VERSION ""

NS_ :

BS_:

BU_: MRRFR External_Tool CADM MRRFL

BO_ 456 MRR_FR_Header_SensorCoverage: 12 MRRFR
 SG_ MRR_FR_Radar_Spec_Status_MC : 75|4@0+ (1,0) [0|15] ""  External_Tool,CADM
 SG_ MRR_FR_Radar_Spec_Status_CRC : 87|16@0+ (1,0) [0|65535] ""  External_Tool,CADM
 SG_ MRR_CAN_RadarWaveform_FR : 79|3@0+ (1,0) [0|7] ""  CADM,External_Tool
 SG_ MRR_FR_CAN_RANGE_COVERAGE : 7|14@0+ (0.015625,0) [0|255.984375] "m"  External_Tool,CADM
 SG_ MRR_FR_CAN_DOPPLER_COVERAGE : 23|14@0+ (0.015625,0) [0|255.984375] "m/s"  External_Tool,CADM
 SG_ MRR_FR_CAN_FOV_HOR : 39|8@0+ (1,0) [0|255] "deg"  External_Tool,CADM
 SG_ MRR_FR_CAN_FOV_VER : 47|8@0+ (1,0) [0|255] "deg"  External_Tool,CADM

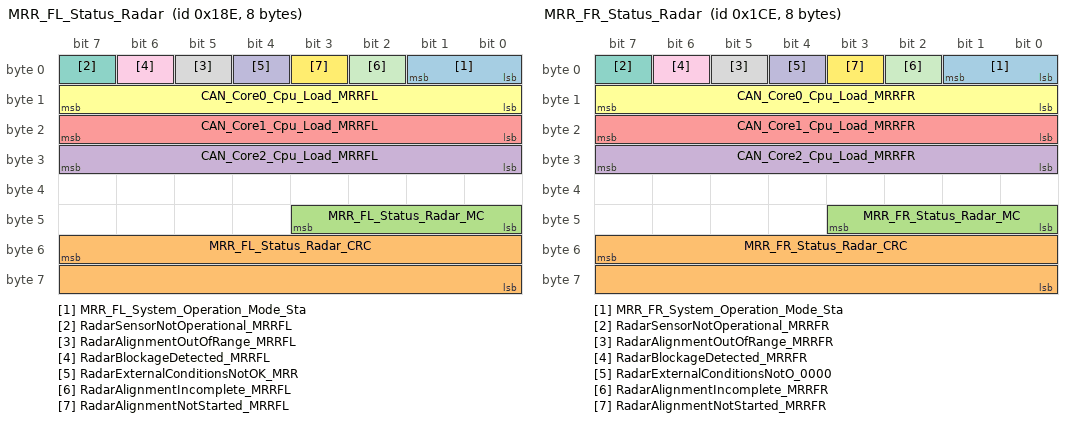
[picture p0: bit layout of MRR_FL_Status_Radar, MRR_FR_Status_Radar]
BO_ 398 MRR_FL_Status_Radar: 8 MRRFL
 SG_ MRR_FL_System_Operation_Mode_Sta : 1|2@0+ (1,0) [0|3] ""  CADM
 SG_ MRR_FL_Status_Radar_CRC : 55|16@0+ (1,0) [0|65535] ""  CADM
 SG_ MRR_FL_Status_Radar_MC : 43|4@0+ (1,0) [0|15] ""  CADM
 SG_ CAN_Core2_Cpu_Load_MRRFL : 31|8@0+ (0.5,0) [0|100] "%"  CADM
 SG_ CAN_Core1_Cpu_Load_MRRFL : 23|8@0+ (0.5,0) [0|100] "%"  CADM
 SG_ CAN_Core0_Cpu_Load_MRRFL : 15|8@0+ (0.5,0) [0|100] "%"  CADM
 SG_ RadarSensorNotOperational_MRRFL : 7|1@0+ (1,0) [0|1] ""  CADM
 SG_ RadarAlignmentOutOfRange_MRRFL : 5|1@0+ (1,0) [0|1] ""  CADM
 SG_ RadarBlockageDetected_MRRFL : 6|1@0+ (1,0) [0|1] ""  CADM
 SG_ RadarExternalConditionsNotOK_MRR : 4|1@0+ (1,0) [0|1] ""  CADM
 SG_ RadarAlignmentIncomplete_MRRFL : 2|1@0+ (1,0) [0|1] ""  CADM
 SG_ RadarAlignmentNotStarted_MRRFL : 3|1@0+ (1,0) [0|1] ""  CADM

BO_ 462 MRR_FR_Status_Radar: 8 MRRFR
 SG_ MRR_FR_System_Operation_Mode_Sta : 1|2@0+ (1,0) [0|3] ""  CADM
 SG_ MRR_FR_Status_Radar_CRC : 55|16@0+ (1,0) [0|65535] ""  CADM
 SG_ MRR_FR_Status_Radar_MC : 43|4@0+ (1,0) [0|15] ""  CADM
 SG_ CAN_Core2_Cpu_Load_MRRFR : 31|8@0+ (0.5,0) [0|100] "%"  CADM
 SG_ CAN_Core1_Cpu_Load_MRRFR : 23|8@0+ (0.5,0) [0|100] "%"  CADM
 SG_ CAN_Core0_Cpu_Load_MRRFR : 15|8@0+ (0.5,0) [0|100] "%"  CADM
 SG_ RadarSensorNotOperational_MRRFR : 7|1@0+ (1,0) [0|1] ""  CADM
 SG_ RadarAlignmentOutOfRange_MRRFR : 5|1@0+ (1,0) [0|1] ""  CADM
 SG_ RadarBlockageDetected_MRRFR : 6|1@0+ (1,0) [0|1] ""  CADM
 SG_ RadarExternalConditionsNotO_0000 : 4|1@0+ (1,0) [0|1] ""  CADM
 SG_ RadarAlignmentIncomplete_MRRFR : 2|1@0+ (1,0) [0|1] ""  CADM
 SG_ RadarAlignmentNotStarted_MRRFR : 3|1@0+ (1,0) [0|1] ""  CADM

BO_ 461 MRR_FR_Status_Temp_Volt: 12 MRRFR
 SG_ MRR_FR_CAN_Dolphin_AFC : 95|8@0+ (1,-50) [-50|205] "C"  CADM,External_Tool
 SG_ MRR_FR_CAN_Dolphin_Tx3 : 87|8@0+ (1,-50) [-50|205] "C"  CADM,External_Tool
 SG_ MRR_FR_CAN_Dolphin_Tx2 : 79|8@0+ (1,-50) [-50|205] "C"  CADM,External_Tool
 SG_ MRR_FR_CAN_1_8_V : 71|8@0+ (0.08,0) [0|20.4] "V"  External_Tool
 SG_ MRR_FR_CAN_BATT_VOLTS : 63|8@0+ (0.08,0) [0|20.4] "V"  External_Tool
 SG_ MRR_FR_CAN_1_25_V : 55|8@0+ (0.08,0) [0|20.4] "V"  External_Tool
 SG_ MRR_FR_CAN_5_V : 47|8@0+ (0.08,0) [0|20.4] "V"  External_Tool
 SG_ MRR_FR_CAN_1_1_V : 31|8@0+ (0.08,0) [0|20.4] "V"  External_Tool
 SG_ MRR_FR_CAN_2_3_V : 15|8@0+ (0.08,0) [0|20.4] "V"  External_Tool
 SG_ MRR_FR_CAN_Dolphin_Tx1 : 39|8@0+ (1,-50) [-50|205] "C"  CADM,External_Tool
 SG_ MRR_FR_CAN_RRU_Temp1 : 7|8@0+ (1,-50) [-50|205] "C"  CADM,External_Tool

BO_ 769 MRR_FL_Detection_008_014: 64 MRRFL
 SG_ MRR_FL_CAN_DET_MID_TARGET_014 : 462|1@0+ (1,0) [0|1] ""  CADM
 SG_ MRR_FL_CAN_DET_MID_TARGET_013 : 461|1@0+ (1,0) [0|1] ""  CADM
 SG_ MRR_FL_CAN_DET_MID_TARGET_012 : 460|1@0+ (1,0) [0|1] ""  CADM
 SG_ MRR_FL_CAN_DET_MID_TARGET_011 : 459|1@0+ (1,0) [0|1] ""  CADM
 SG_ MRR_FL_CAN_DET_MID_TARGET_010 : 458|1@0+ (1,0) [0|1] ""  CADM
 SG_ MRR_FL_CAN_DET_MID_TARGET_009 : 457|1@0+ (1,0) [0|1] ""  CADM
 SG_ MRR_FL_CAN_DET_MID_TARGET_008 : 456|1@0+ (1,0) [0|1] ""  CADM
 SG_ MRR_FL_CAN_DET_Near_TARGET_008 : 448|1@0+ (1,0) [0|1] ""  CADM
 SG_ MRR_FL_CAN_DET_Near_TARGET_009 : 449|1@0+ (1,0) [0|1] ""  CADM
 SG_ MRR_FL_CAN_DET_Near_TARGET_010 : 450|1@0+ (1,0) [0|1] ""  CADM
 SG_ MRR_FL_CAN_DET_Near_TARGET_011 : 451|1@0+ (1,0) [0|1] ""  CADM
 SG_ MRR_FL_CAN_DET_Near_TARGET_012 : 452|1@0+ (1,0) [0|1] ""  CADM
 SG_ MRR_FL_CAN_DET_Near_TARGET_013 : 453|1@0+ (1,0) [0|1] ""  CADM
 SG_ MRR_FL_CAN_DET_Near_TARGET_014 : 454|1@0+ (1,0) [0|1] ""  CADM
 SG_ MRR_FL_CAN_DET_ELEVATION_008 : 63|7@0+ (0.002748,-0.1745) [-0.1745|0.174496] "rad"  CADM
 SG_ MRR_FL_CAN_DET_CONFID_AZIMU_0006 : 33|2@0+ (1,0) [0|3] ""  CADM
 SG_ MRR_FL_CAN_DET_SUPER_RES_TA_0006 : 56|1@0+ (1,0) [0|1] ""  CADM
 SG_ MRR_FL_CAN_DET_CONFID_ELEVA_0006 : 49|1@0+ (1,0) [0|1] ""  CADM
 SG_ MRR_FL_CAN_DET_HOST_VEH_CLU_0006 : 48|1@0+ (1,0) [0|1] ""  CADM
 SG_ MRR_FL_CAN_DET_VALID_LEVEL_008 : 0|1@0+ (1,0) [0|1] ""  CADM
 SG_ MRR_FL_CAN_DET_AZIMUTH_008 : 47|14@0+ (0.0003834,-3.1416) [-3.1416|3.1396422] "rad"  CADM
 SG_ MRR_FL_CAN_DET_RANGE_008 : 31|14@0+ (0.015625,0) [0|255.984375] "m"  CADM
 SG_ MRR_FL_CAN_DET_RANGE_RATE_008 : 15|14@0+ (0.015625,-128) [-128|127.984375] "m/s"  CADM
 SG_ MRR_FL_CAN_DET_AMPLITUDE_008 : 7|7@0+ (1,-64) [-64|63] "dBsm"  CADM
 SG_ MRR_FL_CAN_SCAN_INDEX_2LSB_008 : 17|2@0+ (1,0) [0|3] ""  CADM
 SG_ MRR_FL_DET_MC_002 : 491|4@0+ (1,0) [0|15] ""  CADM
 SG_ MRR_FL_DET_CRC_002 : 503|16@0+ (1,0) [0|65535] ""  CADM
 SG_ MRR_FL_CAN_DET_ELEVATION_014 : 447|7@0+ (0.002748,-0.1745) [-0.1745|0.174496] "rad"  CADM
 SG_ MRR_FL_CAN_DET_SUPER_RES_TA_0007 : 440|1@0+ (1,0) [0|1] ""  CADM
 SG_ MRR_FL_CAN_DET_AZIMUTH_014 : 431|14@0+ (0.0003834,-3.1416) [-3.1416|3.1396422] "rad"  CADM
 SG_ MRR_FL_CAN_DET_CONFID_ELEVA_0007 : 433|1@0+ (1,0) [0|1] ""  CADM
 SG_ MRR_FL_CAN_DET_HOST_VEH_CLU_0007 : 432|1@0+ (1,0) [0|1] ""  CADM
 SG_ MRR_FL_CAN_DET_RANGE_014 : 415|14@0+ (0.015625,0) [0|255.984375] "m"  CADM
 SG_ MRR_FL_CAN_DET_CONFID_AZIMUTH_01 : 417|2@0+ (1,0) [0|3] ""  CADM
 SG_ MRR_FL_CAN_DET_RANGE_RATE_014 : 399|14@0+ (0.015625,-128) [-128|127.984375] "m/s"  CADM
 SG_ MRR_FL_CAN_SCAN_INDEX_2LSB_014 : 401|2@0+ (1,0) [0|3] ""  CADM
 SG_ MRR_FL_CAN_DET_AMPLITUDE_014 : 391|7@0+ (1,-64) [-64|63] "dBsm"  CADM
 SG_ MRR_FL_CAN_DET_VALID_LEVEL_014 : 384|1@0+ (1,0) [0|1] ""  CADM
 SG_ MRR_FL_CAN_DET_ELEVATION_013 : 383|7@0+ (0.002748,-0.1745) [-0.1745|0.174496] "rad"  CADM
 SG_ MRR_FL_CAN_DET_SUPER_RES_TA_0008 : 376|1@0+ (1,0) [0|1] ""  CADM
 SG_ MRR_FL_CAN_DET_AZIMUTH_013 : 367|14@0+ (0.0003834,-3.1416) [-3.1416|3.1396422] "rad"  CADM
 SG_ MRR_FL_CAN_DET_CONFID_ELEVA_0008 : 369|1@0+ (1,0) [0|1] ""  CADM
 SG_ MRR_FL_CAN_DET_HOST_VEH_CLU_0008 : 368|1@0+ (1,0) [0|1] ""  CADM
 SG_ MRR_FL_CAN_DET_RANGE_013 : 351|14@0+ (0.015625,0) [0|255.984375] "m"  CADM
 SG_ MRR_FL_CAN_DET_CONFID_AZIMU_0007 : 353|2@0+ (1,0) [0|3] ""  CADM
 SG_ MRR_FL_CAN_DET_RANGE_RATE_013 : 335|14@0+ (0.015625,-128) [-128|127.984375] "m/s"  CADM
 SG_ MRR_FL_CAN_SCAN_INDEX_2LSB_013 : 337|2@0+ (1,0) [0|3] ""  CADM
 SG_ MRR_FL_CAN_DET_AMPLITUDE_013 : 327|7@0+ (1,-64) [-64|63] "dBsm"  CADM
 SG_ MRR_FL_CAN_DET_VALID_LEVEL_013 : 320|1@0+ (1,0) [0|1] ""  CADM
 SG_ MRR_FL_CAN_DET_ELEVATION_012 : 319|7@0+ (0.002748,-0.1745) [-0.1745|0.174496] "rad"  CADM
 SG_ MRR_FL_CAN_DET_SUPER_RES_TA_0009 : 312|1@0+ (1,0) [0|1] ""  CADM
 SG_ MRR_FL_CAN_DET_AZIMUTH_012 : 303|14@0+ (0.0003834,-3.1416) [-3.1416|3.1396422] "rad"  CADM
 SG_ MRR_FL_CAN_DET_CONFID_ELEVA_0009 : 305|1@0+ (1,0) [0|1] ""  CADM
 SG_ MRR_FL_CAN_DET_HOST_VEH_CLU_0009 : 304|1@0+ (1,0) [0|1] ""  CADM
 SG_ MRR_FL_CAN_DET_RANGE_012 : 287|14@0+ (0.015625,0) [0|255.984375] "m"  CADM
 SG_ MRR_FL_CAN_DET_CONFID_AZIMU_0008 : 289|2@0+ (1,0) [0|3] ""  CADM
 SG_ MRR_FL_CAN_DET_RANGE_RATE_012 : 271|14@0+ (0.015625,-128) [-128|127.984375] "m/s"  CADM
 SG_ MRR_FL_CAN_SCAN_INDEX_2LSB_012 : 273|2@0+ (1,0) [0|3] ""  CADM
 SG_ MRR_FL_CAN_DET_AMPLITUDE_012 : 263|7@0+ (1,-64) [-64|63] "dBsm"  CADM
 SG_ MRR_FL_CAN_DET_VALID_LEVEL_012 : 256|1@0+ (1,0) [0|1] ""  CADM
 SG_ MRR_FL_CAN_DET_ELEVATION_011 : 255|7@0+ (0.002748,-0.1745) [-0.1745|0.174496] "rad"  CADM
 SG_ MRR_FL_CAN_DET_SUPER_RES_TA_0010 : 248|1@0+ (1,0) [0|1] ""  CADM
 SG_ MRR_FL_CAN_DET_AZIMUTH_011 : 239|14@0+ (0.0003834,-3.1416) [-3.1416|3.1396422] "rad"  CADM
 SG_ MRR_FL_CAN_DET_CONFID_ELEVA_0010 : 241|1@0+ (1,0) [0|1] ""  CADM
 SG_ MRR_FL_CAN_DET_HOST_VEH_CLU_0010 : 240|1@0+ (1,0) [0|1] ""  CADM
 SG_ MRR_FL_CAN_DET_RANGE_011 : 223|14@0+ (0.015625,0) [0|255.984375] "m"  CADM
 SG_ MRR_FL_CAN_DET_CONFID_AZIMU_0009 : 225|2@0+ (1,0) [0|3] ""  CADM
 SG_ MRR_FL_CAN_DET_RANGE_RATE_011 : 207|14@0+ (0.015625,-128) [-128|127.984375] "m/s"  CADM
 SG_ MRR_FL_CAN_SCAN_INDEX_2LSB_011 : 209|2@0+ (1,0) [0|3] ""  CADM
 SG_ MRR_FL_CAN_DET_AMPLITUDE_011 : 199|7@0+ (1,-64) [-64|63] "dBsm"  CADM
 SG_ MRR_FL_CAN_DET_VALID_LEVEL_011 : 192|1@0+ (1,0) [0|1] ""  CADM
 SG_ MRR_FL_CAN_DET_ELEVATION_010 : 191|7@0+ (0.002748,-0.1745) [-0.1745|0.174496] "rad"  CADM
 SG_ MRR_FL_CAN_DET_SUPER_RES_TA_0011 : 184|1@0+ (1,0) [0|1] ""  CADM
 SG_ MRR_FL_CAN_DET_AZIMUTH_010 : 175|14@0+ (0.0003834,-3.1416) [-3.1416|3.1396422] "rad"  CADM
 SG_ MRR_FL_CAN_DET_CONFID_ELEVA_0011 : 177|1@0+ (1,0) [0|1] ""  CADM
 SG_ MRR_FL_CAN_DET_HOST_VEH_CLU_0011 : 176|1@0+ (1,0) [0|1] ""  CADM
 SG_ MRR_FL_CAN_DET_RANGE_010 : 159|14@0+ (0.015625,0) [0|255.984375] "m"  CADM
 SG_ MRR_FL_CAN_DET_CONFID_AZIMU_0010 : 161|2@0+ (1,0) [0|3] ""  CADM
 SG_ MRR_FL_CAN_DET_RANGE_RATE_010 : 143|14@0+ (0.015625,-128) [-128|127.984375] "m/s"  CADM
 SG_ MRR_FL_CAN_SCAN_INDEX_2LSB_010 : 145|2@0+ (1,0) [0|3] ""  CADM
 SG_ MRR_FL_CAN_DET_AMPLITUDE_010 : 135|7@0+ (1,-64) [-64|63] "dBsm"  CADM
 SG_ MRR_FL_CAN_DET_VALID_LEVEL_010 : 128|1@0+ (1,0) [0|1] ""  CADM
 SG_ MRR_FL_CAN_DET_ELEVATION_009 : 127|7@0+ (0.002748,-0.1745) [-0.1745|0.174496] "rad"  CADM
 SG_ MRR_FL_CAN_DET_SUPER_RES_TA_0012 : 120|1@0+ (1,0) [0|1] ""  CADM
 SG_ MRR_FL_CAN_DET_AZIMUTH_009 : 111|14@0+ (0.0003834,-3.1416) [-3.1416|3.1396422] "rad"  CADM
 SG_ MRR_FL_CAN_DET_CONFID_ELEVA_0012 : 113|1@0+ (1,0) [0|1] ""  CADM
 SG_ MRR_FL_CAN_DET_HOST_VEH_CLU_0012 : 112|1@0+ (1,0) [0|1] ""  CADM
 SG_ MRR_FL_CAN_DET_RANGE_009 : 95|14@0+ (0.015625,0) [0|255.984375] "m"  CADM
 SG_ MRR_FL_CAN_DET_CONFID_AZIMU_0011 : 97|2@0+ (1,0) [0|3] ""  CADM
 SG_ MRR_FL_CAN_DET_RANGE_RATE_009 : 79|14@0+ (0.015625,-128) [-128|127.984375] "m/s"  CADM
 SG_ MRR_FL_CAN_SCAN_INDEX_2LSB_009 : 81|2@0+ (1,0) [0|3] ""  CADM
 SG_ MRR_FL_CAN_DET_AMPLITUDE_009 : 71|7@0+ (1,-64) [-64|63] "dBsm"  CADM
 SG_ MRR_FL_CAN_DET_VALID_LEVEL_009 : 64|1@0+ (1,0) [0|1] ""  CADM

BO_ 770 MRR_FL_Detection_015_021: 64 MRRFL
 SG_ MRR_FL_CAN_DET_MID_TARGET_021 : 462|1@0+ (1,0) [0|1] ""  CADM
 SG_ MRR_FL_CAN_DET_MID_TARGET_020 : 461|1@0+ (1,0) [0|1] ""  CADM
 SG_ MRR_FL_CAN_DET_MID_TARGET_019 : 460|1@0+ (1,0) [0|1] ""  CADM
 SG_ MRR_FL_CAN_DET_MID_TARGET_018 : 459|1@0+ (1,0) [0|1] ""  CADM
 SG_ MRR_FL_CAN_DET_MID_TARGET_017 : 458|1@0+ (1,0) [0|1] ""  CADM
 SG_ MRR_FL_CAN_DET_MID_TARGET_016 : 457|1@0+ (1,0) [0|1] ""  CADM
 SG_ MRR_FL_CAN_DET_MID_TARGET_015 : 456|1@0+ (1,0) [0|1] ""  CADM
 SG_ MRR_FL_CAN_DET_Near_TARGET_015 : 448|1@0+ (1,0) [0|1] ""  CADM
 SG_ MRR_FL_CAN_DET_Near_TARGET_016 : 449|1@0+ (1,0) [0|1] ""  CADM
 SG_ MRR_FL_CAN_DET_Near_TARGET_017 : 450|1@0+ (1,0) [0|1] ""  CADM
 SG_ MRR_FL_CAN_DET_Near_TARGET_018 : 451|1@0+ (1,0) [0|1] ""  CADM
 SG_ MRR_FL_CAN_DET_Near_TARGET_019 : 452|1@0+ (1,0) [0|1] ""  CADM
 SG_ MRR_FL_CAN_DET_Near_TARGET_020 : 453|1@0+ (1,0) [0|1] ""  CADM
 SG_ MRR_FL_CAN_DET_Near_TARGET_021 : 454|1@0+ (1,0) [0|1] ""  CADM
 SG_ MRR_FL_CAN_DET_ELEVATION_015 : 63|7@0+ (0.002748,-0.1745) [-0.1745|0.174496] "rad"  CADM
 SG_ MRR_FL_CAN_DET_CONFID_AZIMU_0012 : 33|2@0+ (1,0) [0|3] ""  CADM
 SG_ MRR_FL_CAN_DET_SUPER_RES_TA_0013 : 56|1@0+ (1,0) [0|1] ""  CADM
 SG_ MRR_FL_CAN_DET_CONFID_ELEVA_0013 : 49|1@0+ (1,0) [0|1] ""  CADM
 SG_ MRR_FL_CAN_DET_HOST_VEH_CLU_0013 : 48|1@0+ (1,0) [0|1] ""  CADM
 SG_ MRR_FL_CAN_DET_VALID_LEVEL_015 : 0|1@0+ (1,0) [0|1] ""  CADM
 SG_ MRR_FL_CAN_DET_AZIMUTH_015 : 47|14@0+ (0.0003834,-3.1416) [-3.1416|3.1396422] "rad"  CADM
 SG_ MRR_FL_CAN_DET_RANGE_015 : 31|14@0+ (0.015625,0) [0|255.984375] "m"  CADM
 SG_ MRR_FL_CAN_DET_RANGE_RATE_015 : 15|14@0+ (0.015625,-128) [-128|127.984375] "m/s"  CADM
 SG_ MRR_FL_CAN_DET_AMPLITUDE_015 : 7|7@0+ (1,-64) [-64|63] "dBsm"  CADM
 SG_ MRR_FL_CAN_SCAN_INDEX_2LSB_015 : 17|2@0+ (1,0) [0|3] ""  CADM
 SG_ MRR_FL_DET_MC_003 : 491|4@0+ (1,0) [0|15] ""  CADM
 SG_ MRR_FL_DET_CRC_003 : 503|16@0+ (1,0) [0|65535] ""  CADM
 SG_ MRR_FL_CAN_DET_ELEVATION_021 : 447|7@0+ (0.002748,-0.1745) [-0.1745|0.174496] "rad"  CADM
 SG_ MRR_FL_CAN_DET_SUPER_RES_TA_0014 : 440|1@0+ (1,0) [0|1] ""  CADM
 SG_ MRR_FL_CAN_DET_AZIMUTH_021 : 431|14@0+ (0.0003834,-3.1416) [-3.1416|3.1396422] "rad"  CADM
 SG_ MRR_FL_CAN_DET_CONFID_ELEVA_0014 : 433|1@0+ (1,0) [0|1] ""  CADM
 SG_ MRR_FL_CAN_DET_HOST_VEH_CLU_0014 : 432|1@0+ (1,0) [0|1] ""  CADM
 SG_ MRR_FL_CAN_DET_RANGE_021 : 415|14@0+ (0.015625,0) [0|255.984375] "m"  CADM
 SG_ MRR_FL_CAN_DET_CONFID_AZIMUTH_02 : 417|2@0+ (1,0) [0|3] ""  CADM
 SG_ MRR_FL_CAN_DET_RANGE_RATE_021 : 399|14@0+ (0.015625,-128) [-128|127.984375] "m/s"  CADM
 SG_ MRR_FL_CAN_SCAN_INDEX_2LSB_021 : 401|2@0+ (1,0) [0|3] ""  CADM
 SG_ MRR_FL_CAN_DET_AMPLITUDE_021 : 391|7@0+ (1,-64) [-64|63] "dBsm"  CADM
 SG_ MRR_FL_CAN_DET_VALID_LEVEL_021 : 384|1@0+ (1,0) [0|1] ""  CADM
 SG_ MRR_FL_CAN_DET_ELEVATION_020 : 383|7@0+ (0.002748,-0.1745) [-0.1745|0.174496] "rad"  CADM
 SG_ MRR_FL_CAN_DET_SUPER_RES_TA_0015 : 376|1@0+ (1,0) [0|1] ""  CADM
 SG_ MRR_FL_CAN_DET_AZIMUTH_020 : 367|14@0+ (0.0003834,-3.1416) [-3.1416|3.1396422] "rad"  CADM
 SG_ MRR_FL_CAN_DET_CONFID_ELEVA_0015 : 369|1@0+ (1,0) [0|1] ""  CADM
 SG_ MRR_FL_CAN_DET_HOST_VEH_CLU_0015 : 368|1@0+ (1,0) [0|1] ""  CADM
 SG_ MRR_FL_CAN_DET_RANGE_020 : 351|14@0+ (0.015625,0) [0|255.984375] "m"  CADM
 SG_ MRR_FL_CAN_DET_CONFID_AZIMU_0013 : 353|2@0+ (1,0) [0|3] ""  CADM
 SG_ MRR_FL_CAN_DET_RANGE_RATE_020 : 335|14@0+ (0.015625,-128) [-128|127.984375] "m/s"  CADM
 SG_ MRR_FL_CAN_SCAN_INDEX_2LSB_020 : 337|2@0+ (1,0) [0|3] ""  CADM
 SG_ MRR_FL_CAN_DET_AMPLITUDE_020 : 327|7@0+ (1,-64) [-64|63] "dBsm"  CADM
 SG_ MRR_FL_CAN_DET_VALID_LEVEL_020 : 320|1@0+ (1,0) [0|1] ""  CADM
 SG_ MRR_FL_CAN_DET_ELEVATION_019 : 319|7@0+ (0.002748,-0.1745) [-0.1745|0.174496] "rad"  CADM
 SG_ MRR_FL_CAN_DET_SUPER_RES_TA_0016 : 312|1@0+ (1,0) [0|1] ""  CADM
 SG_ MRR_FL_CAN_DET_AZIMUTH_019 : 303|14@0+ (0.0003834,-3.1416) [-3.1416|3.1396422] "rad"  CADM
 SG_ MRR_FL_CAN_DET_CONFID_ELEVA_0016 : 305|1@0+ (1,0) [0|1] ""  CADM
 SG_ MRR_FL_CAN_DET_HOST_VEH_CLU_0016 : 304|1@0+ (1,0) [0|1] ""  CADM
 SG_ MRR_FL_CAN_DET_RANGE_019 : 287|14@0+ (0.015625,0) [0|255.984375] "m"  CADM
 SG_ MRR_FL_CAN_DET_CONFID_AZIMU_0014 : 289|2@0+ (1,0) [0|3] ""  CADM
 SG_ MRR_FL_CAN_DET_RANGE_RATE_019 : 271|14@0+ (0.015625,-128) [-128|127.984375] "m/s"  CADM
 SG_ MRR_FL_CAN_SCAN_INDEX_2LSB_019 : 273|2@0+ (1,0) [0|3] ""  CADM
 SG_ MRR_FL_CAN_DET_AMPLITUDE_019 : 263|7@0+ (1,-64) [-64|63] "dBsm"  CADM
 SG_ MRR_FL_CAN_DET_VALID_LEVEL_019 : 256|1@0+ (1,0) [0|1] ""  CADM
 SG_ MRR_FL_CAN_DET_ELEVATION_018 : 255|7@0+ (0.002748,-0.1745) [-0.1745|0.174496] "rad"  CADM
 SG_ MRR_FL_CAN_DET_SUPER_RES_TA_0017 : 248|1@0+ (1,0) [0|1] ""  CADM
 SG_ MRR_FL_CAN_DET_AZIMUTH_018 : 239|14@0+ (0.0003834,-3.1416) [-3.1416|3.1396422] "rad"  CADM
 SG_ MRR_FL_CAN_DET_CONFID_ELEVA_0017 : 241|1@0+ (1,0) [0|1] ""  CADM
 SG_ MRR_FL_CAN_DET_HOST_VEH_CLU_0017 : 240|1@0+ (1,0) [0|1] ""  CADM
 SG_ MRR_FL_CAN_DET_RANGE_018 : 223|14@0+ (0.015625,0) [0|255.984375] "m"  CADM
 SG_ MRR_FL_CAN_DET_CONFID_AZIMU_0015 : 225|2@0+ (1,0) [0|3] ""  CADM
 SG_ MRR_FL_CAN_DET_RANGE_RATE_018 : 207|14@0+ (0.015625,-128) [-128|127.984375] "m/s"  CADM
 SG_ MRR_FL_CAN_SCAN_INDEX_2LSB_018 : 209|2@0+ (1,0) [0|3] ""  CADM
 SG_ MRR_FL_CAN_DET_AMPLITUDE_018 : 199|7@0+ (1,-64) [-64|63] "dBsm"  CADM
 SG_ MRR_FL_CAN_DET_VALID_LEVEL_018 : 192|1@0+ (1,0) [0|1] ""  CADM
 SG_ MRR_FL_CAN_DET_ELEVATION_017 : 191|7@0+ (0.002748,-0.1745) [-0.1745|0.174496] "rad"  CADM
 SG_ MRR_FL_CAN_DET_SUPER_RES_TA_0018 : 184|1@0+ (1,0) [0|1] ""  CADM
 SG_ MRR_FL_CAN_DET_AZIMUTH_017 : 175|14@0+ (0.0003834,-3.1416) [-3.1416|3.1396422] "rad"  CADM
 SG_ MRR_FL_CAN_DET_CONFID_ELEVA_0018 : 177|1@0+ (1,0) [0|1] ""  CADM
 SG_ MRR_FL_CAN_DET_HOST_VEH_CLU_0018 : 176|1@0+ (1,0) [0|1] ""  CADM
 SG_ MRR_FL_CAN_DET_RANGE_017 : 159|14@0+ (0.015625,0) [0|255.984375] "m"  CADM
 SG_ MRR_FL_CAN_DET_CONFID_AZIMU_0016 : 161|2@0+ (1,0) [0|3] ""  CADM
 SG_ MRR_FL_CAN_DET_RANGE_RATE_017 : 143|14@0+ (0.015625,-128) [-128|127.984375] "m/s"  CADM
 SG_ MRR_FL_CAN_SCAN_INDEX_2LSB_017 : 145|2@0+ (1,0) [0|3] ""  CADM
 SG_ MRR_FL_CAN_DET_AMPLITUDE_017 : 135|7@0+ (1,-64) [-64|63] "dBsm"  CADM
 SG_ MRR_FL_CAN_DET_VALID_LEVEL_017 : 128|1@0+ (1,0) [0|1] ""  CADM
 SG_ MRR_FL_CAN_DET_ELEVATION_016 : 127|7@0+ (0.002748,-0.1745) [-0.1745|0.174496] "rad"  CADM
 SG_ MRR_FL_CAN_DET_SUPER_RES_TA_0019 : 120|1@0+ (1,0) [0|1] ""  CADM
 SG_ MRR_FL_CAN_DET_AZIMUTH_016 : 111|14@0+ (0.0003834,-3.1416) [-3.1416|3.1396422] "rad"  CADM
 SG_ MRR_FL_CAN_DET_CONFID_ELEVA_0019 : 113|1@0+ (1,0) [0|1] ""  CADM
 SG_ MRR_FL_CAN_DET_HOST_VEH_CLU_0019 : 112|1@0+ (1,0) [0|1] ""  CADM
 SG_ MRR_FL_CAN_DET_RANGE_016 : 95|14@0+ (0.015625,0) [0|255.984375] "m"  CADM
 SG_ MRR_FL_CAN_DET_CONFID_AZIMU_0017 : 97|2@0+ (1,0) [0|3] ""  CADM
 SG_ MRR_FL_CAN_DET_RANGE_RATE_016 : 79|14@0+ (0.015625,-128) [-128|127.984375] "m/s"  CADM
 SG_ MRR_FL_CAN_SCAN_INDEX_2LSB_016 : 81|2@0+ (1,0) [0|3] ""  CADM
 SG_ MRR_FL_CAN_DET_AMPLITUDE_016 : 71|7@0+ (1,-64) [-64|63] "dBsm"  CADM
 SG_ MRR_FL_CAN_DET_VALID_LEVEL_016 : 64|1@0+ (1,0) [0|1] ""  CADM

BO_ 771 MRR_FL_Detection_022_028: 64 MRRFL
 SG_ MRR_FL_CAN_DET_MID_TARGET_028 : 462|1@0+ (1,0) [0|1] ""  CADM
 SG_ MRR_FL_CAN_DET_MID_TARGET_027 : 461|1@0+ (1,0) [0|1] ""  CADM
 SG_ MRR_FL_CAN_DET_MID_TARGET_026 : 460|1@0+ (1,0) [0|1] ""  CADM
 SG_ MRR_FL_CAN_DET_MID_TARGET_025 : 459|1@0+ (1,0) [0|1] ""  CADM
 SG_ MRR_FL_CAN_DET_MID_TARGET_024 : 458|1@0+ (1,0) [0|1] ""  CADM
 SG_ MRR_FL_CAN_DET_MID_TARGET_023 : 457|1@0+ (1,0) [0|1] ""  CADM
 SG_ MRR_FL_CAN_DET_MID_TARGET_022 : 456|1@0+ (1,0) [0|1] ""  CADM
 SG_ MRR_FL_CAN_DET_Near_TARGET_022 : 448|1@0+ (1,0) [0|1] ""  CADM
 SG_ MRR_FL_CAN_DET_Near_TARGET_023 : 449|1@0+ (1,0) [0|1] ""  CADM
 SG_ MRR_FL_CAN_DET_Near_TARGET_024 : 450|1@0+ (1,0) [0|1] ""  CADM
 SG_ MRR_FL_CAN_DET_Near_TARGET_025 : 451|1@0+ (1,0) [0|1] ""  CADM
 SG_ MRR_FL_CAN_DET_Near_TARGET_026 : 452|1@0+ (1,0) [0|1] ""  CADM
 SG_ MRR_FL_CAN_DET_Near_TARGET_027 : 453|1@0+ (1,0) [0|1] ""  CADM
 SG_ MRR_FL_CAN_DET_Near_TARGET_028 : 454|1@0+ (1,0) [0|1] ""  CADM
 SG_ MRR_FL_CAN_DET_ELEVATION_022 : 63|7@0+ (0.002748,-0.1745) [-0.1745|0.174496] "rad"  CADM
 SG_ MRR_FL_CAN_DET_CONFID_AZIMU_0018 : 33|2@0+ (1,0) [0|3] ""  CADM
 SG_ MRR_FL_CAN_DET_SUPER_RES_TA_0020 : 56|1@0+ (1,0) [0|1] ""  CADM
 SG_ MRR_FL_CAN_DET_CONFID_ELEVA_0020 : 49|1@0+ (1,0) [0|1] ""  CADM
 SG_ MRR_FL_CAN_DET_HOST_VEH_CLU_0020 : 48|1@0+ (1,0) [0|1] ""  CADM
 SG_ MRR_FL_CAN_DET_VALID_LEVEL_022 : 0|1@0+ (1,0) [0|1] ""  CADM
 SG_ MRR_FL_CAN_DET_AZIMUTH_022 : 47|14@0+ (0.0003834,-3.1416) [-3.1416|3.1396422] "rad"  CADM
 SG_ MRR_FL_CAN_DET_RANGE_022 : 31|14@0+ (0.015625,0) [0|255.984375] "m"  CADM
 SG_ MRR_FL_CAN_DET_RANGE_RATE_022 : 15|14@0+ (0.015625,-128) [-128|127.984375] "m/s"  CADM
 SG_ MRR_FL_CAN_DET_AMPLITUDE_022 : 7|7@0+ (1,-64) [-64|63] "dBsm"  CADM
 SG_ MRR_FL_CAN_SCAN_INDEX_2LSB_022 : 17|2@0+ (1,0) [0|3] ""  CADM
 SG_ MRR_FL_DET_MC_004 : 491|4@0+ (1,0) [0|15] ""  CADM
 SG_ MRR_FL_DET_CRC_004 : 503|16@0+ (1,0) [0|65535] ""  CADM
 SG_ MRR_FL_CAN_DET_ELEVATION_028 : 447|7@0+ (0.002748,-0.1745) [-0.1745|0.174496] "rad"  CADM
 SG_ MRR_FL_CAN_DET_SUPER_RES_TA_0021 : 440|1@0+ (1,0) [0|1] ""  CADM
 SG_ MRR_FL_CAN_DET_AZIMUTH_028 : 431|14@0+ (0.0003834,-3.1416) [-3.1416|3.1396422] "rad"  CADM
 SG_ MRR_FL_CAN_DET_CONFID_ELEVA_0021 : 433|1@0+ (1,0) [0|1] ""  CADM
 SG_ MRR_FL_CAN_DET_HOST_VEH_CLU_0021 : 432|1@0+ (1,0) [0|1] ""  CADM
 SG_ MRR_FL_CAN_DET_RANGE_028 : 415|14@0+ (0.015625,0) [0|255.984375] "m"  CADM
 SG_ MRR_FL_CAN_DET_CONFID_AZIMU_0019 : 417|2@0+ (1,0) [0|3] ""  CADM
 SG_ MRR_FL_CAN_DET_RANGE_RATE_028 : 399|14@0+ (0.015625,-128) [-128|127.984375] "m/s"  CADM
 SG_ MRR_FL_CAN_SCAN_INDEX_2LSB_028 : 401|2@0+ (1,0) [0|3] ""  CADM
 SG_ MRR_FL_CAN_DET_AMPLITUDE_028 : 391|7@0+ (1,-64) [-64|63] "dBsm"  CADM
 SG_ MRR_FL_CAN_DET_VALID_LEVEL_028 : 384|1@0+ (1,0) [0|1] ""  CADM
 SG_ MRR_FL_CAN_DET_ELEVATION_027 : 383|7@0+ (0.002748,-0.1745) [-0.1745|0.174496] "rad"  CADM
 SG_ MRR_FL_CAN_DET_SUPER_RES_TA_0022 : 376|1@0+ (1,0) [0|1] ""  CADM
 SG_ MRR_FL_CAN_DET_AZIMUTH_027 : 367|14@0+ (0.0003834,-3.1416) [-3.1416|3.1396422] "rad"  CADM
 SG_ MRR_FL_CAN_DET_CONFID_ELEVA_0022 : 369|1@0+ (1,0) [0|1] ""  CADM
 SG_ MRR_FL_CAN_DET_HOST_VEH_CLU_0022 : 368|1@0+ (1,0) [0|1] ""  CADM
 SG_ MRR_FL_CAN_DET_RANGE_027 : 351|14@0+ (0.015625,0) [0|255.984375] "m"  CADM
 SG_ MRR_FL_CAN_DET_CONFID_AZIMU_0020 : 353|2@0+ (1,0) [0|3] ""  CADM
 SG_ MRR_FL_CAN_DET_RANGE_RATE_027 : 335|14@0+ (0.015625,-128) [-128|127.984375] "m/s"  CADM
 SG_ MRR_FL_CAN_SCAN_INDEX_2LSB_027 : 337|2@0+ (1,0) [0|3] ""  CADM
 SG_ MRR_FL_CAN_DET_AMPLITUDE_027 : 327|7@0+ (1,-64) [-64|63] "dBsm"  CADM
 SG_ MRR_FL_CAN_DET_VALID_LEVEL_027 : 320|1@0+ (1,0) [0|1] ""  CADM
 SG_ MRR_FL_CAN_DET_ELEVATION_026 : 319|7@0+ (0.002748,-0.1745) [-0.1745|0.174496] "rad"  CADM
 SG_ MRR_FL_CAN_DET_SUPER_RES_TA_0023 : 312|1@0+ (1,0) [0|1] ""  CADM
 SG_ MRR_FL_CAN_DET_AZIMUTH_026 : 303|14@0+ (0.0003834,-3.1416) [-3.1416|3.1396422] "rad"  CADM
 SG_ MRR_FL_CAN_DET_CONFID_ELEVA_0023 : 305|1@0+ (1,0) [0|1] ""  CADM
 SG_ MRR_FL_CAN_DET_HOST_VEH_CLU_0023 : 304|1@0+ (1,0) [0|1] ""  CADM
 SG_ MRR_FL_CAN_DET_RANGE_026 : 287|14@0+ (0.015625,0) [0|255.984375] "m"  CADM
 SG_ MRR_FL_CAN_DET_CONFID_AZIMU_0021 : 289|2@0+ (1,0) [0|3] ""  CADM
 SG_ MRR_FL_CAN_DET_RANGE_RATE_026 : 271|14@0+ (0.015625,-128) [-128|127.984375] "m/s"  CADM
 SG_ MRR_FL_CAN_SCAN_INDEX_2LSB_026 : 273|2@0+ (1,0) [0|3] ""  CADM
 SG_ MRR_FL_CAN_DET_AMPLITUDE_026 : 263|7@0+ (1,-64) [-64|63] "dBsm"  CADM
 SG_ MRR_FL_CAN_DET_VALID_LEVEL_026 : 256|1@0+ (1,0) [0|1] ""  CADM
 SG_ MRR_FL_CAN_DET_ELEVATION_025 : 255|7@0+ (0.002748,-0.1745) [-0.1745|0.174496] "rad"  CADM
 SG_ MRR_FL_CAN_DET_SUPER_RES_TA_0024 : 248|1@0+ (1,0) [0|1] ""  CADM
 SG_ MRR_FL_CAN_DET_AZIMUTH_025 : 239|14@0+ (0.0003834,-3.1416) [-3.1416|3.1396422] "rad"  CADM
 SG_ MRR_FL_CAN_DET_CONFID_ELEVA_0024 : 241|1@0+ (1,0) [0|1] ""  CADM
 SG_ MRR_FL_CAN_DET_HOST_VEH_CLU_0024 : 240|1@0+ (1,0) [0|1] ""  CADM
 SG_ MRR_FL_CAN_DET_RANGE_025 : 223|14@0+ (0.015625,0) [0|255.984375] "m"  CADM
 SG_ MRR_FL_CAN_DET_CONFID_AZIMU_0022 : 225|2@0+ (1,0) [0|3] ""  CADM
 SG_ MRR_FL_CAN_DET_RANGE_RATE_025 : 207|14@0+ (0.015625,-128) [-128|127.984375] "m/s"  CADM
 SG_ MRR_FL_CAN_SCAN_INDEX_2LSB_025 : 209|2@0+ (1,0) [0|3] ""  CADM
 SG_ MRR_FL_CAN_DET_AMPLITUDE_025 : 199|7@0+ (1,-64) [-64|63] "dBsm"  CADM
 SG_ MRR_FL_CAN_DET_VALID_LEVEL_025 : 192|1@0+ (1,0) [0|1] ""  CADM
 SG_ MRR_FL_CAN_DET_ELEVATION_024 : 191|7@0+ (0.002748,-0.1745) [-0.1745|0.174496] "rad"  CADM
 SG_ MRR_FL_CAN_DET_SUPER_RES_TA_0025 : 184|1@0+ (1,0) [0|1] ""  CADM
 SG_ MRR_FL_CAN_DET_AZIMUTH_024 : 175|14@0+ (0.0003834,-3.1416) [-3.1416|3.1396422] "rad"  CADM
 SG_ MRR_FL_CAN_DET_CONFID_ELEVA_0025 : 177|1@0+ (1,0) [0|1] ""  CADM
 SG_ MRR_FL_CAN_DET_HOST_VEH_CLU_0025 : 176|1@0+ (1,0) [0|1] ""  CADM
 SG_ MRR_FL_CAN_DET_RANGE_024 : 159|14@0+ (0.015625,0) [0|255.984375] "m"  CADM
 SG_ MRR_FL_CAN_DET_CONFID_AZIMU_0023 : 161|2@0+ (1,0) [0|3] ""  CADM
 SG_ MRR_FL_CAN_DET_RANGE_RATE_024 : 143|14@0+ (0.015625,-128) [-128|127.984375] "m/s"  CADM
 SG_ MRR_FL_CAN_SCAN_INDEX_2LSB_024 : 145|2@0+ (1,0) [0|3] ""  CADM
 SG_ MRR_FL_CAN_DET_AMPLITUDE_024 : 135|7@0+ (1,-64) [-64|63] "dBsm"  CADM
 SG_ MRR_FL_CAN_DET_VALID_LEVEL_024 : 128|1@0+ (1,0) [0|1] ""  CADM
 SG_ MRR_FL_CAN_DET_ELEVATION_023 : 127|7@0+ (0.002748,-0.1745) [-0.1745|0.174496] "rad"  CADM
 SG_ MRR_FL_CAN_DET_SUPER_RES_TA_0026 : 120|1@0+ (1,0) [0|1] ""  CADM
 SG_ MRR_FL_CAN_DET_AZIMUTH_023 : 111|14@0+ (0.0003834,-3.1416) [-3.1416|3.1396422] "rad"  CADM
 SG_ MRR_FL_CAN_DET_CONFID_ELEVA_0026 : 113|1@0+ (1,0) [0|1] ""  CADM
 SG_ MRR_FL_CAN_DET_HOST_VEH_CLU_0026 : 112|1@0+ (1,0) [0|1] ""  CADM
 SG_ MRR_FL_CAN_DET_RANGE_023 : 95|14@0+ (0.015625,0) [0|255.984375] "m"  CADM
 SG_ MRR_FL_CAN_DET_CONFID_AZIMU_0024 : 97|2@0+ (1,0) [0|3] ""  CADM
 SG_ MRR_FL_CAN_DET_RANGE_RATE_023 : 79|14@0+ (0.015625,-128) [-128|127.984375] "m/s"  CADM
 SG_ MRR_FL_CAN_SCAN_INDEX_2LSB_023 : 81|2@0+ (1,0) [0|3] ""  CADM
 SG_ MRR_FL_CAN_DET_AMPLITUDE_023 : 71|7@0+ (1,-64) [-64|63] "dBsm"  CADM
 SG_ MRR_FL_CAN_DET_VALID_LEVEL_023 : 64|1@0+ (1,0) [0|1] ""  CADM

BO_ 772 MRR_FL_Detection_029_035: 64 MRRFL
 SG_ MRR_FL_CAN_DET_MID_TARGET_035 : 462|1@0+ (1,0) [0|1] ""  CADM
 SG_ MRR_FL_CAN_DET_MID_TARGET_034 : 461|1@0+ (1,0) [0|1] ""  CADM
 SG_ MRR_FL_CAN_DET_MID_TARGET_033 : 460|1@0+ (1,0) [0|1] ""  CADM
 SG_ MRR_FL_CAN_DET_MID_TARGET_032 : 459|1@0+ (1,0) [0|1] ""  CADM
 SG_ MRR_FL_CAN_DET_MID_TARGET_031 : 458|1@0+ (1,0) [0|1] ""  CADM
 SG_ MRR_FL_CAN_DET_MID_TARGET_030 : 457|1@0+ (1,0) [0|1] ""  CADM
 SG_ MRR_FL_CAN_DET_MID_TARGET_029 : 456|1@0+ (1,0) [0|1] ""  CADM
 SG_ MRR_FL_CAN_DET_Near_TARGET_029 : 448|1@0+ (1,0) [0|1] ""  CADM
 SG_ MRR_FL_CAN_DET_Near_TARGET_030 : 449|1@0+ (1,0) [0|1] ""  CADM
 SG_ MRR_FL_CAN_DET_Near_TARGET_031 : 450|1@0+ (1,0) [0|1] ""  CADM
 SG_ MRR_FL_CAN_DET_Near_TARGET_032 : 451|1@0+ (1,0) [0|1] ""  CADM
 SG_ MRR_FL_CAN_DET_Near_TARGET_033 : 452|1@0+ (1,0) [0|1] ""  CADM
 SG_ MRR_FL_CAN_DET_Near_TARGET_034 : 453|1@0+ (1,0) [0|1] ""  CADM
 SG_ MRR_FL_CAN_DET_Near_TARGET_035 : 454|1@0+ (1,0) [0|1] ""  CADM
 SG_ MRR_FL_CAN_DET_ELEVATION_029 : 63|7@0+ (0.002748,-0.1745) [-0.1745|0.174496] "rad"  CADM
 SG_ MRR_FL_CAN_DET_CONFID_AZIMU_0025 : 33|2@0+ (1,0) [0|3] ""  CADM
 SG_ MRR_FL_CAN_DET_SUPER_RES_TA_0027 : 56|1@0+ (1,0) [0|1] ""  CADM
 SG_ MRR_FL_CAN_DET_CONFID_ELEVA_0027 : 49|1@0+ (1,0) [0|1] ""  CADM
 SG_ MRR_FL_CAN_DET_HOST_VEH_CLU_0027 : 48|1@0+ (1,0) [0|1] ""  CADM
 SG_ MRR_FL_CAN_DET_VALID_LEVEL_029 : 0|1@0+ (1,0) [0|1] ""  CADM
 SG_ MRR_FL_CAN_DET_AZIMUTH_029 : 47|14@0+ (0.0003834,-3.1416) [-3.1416|3.1396422] "rad"  CADM
 SG_ MRR_FL_CAN_DET_RANGE_029 : 31|14@0+ (0.015625,0) [0|255.984375] "m"  CADM
 SG_ MRR_FL_CAN_DET_RANGE_RATE_029 : 15|14@0+ (0.015625,-128) [-128|127.984375] "m/s"  CADM
 SG_ MRR_FL_CAN_DET_AMPLITUDE_029 : 7|7@0+ (1,-64) [-64|63] "dBsm"  CADM
 SG_ MRR_FL_CAN_SCAN_INDEX_2LSB_029 : 17|2@0+ (1,0) [0|3] ""  CADM
 SG_ MRR_FL_DET_MC_005 : 491|4@0+ (1,0) [0|15] ""  CADM
 SG_ MRR_FL_DET_CRC_005 : 503|16@0+ (1,0) [0|65535] ""  CADM
 SG_ MRR_FL_CAN_DET_ELEVATION_035 : 447|7@0+ (0.002748,-0.1745) [-0.1745|0.174496] "rad"  CADM
 SG_ MRR_FL_CAN_DET_SUPER_RES_TA_0028 : 440|1@0+ (1,0) [0|1] ""  CADM
 SG_ MRR_FL_CAN_DET_AZIMUTH_035 : 431|14@0+ (0.0003834,-3.1416) [-3.1416|3.1396422] "rad"  CADM
 SG_ MRR_FL_CAN_DET_CONFID_ELEVA_0028 : 433|1@0+ (1,0) [0|1] ""  CADM
 SG_ MRR_FL_CAN_DET_HOST_VEH_CLU_0028 : 432|1@0+ (1,0) [0|1] ""  CADM
 SG_ MRR_FL_CAN_DET_RANGE_035 : 415|14@0+ (0.015625,0) [0|255.984375] "m"  CADM
 SG_ MRR_FL_CAN_DET_CONFID_AZIMUTH_03 : 417|2@0+ (1,0) [0|3] ""  CADM
 SG_ MRR_FL_CAN_DET_RANGE_RATE_035 : 399|14@0+ (0.015625,-128) [-128|127.984375] "m/s"  CADM
 SG_ MRR_FL_CAN_SCAN_INDEX_2LSB_035 : 401|2@0+ (1,0) [0|3] ""  CADM
 SG_ MRR_FL_CAN_DET_AMPLITUDE_035 : 391|7@0+ (1,-64) [-64|63] "dBsm"  CADM
 SG_ MRR_FL_CAN_DET_VALID_LEVEL_035 : 384|1@0+ (1,0) [0|1] ""  CADM
 SG_ MRR_FL_CAN_DET_ELEVATION_034 : 383|7@0+ (0.002748,-0.1745) [-0.1745|0.174496] "rad"  CADM
 SG_ MRR_FL_CAN_DET_SUPER_RES_TA_0029 : 376|1@0+ (1,0) [0|1] ""  CADM
 SG_ MRR_FL_CAN_DET_AZIMUTH_034 : 367|14@0+ (0.0003834,-3.1416) [-3.1416|3.1396422] "rad"  CADM
 SG_ MRR_FL_CAN_DET_CONFID_ELEVA_0029 : 369|1@0+ (1,0) [0|1] ""  CADM
 SG_ MRR_FL_CAN_DET_HOST_VEH_CLU_0029 : 368|1@0+ (1,0) [0|1] ""  CADM
 SG_ MRR_FL_CAN_DET_RANGE_034 : 351|14@0+ (0.015625,0) [0|255.984375] "m"  CADM
 SG_ MRR_FL_CAN_DET_CONFID_AZIMU_0026 : 353|2@0+ (1,0) [0|3] ""  CADM
 SG_ MRR_FL_CAN_DET_RANGE_RATE_034 : 335|14@0+ (0.015625,-128) [-128|127.984375] "m/s"  CADM
 SG_ MRR_FL_CAN_SCAN_INDEX_2LSB_034 : 337|2@0+ (1,0) [0|3] ""  CADM
 SG_ MRR_FL_CAN_DET_AMPLITUDE_034 : 327|7@0+ (1,-64) [-64|63] "dBsm"  CADM
 SG_ MRR_FL_CAN_DET_VALID_LEVEL_034 : 320|1@0+ (1,0) [0|1] ""  CADM
 SG_ MRR_FL_CAN_DET_ELEVATION_033 : 319|7@0+ (0.002748,-0.1745) [-0.1745|0.174496] "rad"  CADM
 SG_ MRR_FL_CAN_DET_SUPER_RES_TA_0030 : 312|1@0+ (1,0) [0|1] ""  CADM
 SG_ MRR_FL_CAN_DET_AZIMUTH_033 : 303|14@0+ (0.0003834,-3.1416) [-3.1416|3.1396422] "rad"  CADM
 SG_ MRR_FL_CAN_DET_CONFID_ELEVA_0030 : 305|1@0+ (1,0) [0|1] ""  CADM
 SG_ MRR_FL_CAN_DET_HOST_VEH_CLU_0030 : 304|1@0+ (1,0) [0|1] ""  CADM
 SG_ MRR_FL_CAN_DET_RANGE_033 : 287|14@0+ (0.015625,0) [0|255.984375] "m"  CADM
 SG_ MRR_FL_CAN_DET_CONFID_AZIMU_0027 : 289|2@0+ (1,0) [0|3] ""  CADM
 SG_ MRR_FL_CAN_DET_RANGE_RATE_033 : 271|14@0+ (0.015625,-128) [-128|127.984375] "m/s"  CADM
 SG_ MRR_FL_CAN_SCAN_INDEX_2LSB_033 : 273|2@0+ (1,0) [0|3] ""  CADM
 SG_ MRR_FL_CAN_DET_AMPLITUDE_033 : 263|7@0+ (1,-64) [-64|63] "dBsm"  CADM
 SG_ MRR_FL_CAN_DET_VALID_LEVEL_033 : 256|1@0+ (1,0) [0|1] ""  CADM
 SG_ MRR_FL_CAN_DET_ELEVATION_032 : 255|7@0+ (0.002748,-0.1745) [-0.1745|0.174496] "rad"  CADM
 SG_ MRR_FL_CAN_DET_SUPER_RES_TA_0031 : 248|1@0+ (1,0) [0|1] ""  CADM
 SG_ MRR_FL_CAN_DET_AZIMUTH_032 : 239|14@0+ (0.0003834,-3.1416) [-3.1416|3.1396422] "rad"  CADM
 SG_ MRR_FL_CAN_DET_CONFID_ELEVA_0031 : 241|1@0+ (1,0) [0|1] ""  CADM
 SG_ MRR_FL_CAN_DET_HOST_VEH_CLU_0031 : 240|1@0+ (1,0) [0|1] ""  CADM
 SG_ MRR_FL_CAN_DET_RANGE_032 : 223|14@0+ (0.015625,0) [0|255.984375] "m"  CADM
 SG_ MRR_FL_CAN_DET_CONFID_AZIMU_0028 : 225|2@0+ (1,0) [0|3] ""  CADM
 SG_ MRR_FL_CAN_DET_RANGE_RATE_032 : 207|14@0+ (0.015625,-128) [-128|127.984375] "m/s"  CADM
 SG_ MRR_FL_CAN_SCAN_INDEX_2LSB_032 : 209|2@0+ (1,0) [0|3] ""  CADM
 SG_ MRR_FL_CAN_DET_AMPLITUDE_032 : 199|7@0+ (1,-64) [-64|63] "dBsm"  CADM
 SG_ MRR_FL_CAN_DET_VALID_LEVEL_032 : 192|1@0+ (1,0) [0|1] ""  CADM
 SG_ MRR_FL_CAN_DET_ELEVATION_031 : 191|7@0+ (0.002748,-0.1745) [-0.1745|0.174496] "rad"  CADM
 SG_ MRR_FL_CAN_DET_SUPER_RES_TA_0032 : 184|1@0+ (1,0) [0|1] ""  CADM
 SG_ MRR_FL_CAN_DET_AZIMUTH_031 : 175|14@0+ (0.0003834,-3.1416) [-3.1416|3.1396422] "rad"  CADM
 SG_ MRR_FL_CAN_DET_CONFID_ELEVA_0032 : 177|1@0+ (1,0) [0|1] ""  CADM
 SG_ MRR_FL_CAN_DET_HOST_VEH_CLU_0032 : 176|1@0+ (1,0) [0|1] ""  CADM
 SG_ MRR_FL_CAN_DET_RANGE_031 : 159|14@0+ (0.015625,0) [0|255.984375] "m"  CADM
 SG_ MRR_FL_CAN_DET_CONFID_AZIMU_0029 : 161|2@0+ (1,0) [0|3] ""  CADM
 SG_ MRR_FL_CAN_DET_RANGE_RATE_031 : 143|14@0+ (0.015625,-128) [-128|127.984375] "m/s"  CADM
 SG_ MRR_FL_CAN_SCAN_INDEX_2LSB_031 : 145|2@0+ (1,0) [0|3] ""  CADM
 SG_ MRR_FL_CAN_DET_AMPLITUDE_031 : 135|7@0+ (1,-64) [-64|63] "dBsm"  CADM
 SG_ MRR_FL_CAN_DET_VALID_LEVEL_031 : 128|1@0+ (1,0) [0|1] ""  CADM
 SG_ MRR_FL_CAN_DET_ELEVATION_030 : 127|7@0+ (0.002748,-0.1745) [-0.1745|0.174496] "rad"  CADM
 SG_ MRR_FL_CAN_DET_SUPER_RES_TA_0033 : 120|1@0+ (1,0) [0|1] ""  CADM
 SG_ MRR_FL_CAN_DET_AZIMUTH_030 : 111|14@0+ (0.0003834,-3.1416) [-3.1416|3.1396422] "rad"  CADM
 SG_ MRR_FL_CAN_DET_CONFID_ELEVA_0033 : 113|1@0+ (1,0) [0|1] ""  CADM
 SG_ MRR_FL_CAN_DET_HOST_VEH_CLU_0033 : 112|1@0+ (1,0) [0|1] ""  CADM
 SG_ MRR_FL_CAN_DET_RANGE_030 : 95|14@0+ (0.015625,0) [0|255.984375] "m"  CADM
 SG_ MRR_FL_CAN_DET_CONFID_AZIMU_0030 : 97|2@0+ (1,0) [0|3] ""  CADM
 SG_ MRR_FL_CAN_DET_RANGE_RATE_030 : 79|14@0+ (0.015625,-128) [-128|127.984375] "m/s"  CADM
 SG_ MRR_FL_CAN_SCAN_INDEX_2LSB_030 : 81|2@0+ (1,0) [0|3] ""  CADM
 SG_ MRR_FL_CAN_DET_AMPLITUDE_030 : 71|7@0+ (1,-64) [-64|63] "dBsm"  CADM
 SG_ MRR_FL_CAN_DET_VALID_LEVEL_030 : 64|1@0+ (1,0) [0|1] ""  CADM

BO_ 773 MRR_FL_Detection_036_042: 64 MRRFL
 SG_ MRR_FL_CAN_DET_MID_TARGET_042 : 462|1@0+ (1,0) [0|1] ""  CADM
 SG_ MRR_FL_CAN_DET_MID_TARGET_041 : 461|1@0+ (1,0) [0|1] ""  CADM
 SG_ MRR_FL_CAN_DET_MID_TARGET_040 : 460|1@0+ (1,0) [0|1] ""  CADM
 SG_ MRR_FL_CAN_DET_MID_TARGET_039 : 459|1@0+ (1,0) [0|1] ""  CADM
 SG_ MRR_FL_CAN_DET_MID_TARGET_038 : 458|1@0+ (1,0) [0|1] ""  CADM
 SG_ MRR_FL_CAN_DET_MID_TARGET_037 : 457|1@0+ (1,0) [0|1] ""  CADM
 SG_ MRR_FL_CAN_DET_MID_TARGET_036 : 456|1@0+ (1,0) [0|1] ""  CADM
 SG_ MRR_FL_CAN_DET_Near_TARGET_036 : 448|1@0+ (1,0) [0|1] ""  CADM
 SG_ MRR_FL_CAN_DET_Near_TARGET_037 : 449|1@0+ (1,0) [0|1] ""  CADM
 SG_ MRR_FL_CAN_DET_Near_TARGET_038 : 450|1@0+ (1,0) [0|1] ""  CADM
 SG_ MRR_FL_CAN_DET_Near_TARGET_039 : 451|1@0+ (1,0) [0|1] ""  CADM
 SG_ MRR_FL_CAN_DET_Near_TARGET_040 : 452|1@0+ (1,0) [0|1] ""  CADM
 SG_ MRR_FL_CAN_DET_Near_TARGET_041 : 453|1@0+ (1,0) [0|1] ""  CADM
 SG_ MRR_FL_CAN_DET_Near_TARGET_042 : 454|1@0+ (1,0) [0|1] ""  CADM
 SG_ MRR_FL_CAN_DET_ELEVATION_036 : 63|7@0+ (0.002748,-0.1745) [-0.1745|0.174496] "rad"  CADM
 SG_ MRR_FL_CAN_DET_CONFID_AZIMU_0031 : 33|2@0+ (1,0) [0|3] ""  CADM
 SG_ MRR_FL_CAN_DET_SUPER_RES_TA_0034 : 56|1@0+ (1,0) [0|1] ""  CADM
 SG_ MRR_FL_CAN_DET_CONFID_ELEVA_0034 : 49|1@0+ (1,0) [0|1] ""  CADM
 SG_ MRR_FL_CAN_DET_HOST_VEH_CLU_0034 : 48|1@0+ (1,0) [0|1] ""  CADM
 SG_ MRR_FL_CAN_DET_VALID_LEVEL_036 : 0|1@0+ (1,0) [0|1] ""  CADM
 SG_ MRR_FL_CAN_DET_AZIMUTH_036 : 47|14@0+ (0.0003834,-3.1416) [-3.1416|3.1396422] "rad"  CADM
 SG_ MRR_FL_CAN_DET_RANGE_036 : 31|14@0+ (0.015625,0) [0|255.984375] "m"  CADM
 SG_ MRR_FL_CAN_DET_RANGE_RATE_036 : 15|14@0+ (0.015625,-128) [-128|127.984375] "m/s"  CADM
 SG_ MRR_FL_CAN_DET_AMPLITUDE_036 : 7|7@0+ (1,-64) [-64|63] "dBsm"  CADM
 SG_ MRR_FL_CAN_SCAN_INDEX_2LSB_036 : 17|2@0+ (1,0) [0|3] ""  CADM
 SG_ MRR_FL_DET_MC_006 : 491|4@0+ (1,0) [0|15] ""  CADM
 SG_ MRR_FL_DET_CRC_006 : 503|16@0+ (1,0) [0|65535] ""  CADM
 SG_ MRR_FL_CAN_DET_ELEVATION_042 : 447|7@0+ (0.002748,-0.1745) [-0.1745|0.174496] "rad"  CADM
 SG_ MRR_FL_CAN_DET_SUPER_RES_TA_0035 : 440|1@0+ (1,0) [0|1] ""  CADM
 SG_ MRR_FL_CAN_DET_AZIMUTH_042 : 431|14@0+ (0.0003834,-3.1416) [-3.1416|3.1396422] "rad"  CADM
 SG_ MRR_FL_CAN_DET_CONFID_ELEVA_0035 : 433|1@0+ (1,0) [0|1] ""  CADM
 SG_ MRR_FL_CAN_DET_HOST_VEH_CLU_0035 : 432|1@0+ (1,0) [0|1] ""  CADM
 SG_ MRR_FL_CAN_DET_RANGE_042 : 415|14@0+ (0.015625,0) [0|255.984375] "m"  CADM
 SG_ MRR_FL_CAN_DET_CONFID_AZIMUTH_04 : 417|2@0+ (1,0) [0|3] ""  CADM
 SG_ MRR_FL_CAN_DET_RANGE_RATE_042 : 399|14@0+ (0.015625,-128) [-128|127.984375] "m/s"  CADM
 SG_ MRR_FL_CAN_SCAN_INDEX_2LSB_042 : 401|2@0+ (1,0) [0|3] ""  CADM
 SG_ MRR_FL_CAN_DET_AMPLITUDE_042 : 391|7@0+ (1,-64) [-64|63] "dBsm"  CADM
 SG_ MRR_FL_CAN_DET_VALID_LEVEL_042 : 384|1@0+ (1,0) [0|1] ""  CADM
 SG_ MRR_FL_CAN_DET_ELEVATION_041 : 383|7@0+ (0.002748,-0.1745) [-0.1745|0.174496] "rad"  CADM
 SG_ MRR_FL_CAN_DET_SUPER_RES_TA_0036 : 376|1@0+ (1,0) [0|1] ""  CADM
 SG_ MRR_FL_CAN_DET_AZIMUTH_041 : 367|14@0+ (0.0003834,-3.1416) [-3.1416|3.1396422] "rad"  CADM
 SG_ MRR_FL_CAN_DET_CONFID_ELEVA_0036 : 369|1@0+ (1,0) [0|1] ""  CADM
 SG_ MRR_FL_CAN_DET_HOST_VEH_CLU_0036 : 368|1@0+ (1,0) [0|1] ""  CADM
 SG_ MRR_FL_CAN_DET_RANGE_041 : 351|14@0+ (0.015625,0) [0|255.984375] "m"  CADM
 SG_ MRR_FL_CAN_DET_CONFID_AZIMU_0032 : 353|2@0+ (1,0) [0|3] ""  CADM
 SG_ MRR_FL_CAN_DET_RANGE_RATE_041 : 335|14@0+ (0.015625,-128) [-128|127.984375] "m/s"  CADM
 SG_ MRR_FL_CAN_SCAN_INDEX_2LSB_041 : 337|2@0+ (1,0) [0|3] ""  CADM
 SG_ MRR_FL_CAN_DET_AMPLITUDE_041 : 327|7@0+ (1,-64) [-64|63] "dBsm"  CADM
 SG_ MRR_FL_CAN_DET_VALID_LEVEL_041 : 320|1@0+ (1,0) [0|1] ""  CADM
 SG_ MRR_FL_CAN_DET_ELEVATION_040 : 319|7@0+ (0.002748,-0.1745) [-0.1745|0.174496] "rad"  CADM
 SG_ MRR_FL_CAN_DET_SUPER_RES_TA_0037 : 312|1@0+ (1,0) [0|1] ""  CADM
 SG_ MRR_FL_CAN_DET_AZIMUTH_040 : 303|14@0+ (0.0003834,-3.1416) [-3.1416|3.1396422] "rad"  CADM
 SG_ MRR_FL_CAN_DET_CONFID_ELEVA_0037 : 305|1@0+ (1,0) [0|1] ""  CADM
 SG_ MRR_FL_CAN_DET_HOST_VEH_CLU_0037 : 304|1@0+ (1,0) [0|1] ""  CADM
 SG_ MRR_FL_CAN_DET_RANGE_040 : 287|14@0+ (0.015625,0) [0|255.984375] "m"  CADM
 SG_ MRR_FL_CAN_DET_CONFID_AZIMU_0033 : 289|2@0+ (1,0) [0|3] ""  CADM
 SG_ MRR_FL_CAN_DET_RANGE_RATE_040 : 271|14@0+ (0.015625,-128) [-128|127.984375] "m/s"  CADM
 SG_ MRR_FL_CAN_SCAN_INDEX_2LSB_040 : 273|2@0+ (1,0) [0|3] ""  CADM
 SG_ MRR_FL_CAN_DET_AMPLITUDE_040 : 263|7@0+ (1,-64) [-64|63] "dBsm"  CADM
 SG_ MRR_FL_CAN_DET_VALID_LEVEL_040 : 256|1@0+ (1,0) [0|1] ""  CADM
 SG_ MRR_FL_CAN_DET_ELEVATION_039 : 255|7@0+ (0.002748,-0.1745) [-0.1745|0.174496] "rad"  CADM
 SG_ MRR_FL_CAN_DET_SUPER_RES_TA_0038 : 248|1@0+ (1,0) [0|1] ""  CADM
 SG_ MRR_FL_CAN_DET_AZIMUTH_039 : 239|14@0+ (0.0003834,-3.1416) [-3.1416|3.1396422] "rad"  CADM
 SG_ MRR_FL_CAN_DET_CONFID_ELEVA_0038 : 241|1@0+ (1,0) [0|1] ""  CADM
 SG_ MRR_FL_CAN_DET_HOST_VEH_CLU_0038 : 240|1@0+ (1,0) [0|1] ""  CADM
 SG_ MRR_FL_CAN_DET_RANGE_039 : 223|14@0+ (0.015625,0) [0|255.984375] "m"  CADM
 SG_ MRR_FL_CAN_DET_CONFID_AZIMU_0034 : 225|2@0+ (1,0) [0|3] ""  CADM
 SG_ MRR_FL_CAN_DET_RANGE_RATE_039 : 207|14@0+ (0.015625,-128) [-128|127.984375] "m/s"  CADM
 SG_ MRR_FL_CAN_SCAN_INDEX_2LSB_039 : 209|2@0+ (1,0) [0|3] ""  CADM
 SG_ MRR_FL_CAN_DET_AMPLITUDE_039 : 199|7@0+ (1,-64) [-64|63] "dBsm"  CADM
 SG_ MRR_FL_CAN_DET_VALID_LEVEL_039 : 192|1@0+ (1,0) [0|1] ""  CADM
 SG_ MRR_FL_CAN_DET_ELEVATION_038 : 191|7@0+ (0.002748,-0.1745) [-0.1745|0.174496] "rad"  CADM
 SG_ MRR_FL_CAN_DET_SUPER_RES_TA_0039 : 184|1@0+ (1,0) [0|1] ""  CADM
 SG_ MRR_FL_CAN_DET_AZIMUTH_038 : 175|14@0+ (0.0003834,-3.1416) [-3.1416|3.1396422] "rad"  CADM
 SG_ MRR_FL_CAN_DET_CONFID_ELEVA_0039 : 177|1@0+ (1,0) [0|1] ""  CADM
 SG_ MRR_FL_CAN_DET_HOST_VEH_CLU_0039 : 176|1@0+ (1,0) [0|1] ""  CADM
 SG_ MRR_FL_CAN_DET_RANGE_038 : 159|14@0+ (0.015625,0) [0|255.984375] "m"  CADM
 SG_ MRR_FL_CAN_DET_CONFID_AZIMU_0035 : 161|2@0+ (1,0) [0|3] ""  CADM
 SG_ MRR_FL_CAN_DET_RANGE_RATE_038 : 143|14@0+ (0.015625,-128) [-128|127.984375] "m/s"  CADM
 SG_ MRR_FL_CAN_SCAN_INDEX_2LSB_038 : 145|2@0+ (1,0) [0|3] ""  CADM
 SG_ MRR_FL_CAN_DET_AMPLITUDE_038 : 135|7@0+ (1,-64) [-64|63] "dBsm"  CADM
 SG_ MRR_FL_CAN_DET_VALID_LEVEL_038 : 128|1@0+ (1,0) [0|1] ""  CADM
 SG_ MRR_FL_CAN_DET_ELEVATION_037 : 127|7@0+ (0.002748,-0.1745) [-0.1745|0.174496] "rad"  CADM
 SG_ MRR_FL_CAN_DET_SUPER_RES_TA_0040 : 120|1@0+ (1,0) [0|1] ""  CADM
 SG_ MRR_FL_CAN_DET_AZIMUTH_037 : 111|14@0+ (0.0003834,-3.1416) [-3.1416|3.1396422] "rad"  CADM
 SG_ MRR_FL_CAN_DET_CONFID_ELEVA_0040 : 113|1@0+ (1,0) [0|1] ""  CADM
 SG_ MRR_FL_CAN_DET_HOST_VEH_CLU_0040 : 112|1@0+ (1,0) [0|1] ""  CADM
 SG_ MRR_FL_CAN_DET_RANGE_037 : 95|14@0+ (0.015625,0) [0|255.984375] "m"  CADM
 SG_ MRR_FL_CAN_DET_CONFID_AZIMU_0036 : 97|2@0+ (1,0) [0|3] ""  CADM
 SG_ MRR_FL_CAN_DET_RANGE_RATE_037 : 79|14@0+ (0.015625,-128) [-128|127.984375] "m/s"  CADM
 SG_ MRR_FL_CAN_SCAN_INDEX_2LSB_037 : 81|2@0+ (1,0) [0|3] ""  CADM
 SG_ MRR_FL_CAN_DET_AMPLITUDE_037 : 71|7@0+ (1,-64) [-64|63] "dBsm"  CADM
 SG_ MRR_FL_CAN_DET_VALID_LEVEL_037 : 64|1@0+ (1,0) [0|1] ""  CADM

BO_ 774 MRR_FL_Detection_043_049: 64 MRRFL
 SG_ MRR_FL_CAN_DET_MID_TARGET_049 : 462|1@0+ (1,0) [0|1] ""  CADM
 SG_ MRR_FL_CAN_DET_MID_TARGET_048 : 461|1@0+ (1,0) [0|1] ""  CADM
 SG_ MRR_FL_CAN_DET_MID_TARGET_047 : 460|1@0+ (1,0) [0|1] ""  CADM
 SG_ MRR_FL_CAN_DET_MID_TARGET_046 : 459|1@0+ (1,0) [0|1] ""  CADM
 SG_ MRR_FL_CAN_DET_MID_TARGET_045 : 458|1@0+ (1,0) [0|1] ""  CADM
 SG_ MRR_FL_CAN_DET_MID_TARGET_044 : 457|1@0+ (1,0) [0|1] ""  CADM
 SG_ MRR_FL_CAN_DET_MID_TARGET_043 : 456|1@0+ (1,0) [0|1] ""  CADM
 SG_ MRR_FL_CAN_DET_Near_TARGET_043 : 448|1@0+ (1,0) [0|1] ""  CADM
 SG_ MRR_FL_CAN_DET_Near_TARGET_044 : 449|1@0+ (1,0) [0|1] ""  CADM
 SG_ MRR_FL_CAN_DET_Near_TARGET_045 : 450|1@0+ (1,0) [0|1] ""  CADM
 SG_ MRR_FL_CAN_DET_Near_TARGET_046 : 451|1@0+ (1,0) [0|1] ""  CADM
 SG_ MRR_FL_CAN_DET_Near_TARGET_047 : 452|1@0+ (1,0) [0|1] ""  CADM
 SG_ MRR_FL_CAN_DET_Near_TARGET_048 : 453|1@0+ (1,0) [0|1] ""  CADM
 SG_ MRR_FL_CAN_DET_Near_TARGET_049 : 454|1@0+ (1,0) [0|1] ""  CADM
 SG_ MRR_FL_CAN_DET_ELEVATION_043 : 63|7@0+ (0.002748,-0.1745) [-0.1745|0.174496] "rad"  CADM
 SG_ MRR_FL_CAN_DET_CONFID_AZIMU_0037 : 33|2@0+ (1,0) [0|3] ""  CADM
 SG_ MRR_FL_CAN_DET_SUPER_RES_TA_0041 : 56|1@0+ (1,0) [0|1] ""  CADM
 SG_ MRR_FL_CAN_DET_CONFID_ELEVA_0041 : 49|1@0+ (1,0) [0|1] ""  CADM
 SG_ MRR_FL_CAN_DET_HOST_VEH_CLU_0041 : 48|1@0+ (1,0) [0|1] ""  CADM
 SG_ MRR_FL_CAN_DET_VALID_LEVEL_043 : 0|1@0+ (1,0) [0|1] ""  CADM
 SG_ MRR_FL_CAN_DET_AZIMUTH_043 : 47|14@0+ (0.0003834,-3.1416) [-3.1416|3.1396422] "rad"  CADM
 SG_ MRR_FL_CAN_DET_RANGE_043 : 31|14@0+ (0.015625,0) [0|255.984375] "m"  CADM
 SG_ MRR_FL_CAN_DET_RANGE_RATE_043 : 15|14@0+ (0.015625,-128) [-128|127.984375] "m/s"  CADM
 SG_ MRR_FL_CAN_DET_AMPLITUDE_043 : 7|7@0+ (1,-64) [-64|63] "dBsm"  CADM
 SG_ MRR_FL_CAN_SCAN_INDEX_2LSB_043 : 17|2@0+ (1,0) [0|3] ""  CADM
 SG_ MRR_FL_DET_MC_007 : 491|4@0+ (1,0) [0|15] ""  CADM
 SG_ MRR_FL_DET_CRC_007 : 503|16@0+ (1,0) [0|65535] ""  CADM
 SG_ MRR_FL_CAN_DET_ELEVATION_049 : 447|7@0+ (0.002748,-0.1745) [-0.1745|0.174496] "rad"  CADM
 SG_ MRR_FL_CAN_DET_SUPER_RES_TA_0042 : 440|1@0+ (1,0) [0|1] ""  CADM
 SG_ MRR_FL_CAN_DET_AZIMUTH_049 : 431|14@0+ (0.0003834,-3.1416) [-3.1416|3.1396422] "rad"  CADM
 SG_ MRR_FL_CAN_DET_CONFID_ELEVA_0042 : 433|1@0+ (1,0) [0|1] ""  CADM
 SG_ MRR_FL_CAN_DET_HOST_VEH_CLU_0042 : 432|1@0+ (1,0) [0|1] ""  CADM
 SG_ MRR_FL_CAN_DET_RANGE_049 : 415|14@0+ (0.015625,0) [0|255.984375] "m"  CADM
 SG_ MRR_FL_CAN_DET_CONFID_AZIMU_0038 : 417|2@0+ (1,0) [0|3] ""  CADM
 SG_ MRR_FL_CAN_DET_RANGE_RATE_049 : 399|14@0+ (0.015625,-128) [-128|127.984375] "m/s"  CADM
 SG_ MRR_FL_CAN_SCAN_INDEX_2LSB_049 : 401|2@0+ (1,0) [0|3] ""  CADM
 SG_ MRR_FL_CAN_DET_AMPLITUDE_049 : 391|7@0+ (1,-64) [-64|63] "dBsm"  CADM
 SG_ MRR_FL_CAN_DET_VALID_LEVEL_049 : 384|1@0+ (1,0) [0|1] ""  CADM
 SG_ MRR_FL_CAN_DET_ELEVATION_048 : 383|7@0+ (0.002748,-0.1745) [-0.1745|0.174496] "rad"  CADM
 SG_ MRR_FL_CAN_DET_SUPER_RES_TA_0043 : 376|1@0+ (1,0) [0|1] ""  CADM
 SG_ MRR_FL_CAN_DET_AZIMUTH_048 : 367|14@0+ (0.0003834,-3.1416) [-3.1416|3.1396422] "rad"  CADM
 SG_ MRR_FL_CAN_DET_CONFID_ELEVA_0043 : 369|1@0+ (1,0) [0|1] ""  CADM
 SG_ MRR_FL_CAN_DET_HOST_VEH_CLU_0043 : 368|1@0+ (1,0) [0|1] ""  CADM
 SG_ MRR_FL_CAN_DET_RANGE_048 : 351|14@0+ (0.015625,0) [0|255.984375] "m"  CADM
 SG_ MRR_FL_CAN_DET_CONFID_AZIMU_0039 : 353|2@0+ (1,0) [0|3] ""  CADM
 SG_ MRR_FL_CAN_DET_RANGE_RATE_048 : 335|14@0+ (0.015625,-128) [-128|127.984375] "m/s"  CADM
 SG_ MRR_FL_CAN_SCAN_INDEX_2LSB_048 : 337|2@0+ (1,0) [0|3] ""  CADM
 SG_ MRR_FL_CAN_DET_AMPLITUDE_048 : 327|7@0+ (1,-64) [-64|63] "dBsm"  CADM
 SG_ MRR_FL_CAN_DET_VALID_LEVEL_048 : 320|1@0+ (1,0) [0|1] ""  CADM
 SG_ MRR_FL_CAN_DET_ELEVATION_047 : 319|7@0+ (0.002748,-0.1745) [-0.1745|0.174496] "rad"  CADM
 SG_ MRR_FL_CAN_DET_SUPER_RES_TA_0044 : 312|1@0+ (1,0) [0|1] ""  CADM
 SG_ MRR_FL_CAN_DET_AZIMUTH_047 : 303|14@0+ (0.0003834,-3.1416) [-3.1416|3.1396422] "rad"  CADM
 SG_ MRR_FL_CAN_DET_CONFID_ELEVA_0044 : 305|1@0+ (1,0) [0|1] ""  CADM
 SG_ MRR_FL_CAN_DET_HOST_VEH_CLU_0044 : 304|1@0+ (1,0) [0|1] ""  CADM
 SG_ MRR_FL_CAN_DET_RANGE_047 : 287|14@0+ (0.015625,0) [0|255.984375] "m"  CADM
 SG_ MRR_FL_CAN_DET_CONFID_AZIMU_0040 : 289|2@0+ (1,0) [0|3] ""  CADM
 SG_ MRR_FL_CAN_DET_RANGE_RATE_047 : 271|14@0+ (0.015625,-128) [-128|127.984375] "m/s"  CADM
 SG_ MRR_FL_CAN_SCAN_INDEX_2LSB_047 : 273|2@0+ (1,0) [0|3] ""  CADM
 SG_ MRR_FL_CAN_DET_AMPLITUDE_047 : 263|7@0+ (1,-64) [-64|63] "dBsm"  CADM
 SG_ MRR_FL_CAN_DET_VALID_LEVEL_047 : 256|1@0+ (1,0) [0|1] ""  CADM
 SG_ MRR_FL_CAN_DET_ELEVATION_046 : 255|7@0+ (0.002748,-0.1745) [-0.1745|0.174496] "rad"  CADM
 SG_ MRR_FL_CAN_DET_SUPER_RES_TA_0045 : 248|1@0+ (1,0) [0|1] ""  CADM
 SG_ MRR_FL_CAN_DET_AZIMUTH_046 : 239|14@0+ (0.0003834,-3.1416) [-3.1416|3.1396422] "rad"  CADM
 SG_ MRR_FL_CAN_DET_CONFID_ELEVA_0045 : 241|1@0+ (1,0) [0|1] ""  CADM
 SG_ MRR_FL_CAN_DET_HOST_VEH_CLU_0045 : 240|1@0+ (1,0) [0|1] ""  CADM
 SG_ MRR_FL_CAN_DET_RANGE_046 : 223|14@0+ (0.015625,0) [0|255.984375] "m"  CADM
 SG_ MRR_FL_CAN_DET_CONFID_AZIMU_0041 : 225|2@0+ (1,0) [0|3] ""  CADM
 SG_ MRR_FL_CAN_DET_RANGE_RATE_046 : 207|14@0+ (0.015625,-128) [-128|127.984375] "m/s"  CADM
 SG_ MRR_FL_CAN_SCAN_INDEX_2LSB_046 : 209|2@0+ (1,0) [0|3] ""  CADM
 SG_ MRR_FL_CAN_DET_AMPLITUDE_046 : 199|7@0+ (1,-64) [-64|63] "dBsm"  CADM
 SG_ MRR_FL_CAN_DET_VALID_LEVEL_046 : 192|1@0+ (1,0) [0|1] ""  CADM
 SG_ MRR_FL_CAN_DET_ELEVATION_045 : 191|7@0+ (0.002748,-0.1745) [-0.1745|0.174496] "rad"  CADM
 SG_ MRR_FL_CAN_DET_SUPER_RES_TA_0046 : 184|1@0+ (1,0) [0|1] ""  CADM
 SG_ MRR_FL_CAN_DET_AZIMUTH_045 : 175|14@0+ (0.0003834,-3.1416) [-3.1416|3.1396422] "rad"  CADM
 SG_ MRR_FL_CAN_DET_CONFID_ELEVA_0046 : 177|1@0+ (1,0) [0|1] ""  CADM
 SG_ MRR_FL_CAN_DET_HOST_VEH_CLU_0046 : 176|1@0+ (1,0) [0|1] ""  CADM
 SG_ MRR_FL_CAN_DET_RANGE_045 : 159|14@0+ (0.015625,0) [0|255.984375] "m"  CADM
 SG_ MRR_FL_CAN_DET_CONFID_AZIMU_0042 : 161|2@0+ (1,0) [0|3] ""  CADM
 SG_ MRR_FL_CAN_DET_RANGE_RATE_045 : 143|14@0+ (0.015625,-128) [-128|127.984375] "m/s"  CADM
 SG_ MRR_FL_CAN_SCAN_INDEX_2LSB_045 : 145|2@0+ (1,0) [0|3] ""  CADM
 SG_ MRR_FL_CAN_DET_AMPLITUDE_045 : 135|7@0+ (1,-64) [-64|63] "dBsm"  CADM
 SG_ MRR_FL_CAN_DET_VALID_LEVEL_045 : 128|1@0+ (1,0) [0|1] ""  CADM
 SG_ MRR_FL_CAN_DET_ELEVATION_044 : 127|7@0+ (0.002748,-0.1745) [-0.1745|0.174496] "rad"  CADM
 SG_ MRR_FL_CAN_DET_SUPER_RES_TA_0047 : 120|1@0+ (1,0) [0|1] ""  CADM
 SG_ MRR_FL_CAN_DET_AZIMUTH_044 : 111|14@0+ (0.0003834,-3.1416) [-3.1416|3.1396422] "rad"  CADM
 SG_ MRR_FL_CAN_DET_CONFID_ELEVA_0047 : 113|1@0+ (1,0) [0|1] ""  CADM
 SG_ MRR_FL_CAN_DET_HOST_VEH_CLU_0047 : 112|1@0+ (1,0) [0|1] ""  CADM
 SG_ MRR_FL_CAN_DET_RANGE_044 : 95|14@0+ (0.015625,0) [0|255.984375] "m"  CADM
 SG_ MRR_FL_CAN_DET_CONFID_AZIMU_0043 : 97|2@0+ (1,0) [0|3] ""  CADM
 SG_ MRR_FL_CAN_DET_RANGE_RATE_044 : 79|14@0+ (0.015625,-128) [-128|127.984375] "m/s"  CADM
 SG_ MRR_FL_CAN_SCAN_INDEX_2LSB_044 : 81|2@0+ (1,0) [0|3] ""  CADM
 SG_ MRR_FL_CAN_DET_AMPLITUDE_044 : 71|7@0+ (1,-64) [-64|63] "dBsm"  CADM
 SG_ MRR_FL_CAN_DET_VALID_LEVEL_044 : 64|1@0+ (1,0) [0|1] ""  CADM

BA_DEF_ SG_  "NWM_WakeupAllowed" ENUM  "0 No","1 Yes";
BA_DEF_ BO_  "GenMsgTimeoutTime" INT 0 2500;
BA_DEF_ BO_  "WakeupMessage" ENUM  "0 No","1 Yes";
BA_DEF_ SG_  "SignalDescription" STRING ;
BA_DEF_ SG_  "GenSigTimeoutTime_ABS_ESC" INT 0 100000;
BA_DEF_ SG_  "UsedOnPgmDBC" ENUM  "No","Yes";
BA_DEF_ BO_  "VFrameFormat" ENUM  "StandardCAN","ExtendedCAN","reserved","reserved","reserved","reserved","reserved","reserved","reserved","reserved","reserved","reserved","reserved","reserved","StandardCAN_FD","ExtendedCAN_FD";
BA_DEF_ BO_  "DiagConnection" INT 0 65535;
BA_DEF_ BO_  "CanTpBs" INT 0 255;
BA_DEF_ BO_  "EventRateOfChange" INT 10 10000;
BA_DEF_ BO_  "DiagState" ENUM  "No","Yes";
BA_DEF_ BO_  "DiagRequest" ENUM  "No","Yes";
BA_DEF_ BO_  "DiagResponse" ENUM  "No","Yes";
BA_DEF_ SG_  "GenSigCycleTime" INT 0 0;
BA_DEF_ SG_  "GenSigVtName" STRING ;
BA_DEF_ SG_  "GenSigVtEn" STRING ;
BA_DEF_ SG_  "GenSigCmt" STRING ;
BA_DEF_ SG_  "GenSigSendType" ENUM  "Cyclic","OnWrite","vector_leerstring","OnChange","vector_leerstring","IfActive","vector_leerstring","NoSigSendType";
BA_DEF_ SG_  "GenSigInactiveValue" INT 0 100000;
BA_DEF_ SG_  "GenSigMissingSourceValue" INT 0 1000000000;
BA_DEF_ SG_  "GenSigStartValue" INT 0 1000000000;
BA_DEF_ BO_  "GenMsgILSupport" ENUM  "No","Yes";
BA_DEF_ BO_  "GenMsgSendType" ENUM  "FixedPeriodic","Event","EnabledPeriodic","NotUsed","NotUsed","EventPeriodic","NotUsed","NotUsed","NoMsgSendType";
BA_DEF_ BO_  "GenMsgCycleTime" INT 0 100000;
BA_DEF_ BO_  "GenMsgNrOfRepetition" INT 0 100;
BA_DEF_ SG_  "SystemSignalLongSymbol" STRING ;
BA_DEF_DEF_  "NWM_WakeupAllowed" "0 No";
BA_DEF_DEF_  "GenMsgTimeoutTime" 2500;
BA_DEF_DEF_  "WakeupMessage" "0 No";
BA_DEF_DEF_  "SignalDescription" "";
BA_DEF_DEF_  "GenSigTimeoutTime_ABS_ESC" 0;
BA_DEF_DEF_  "UsedOnPgmDBC" "Yes";
BA_DEF_DEF_  "VFrameFormat" "StandardCAN_FD";
BA_DEF_DEF_  "DiagConnection" 0;
BA_DEF_DEF_  "CanTpBs" 255;
BA_DEF_DEF_  "EventRateOfChange" 10000;
BA_DEF_DEF_  "DiagState" "No";
BA_DEF_DEF_  "DiagRequest" "No";
BA_DEF_DEF_  "DiagResponse" "No";
BA_DEF_DEF_  "GenSigCycleTime" 0;
BA_DEF_DEF_  "GenSigVtName" "";
BA_DEF_DEF_  "GenSigVtEn" "";
BA_DEF_DEF_  "GenSigCmt" "";
BA_DEF_DEF_  "GenSigSendType" "NoSigSendType";
BA_DEF_DEF_  "GenSigInactiveValue" 0;
BA_DEF_DEF_  "GenSigMissingSourceValue" 0;
BA_DEF_DEF_  "GenSigStartValue" 0;
BA_DEF_DEF_  "GenMsgILSupport" "Yes";
BA_DEF_DEF_  "GenMsgSendType" "NoMsgSendType";
BA_DEF_DEF_  "GenMsgCycleTime" 0;
BA_DEF_DEF_  "GenMsgNrOfRepetition" 0;
BA_DEF_DEF_  "SystemSignalLongSymbol" "";
BA_ "GenMsgTimeoutTime" BO_ 456 0;
BA_ "GenMsgSendType" BO_ 456 1;
BA_ "GenMsgTimeoutTime" BO_ 398 0;
BA_ "GenMsgSendType" BO_ 398 1;
BA_ "GenMsgTimeoutTime" BO_ 462 0;
BA_ "GenMsgSendType" BO_ 462 1;
BA_ "GenMsgTimeoutTime" BO_ 461 0;
BA_ "GenMsgCycleTime" BO_ 461 100;
BA_ "GenMsgSendType" BO_ 461 0;
BA_ "GenMsgTimeoutTime" BO_ 769 0;
BA_ "GenMsgSendType" BO_ 769 1;
BA_ "GenMsgTimeoutTime" BO_ 770 0;
BA_ "GenMsgSendType" BO_ 770 1;
BA_ "GenMsgTimeoutTime" BO_ 771 0;
BA_ "GenMsgSendType" BO_ 771 1;
BA_ "GenMsgTimeoutTime" BO_ 772 0;
BA_ "GenMsgSendType" BO_ 772 1;
BA_ "GenMsgTimeoutTime" BO_ 773 0;
BA_ "GenMsgSendType" BO_ 773 1;
BA_ "GenMsgTimeoutTime" BO_ 774 0;
BA_ "GenMsgSendType" BO_ 774 1;
BA_ "GenSigSendType" SG_ 456 MRR_CAN_RadarWaveform_FR 1;
BA_ "GenSigCmt" SG_ 456 MRR_FR_CAN_RANGE_COVERAGE "CAN range coverage";
BA_ "GenSigCmt" SG_ 456 MRR_FR_CAN_DOPPLER_COVERAGE "CAN range coverage";
BA_ "GenSigCmt" SG_ 456 MRR_FR_CAN_FOV_HOR "CAN range coverage";
BA_ "GenSigCmt" SG_ 456 MRR_FR_CAN_FOV_VER "CAN range coverage";
BA_ "GenSigSendType" SG_ 398 MRR_FL_System_Operation_Mode_Sta 1;
BA_ "SystemSignalLongSymbol" SG_ 398 MRR_FL_System_Operation_Mode_Sta "MRR_FL_System_Operation_Mode_Status";
BA_ "GenSigVtEn" SG_ 398 RadarSensorNotOperational_MRRFL "TRUE";
BA_ "GenSigCmt" SG_ 398 RadarSensorNotOperational_MRRFL "Set to TRUE when the radar system is not operational";
BA_ "GenSigVtEn" SG_ 398 RadarAlignmentOutOfRange_MRRFL "TRUE";
BA_ "GenSigCmt" SG_ 398 RadarAlignmentOutOfRange_MRRFL "Set to TRUE when the radar sensor cannot be aligned without mechanical adjustment of the sensor";
BA_ "GenSigVtEn" SG_ 398 RadarBlockageDetected_MRRFL "TRUE";
BA_ "GenSigCmt" SG_ 398 RadarBlockageDetected_MRRFL "Blockage error indication";
BA_ "GenSigVtEn" SG_ 398 RadarExternalConditionsNotOK_MRR "TRUE";
BA_ "GenSigCmt" SG_ 398 RadarExternalConditionsNotOK_MRR "Set to TRUE when the FL is not working properly because of too high temperature or insufficient power in the FR";
BA_ "SystemSignalLongSymbol" SG_ 398 RadarExternalConditionsNotOK_MRR "RadarExternalConditionsNotOK_MRRFL";
BA_ "GenSigVtEn" SG_ 398 RadarAlignmentIncomplete_MRRFL "TRUE";
BA_ "GenSigCmt" SG_ 398 RadarAlignmentIncomplete_MRRFL "Indication that the alignment routine has not been completed";
BA_ "GenSigVtEn" SG_ 398 RadarAlignmentNotStarted_MRRFL "TRUE";
BA_ "GenSigCmt" SG_ 398 RadarAlignmentNotStarted_MRRFL "Set to TRUE as long as the radar sensor alignment has not started";
BA_ "GenSigSendType" SG_ 462 MRR_FR_System_Operation_Mode_Sta 1;
BA_ "SystemSignalLongSymbol" SG_ 462 MRR_FR_System_Operation_Mode_Sta "MRR_FR_System_Operation_Mode_Status";
BA_ "GenSigVtEn" SG_ 462 RadarSensorNotOperational_MRRFR "TRUE";
BA_ "GenSigCmt" SG_ 462 RadarSensorNotOperational_MRRFR "Set to TRUE when the radar system is not operational";
BA_ "GenSigVtEn" SG_ 462 RadarAlignmentOutOfRange_MRRFR "TRUE";
BA_ "GenSigCmt" SG_ 462 RadarAlignmentOutOfRange_MRRFR "Set to TRUE when the radar sensor cannot be aligned without mechanical adjustment of the sensor";
BA_ "GenSigVtEn" SG_ 462 RadarBlockageDetected_MRRFR "TRUE";
BA_ "GenSigCmt" SG_ 462 RadarBlockageDetected_MRRFR "Blockage error indication";
BA_ "GenSigVtEn" SG_ 462 RadarExternalConditionsNotO_0000 "TRUE";
BA_ "GenSigCmt" SG_ 462 RadarExternalConditionsNotO_0000 "Set to TRUE when the FR is not working properly because of too high temperature or insufficient power in the FR";
BA_ "SystemSignalLongSymbol" SG_ 462 RadarExternalConditionsNotO_0000 "RadarExternalConditionsNotOK_MRRFR";
BA_ "GenSigVtEn" SG_ 462 RadarAlignmentIncomplete_MRRFR "TRUE";
BA_ "GenSigCmt" SG_ 462 RadarAlignmentIncomplete_MRRFR "Indication that the alignment routine has not been completed";
BA_ "GenSigVtEn" SG_ 462 RadarAlignmentNotStarted_MRRFR "TRUE";
BA_ "GenSigCmt" SG_ 462 RadarAlignmentNotStarted_MRRFR "Set to TRUE as long as the radar sensor alignment has not started";
BA_ "GenSigCycleTime" SG_ 461 MRR_FR_CAN_Dolphin_AFC 100;
BA_ "GenSigSendType" SG_ 461 MRR_FR_CAN_Dolphin_AFC 0;
BA_ "GenSigCycleTime" SG_ 461 MRR_FR_CAN_Dolphin_Tx3 100;
BA_ "GenSigSendType" SG_ 461 MRR_FR_CAN_Dolphin_Tx3 0;
BA_ "GenSigCycleTime" SG_ 461 MRR_FR_CAN_Dolphin_Tx2 100;
BA_ "GenSigSendType" SG_ 461 MRR_FR_CAN_Dolphin_Tx2 0;
BA_ "GenSigCycleTime" SG_ 461 MRR_FR_CAN_1_8_V 100;
BA_ "GenSigSendType" SG_ 461 MRR_FR_CAN_1_8_V 0;
BA_ "GenSigCycleTime" SG_ 461 MRR_FR_CAN_BATT_VOLTS 100;
BA_ "GenSigSendType" SG_ 461 MRR_FR_CAN_BATT_VOLTS 0;
BA_ "GenSigCycleTime" SG_ 461 MRR_FR_CAN_1_25_V 100;
BA_ "GenSigSendType" SG_ 461 MRR_FR_CAN_1_25_V 0;
BA_ "GenSigCycleTime" SG_ 461 MRR_FR_CAN_5_V 100;
BA_ "GenSigSendType" SG_ 461 MRR_FR_CAN_5_V 0;
BA_ "GenSigCycleTime" SG_ 461 MRR_FR_CAN_1_1_V 100;
BA_ "GenSigSendType" SG_ 461 MRR_FR_CAN_1_1_V 0;
BA_ "GenSigCycleTime" SG_ 461 MRR_FR_CAN_2_3_V 100;
BA_ "GenSigSendType" SG_ 461 MRR_FR_CAN_2_3_V 0;
BA_ "GenSigCycleTime" SG_ 461 MRR_FR_CAN_Dolphin_Tx1 100;
BA_ "GenSigSendType" SG_ 461 MRR_FR_CAN_Dolphin_Tx1 0;
BA_ "GenSigCycleTime" SG_ 461 MRR_FR_CAN_RRU_Temp1 100;
BA_ "GenSigSendType" SG_ 461 MRR_FR_CAN_RRU_Temp1 0;
BA_ "SignalDescription" SG_ 769 MRR_FL_CAN_DET_MID_TARGET_014 "MID_Target_Discrimination";
BA_ "GenSigSendType" SG_ 769 MRR_FL_CAN_DET_MID_TARGET_014 1;
BA_ "SignalDescription" SG_ 769 MRR_FL_CAN_DET_MID_TARGET_013 "MID_Target_Discrimination";
BA_ "SignalDescription" SG_ 769 MRR_FL_CAN_DET_MID_TARGET_012 "MID_Target_Discrimination";
BA_ "SignalDescription" SG_ 769 MRR_FL_CAN_DET_MID_TARGET_011 "MID_Target_Discrimination";
BA_ "SignalDescription" SG_ 769 MRR_FL_CAN_DET_MID_TARGET_010 "MID_Target_Discrimination";
BA_ "SignalDescription" SG_ 769 MRR_FL_CAN_DET_MID_TARGET_009 "MID_Target_Discrimination";
BA_ "SignalDescription" SG_ 769 MRR_FL_CAN_DET_MID_TARGET_008 "MID_Target_Discrimination";
BA_ "SignalDescription" SG_ 769 MRR_FL_CAN_DET_Near_TARGET_008 "Near_Target_Discrimination";
BA_ "SignalDescription" SG_ 769 MRR_FL_CAN_DET_Near_TARGET_009 "Near_Target_Discrimination";
BA_ "SignalDescription" SG_ 769 MRR_FL_CAN_DET_Near_TARGET_010 "Near_Target_Discrimination";
BA_ "SignalDescription" SG_ 769 MRR_FL_CAN_DET_Near_TARGET_011 "Near_Target_Discrimination";
BA_ "SignalDescription" SG_ 769 MRR_FL_CAN_DET_Near_TARGET_012 "Near_Target_Discrimination";
BA_ "SignalDescription" SG_ 769 MRR_FL_CAN_DET_Near_TARGET_013 "Near_Target_Discrimination";
BA_ "SignalDescription" SG_ 769 MRR_FL_CAN_DET_Near_TARGET_014 "Near_Target_Discrimination";
BA_ "GenSigCmt" SG_ 769 MRR_FL_CAN_DET_ELEVATION_008 "Detected object elevation position";
BA_ "GenSigStartValue" SG_ 769 MRR_FL_CAN_DET_ELEVATION_008 63.8646288209607;
BA_ "GenSigCmt" SG_ 769 MRR_FL_CAN_DET_CONFID_AZIMU_0006 "Signal to noise level";
BA_ "GenSigVtEn" SG_ 769 MRR_FL_CAN_DET_CONFID_AZIMU_0006 "TRUE";
BA_ "SystemSignalLongSymbol" SG_ 769 MRR_FL_CAN_DET_CONFID_AZIMU_0006 "MRR_FL_CAN_DET_CONFID_AZIMUTH_008";
BA_ "GenSigCmt" SG_ 769 MRR_FL_CAN_DET_SUPER_RES_TA_0006 "Super resolution target";
BA_ "SystemSignalLongSymbol" SG_ 769 MRR_FL_CAN_DET_SUPER_RES_TA_0006 "MRR_FL_CAN_DET_SUPER_RES_TARGET_008";
BA_ "GenSigCmt" SG_ 769 MRR_FL_CAN_DET_CONFID_ELEVA_0006 "Elevation Angle Confidence";
BA_ "SystemSignalLongSymbol" SG_ 769 MRR_FL_CAN_DET_CONFID_ELEVA_0006 "MRR_FL_CAN_DET_CONFID_ELEVATION_008";
BA_ "GenSigCmt" SG_ 769 MRR_FL_CAN_DET_HOST_VEH_CLU_0006 "Host vehicle clutter";
BA_ "SystemSignalLongSymbol" SG_ 769 MRR_FL_CAN_DET_HOST_VEH_CLU_0006 "MRR_FL_CAN_DET_HOST_VEH_CLUTTER_008";
BA_ "GenSigCmt" SG_ 769 MRR_FL_CAN_DET_VALID_LEVEL_008 "Detected object valid level";
BA_ "GenSigCmt" SG_ 769 MRR_FL_CAN_DET_AZIMUTH_008 "Detected object azimuth position";
BA_ "GenSigStartValue" SG_ 769 MRR_FL_CAN_DET_AZIMUTH_008 8194.05320813772;
BA_ "GenSigCmt" SG_ 769 MRR_FL_CAN_DET_RANGE_008 "Detected object range";
BA_ "GenSigCmt" SG_ 769 MRR_FL_CAN_DET_RANGE_RATE_008 "Detected object range rate";
BA_ "GenSigStartValue" SG_ 769 MRR_FL_CAN_DET_RANGE_RATE_008 8192;
BA_ "GenSigCmt" SG_ 769 MRR_FL_CAN_DET_AMPLITUDE_008 "Detected object amplitude";
BA_ "GenSigStartValue" SG_ 769 MRR_FL_CAN_DET_AMPLITUDE_008 64;
BA_ "GenSigCmt" SG_ 769 MRR_FL_CAN_SCAN_INDEX_2LSB_008 "The two LSB of scan index";
BA_ "GenSigStartValue" SG_ 769 MRR_FL_CAN_DET_ELEVATION_014 63.8646288209607;
BA_ "GenSigCmt" SG_ 769 MRR_FL_CAN_DET_ELEVATION_014 "Detected object elevation position";
BA_ "GenSigCmt" SG_ 769 MRR_FL_CAN_DET_SUPER_RES_TA_0007 "Super resolution target";
BA_ "SystemSignalLongSymbol" SG_ 769 MRR_FL_CAN_DET_SUPER_RES_TA_0007 "MRR_FL_CAN_DET_SUPER_RES_TARGET_014";
BA_ "GenSigCmt" SG_ 769 MRR_FL_CAN_DET_AZIMUTH_014 "Detected object azimuth position";
BA_ "GenSigStartValue" SG_ 769 MRR_FL_CAN_DET_AZIMUTH_014 8194.05320813772;
BA_ "GenSigCmt" SG_ 769 MRR_FL_CAN_DET_CONFID_ELEVA_0007 "Elevation Angle Confidence";
BA_ "SystemSignalLongSymbol" SG_ 769 MRR_FL_CAN_DET_CONFID_ELEVA_0007 "MRR_FL_CAN_DET_CONFID_ELEVATION_014";
BA_ "GenSigCmt" SG_ 769 MRR_FL_CAN_DET_HOST_VEH_CLU_0007 "Host vehicle clutter";
BA_ "SystemSignalLongSymbol" SG_ 769 MRR_FL_CAN_DET_HOST_VEH_CLU_0007 "MRR_FL_CAN_DET_HOST_VEH_CLUTTER_014";
BA_ "GenSigCmt" SG_ 769 MRR_FL_CAN_DET_RANGE_014 "Detected object range";
BA_ "GenSigVtEn" SG_ 769 MRR_FL_CAN_DET_CONFID_AZIMUTH_01 "TRUE";
BA_ "GenSigCmt" SG_ 769 MRR_FL_CAN_DET_CONFID_AZIMUTH_01 "Signal to noise level";
BA_ "SystemSignalLongSymbol" SG_ 769 MRR_FL_CAN_DET_CONFID_AZIMUTH_01 "MRR_FL_CAN_DET_CONFID_AZIMUTH_014";
BA_ "GenSigCmt" SG_ 769 MRR_FL_CAN_DET_RANGE_RATE_014 "Detected object range rate";
BA_ "GenSigStartValue" SG_ 769 MRR_FL_CAN_DET_RANGE_RATE_014 8192;
BA_ "GenSigCmt" SG_ 769 MRR_FL_CAN_SCAN_INDEX_2LSB_014 "The two LSB of scan index";
BA_ "GenSigCmt" SG_ 769 MRR_FL_CAN_DET_AMPLITUDE_014 "Detected object amplitude";
BA_ "GenSigStartValue" SG_ 769 MRR_FL_CAN_DET_AMPLITUDE_014 64;
BA_ "GenSigCmt" SG_ 769 MRR_FL_CAN_DET_VALID_LEVEL_014 "Detected object valid level";
BA_ "GenSigCmt" SG_ 769 MRR_FL_CAN_DET_ELEVATION_013 "Detected object elevation position";
BA_ "GenSigStartValue" SG_ 769 MRR_FL_CAN_DET_ELEVATION_013 63.8646288209607;
BA_ "GenSigCmt" SG_ 769 MRR_FL_CAN_DET_SUPER_RES_TA_0008 "Super resolution target";
BA_ "SystemSignalLongSymbol" SG_ 769 MRR_FL_CAN_DET_SUPER_RES_TA_0008 "MRR_FL_CAN_DET_SUPER_RES_TARGET_013";
BA_ "GenSigCmt" SG_ 769 MRR_FL_CAN_DET_AZIMUTH_013 "Detected object azimuth position";
BA_ "GenSigStartValue" SG_ 769 MRR_FL_CAN_DET_AZIMUTH_013 8194.05320813772;
BA_ "GenSigCmt" SG_ 769 MRR_FL_CAN_DET_CONFID_ELEVA_0008 "Elevation Angle Confidence";
BA_ "SystemSignalLongSymbol" SG_ 769 MRR_FL_CAN_DET_CONFID_ELEVA_0008 "MRR_FL_CAN_DET_CONFID_ELEVATION_013";
BA_ "GenSigCmt" SG_ 769 MRR_FL_CAN_DET_HOST_VEH_CLU_0008 "Host vehicle clutter";
BA_ "SystemSignalLongSymbol" SG_ 769 MRR_FL_CAN_DET_HOST_VEH_CLU_0008 "MRR_FL_CAN_DET_HOST_VEH_CLUTTER_013";
BA_ "GenSigCmt" SG_ 769 MRR_FL_CAN_DET_RANGE_013 "Detected object range";
BA_ "GenSigVtEn" SG_ 769 MRR_FL_CAN_DET_CONFID_AZIMU_0007 "TRUE";
BA_ "GenSigCmt" SG_ 769 MRR_FL_CAN_DET_CONFID_AZIMU_0007 "Signal to noise level";
BA_ "SystemSignalLongSymbol" SG_ 769 MRR_FL_CAN_DET_CONFID_AZIMU_0007 "MRR_FL_CAN_DET_CONFID_AZIMUTH_013";
BA_ "GenSigCmt" SG_ 769 MRR_FL_CAN_DET_RANGE_RATE_013 "Detected object range rate";
BA_ "GenSigStartValue" SG_ 769 MRR_FL_CAN_DET_RANGE_RATE_013 8192;
BA_ "GenSigCmt" SG_ 769 MRR_FL_CAN_SCAN_INDEX_2LSB_013 "The two LSB of scan index";
BA_ "GenSigCmt" SG_ 769 MRR_FL_CAN_DET_AMPLITUDE_013 "Detected object amplitude";
BA_ "GenSigStartValue" SG_ 769 MRR_FL_CAN_DET_AMPLITUDE_013 64;
BA_ "GenSigCmt" SG_ 769 MRR_FL_CAN_DET_VALID_LEVEL_013 "Detected object valid level";
BA_ "GenSigCmt" SG_ 769 MRR_FL_CAN_DET_ELEVATION_012 "Detected object elevation position";
BA_ "GenSigStartValue" SG_ 769 MRR_FL_CAN_DET_ELEVATION_012 63.8646288209607;
BA_ "GenSigCmt" SG_ 769 MRR_FL_CAN_DET_SUPER_RES_TA_0009 "Super resolution target";
BA_ "SystemSignalLongSymbol" SG_ 769 MRR_FL_CAN_DET_SUPER_RES_TA_0009 "MRR_FL_CAN_DET_SUPER_RES_TARGET_012";
BA_ "GenSigCmt" SG_ 769 MRR_FL_CAN_DET_AZIMUTH_012 "Detected object azimuth position";
BA_ "GenSigStartValue" SG_ 769 MRR_FL_CAN_DET_AZIMUTH_012 8194.05320813772;
BA_ "GenSigCmt" SG_ 769 MRR_FL_CAN_DET_CONFID_ELEVA_0009 "Elevation Angle Confidence";
BA_ "SystemSignalLongSymbol" SG_ 769 MRR_FL_CAN_DET_CONFID_ELEVA_0009 "MRR_FL_CAN_DET_CONFID_ELEVATION_012";
BA_ "GenSigCmt" SG_ 769 MRR_FL_CAN_DET_HOST_VEH_CLU_0009 "Host vehicle clutter";
BA_ "SystemSignalLongSymbol" SG_ 769 MRR_FL_CAN_DET_HOST_VEH_CLU_0009 "MRR_FL_CAN_DET_HOST_VEH_CLUTTER_012";
BA_ "GenSigCmt" SG_ 769 MRR_FL_CAN_DET_RANGE_012 "Detected object range";
BA_ "GenSigVtEn" SG_ 769 MRR_FL_CAN_DET_CONFID_AZIMU_0008 "TRUE";
BA_ "GenSigCmt" SG_ 769 MRR_FL_CAN_DET_CONFID_AZIMU_0008 "Signal to noise level";
BA_ "SystemSignalLongSymbol" SG_ 769 MRR_FL_CAN_DET_CONFID_AZIMU_0008 "MRR_FL_CAN_DET_CONFID_AZIMUTH_012";
BA_ "GenSigCmt" SG_ 769 MRR_FL_CAN_DET_RANGE_RATE_012 "Detected object range rate";
BA_ "GenSigStartValue" SG_ 769 MRR_FL_CAN_DET_RANGE_RATE_012 8192;
BA_ "GenSigCmt" SG_ 769 MRR_FL_CAN_SCAN_INDEX_2LSB_012 "The two LSB of scan index";
BA_ "GenSigCmt" SG_ 769 MRR_FL_CAN_DET_AMPLITUDE_012 "Detected object amplitude";
BA_ "GenSigStartValue" SG_ 769 MRR_FL_CAN_DET_AMPLITUDE_012 64;
BA_ "GenSigCmt" SG_ 769 MRR_FL_CAN_DET_VALID_LEVEL_012 "Detected object valid level";
BA_ "GenSigCmt" SG_ 769 MRR_FL_CAN_DET_ELEVATION_011 "Detected object elevation position";
BA_ "GenSigStartValue" SG_ 769 MRR_FL_CAN_DET_ELEVATION_011 63.8646288209607;
BA_ "GenSigCmt" SG_ 769 MRR_FL_CAN_DET_SUPER_RES_TA_0010 "Super resolution target";
BA_ "SystemSignalLongSymbol" SG_ 769 MRR_FL_CAN_DET_SUPER_RES_TA_0010 "MRR_FL_CAN_DET_SUPER_RES_TARGET_011";
BA_ "GenSigCmt" SG_ 769 MRR_FL_CAN_DET_AZIMUTH_011 "Detected object azimuth position";
BA_ "GenSigStartValue" SG_ 769 MRR_FL_CAN_DET_AZIMUTH_011 8194.05320813772;
BA_ "GenSigCmt" SG_ 769 MRR_FL_CAN_DET_CONFID_ELEVA_0010 "Elevation Angle Confidence";
BA_ "SystemSignalLongSymbol" SG_ 769 MRR_FL_CAN_DET_CONFID_ELEVA_0010 "MRR_FL_CAN_DET_CONFID_ELEVATION_011";
BA_ "GenSigCmt" SG_ 769 MRR_FL_CAN_DET_HOST_VEH_CLU_0010 "Host vehicle clutter";
BA_ "SystemSignalLongSymbol" SG_ 769 MRR_FL_CAN_DET_HOST_VEH_CLU_0010 "MRR_FL_CAN_DET_HOST_VEH_CLUTTER_011";
BA_ "GenSigCmt" SG_ 769 MRR_FL_CAN_DET_RANGE_011 "Detected object range";
BA_ "GenSigVtEn" SG_ 769 MRR_FL_CAN_DET_CONFID_AZIMU_0009 "TRUE";
BA_ "GenSigCmt" SG_ 769 MRR_FL_CAN_DET_CONFID_AZIMU_0009 "Signal to noise level";
BA_ "SystemSignalLongSymbol" SG_ 769 MRR_FL_CAN_DET_CONFID_AZIMU_0009 "MRR_FL_CAN_DET_CONFID_AZIMUTH_011";
BA_ "GenSigCmt" SG_ 769 MRR_FL_CAN_DET_RANGE_RATE_011 "Detected object range rate";
BA_ "GenSigStartValue" SG_ 769 MRR_FL_CAN_DET_RANGE_RATE_011 8192;
BA_ "GenSigCmt" SG_ 769 MRR_FL_CAN_SCAN_INDEX_2LSB_011 "The two LSB of scan index";
BA_ "GenSigCmt" SG_ 769 MRR_FL_CAN_DET_AMPLITUDE_011 "Detected object amplitude";
BA_ "GenSigStartValue" SG_ 769 MRR_FL_CAN_DET_AMPLITUDE_011 64;
BA_ "GenSigCmt" SG_ 769 MRR_FL_CAN_DET_VALID_LEVEL_011 "Detected object valid level";
BA_ "GenSigCmt" SG_ 769 MRR_FL_CAN_DET_ELEVATION_010 "Detected object elevation position";
BA_ "GenSigStartValue" SG_ 769 MRR_FL_CAN_DET_ELEVATION_010 63.8646288209607;
BA_ "GenSigCmt" SG_ 769 MRR_FL_CAN_DET_SUPER_RES_TA_0011 "Super resolution target";
BA_ "SystemSignalLongSymbol" SG_ 769 MRR_FL_CAN_DET_SUPER_RES_TA_0011 "MRR_FL_CAN_DET_SUPER_RES_TARGET_010";
BA_ "GenSigCmt" SG_ 769 MRR_FL_CAN_DET_AZIMUTH_010 "Detected object azimuth position";
BA_ "GenSigStartValue" SG_ 769 MRR_FL_CAN_DET_AZIMUTH_010 8194.05320813772;
BA_ "GenSigCmt" SG_ 769 MRR_FL_CAN_DET_CONFID_ELEVA_0011 "Elevation Angle Confidence";
BA_ "SystemSignalLongSymbol" SG_ 769 MRR_FL_CAN_DET_CONFID_ELEVA_0011 "MRR_FL_CAN_DET_CONFID_ELEVATION_010";
BA_ "GenSigCmt" SG_ 769 MRR_FL_CAN_DET_HOST_VEH_CLU_0011 "Host vehicle clutter";
BA_ "SystemSignalLongSymbol" SG_ 769 MRR_FL_CAN_DET_HOST_VEH_CLU_0011 "MRR_FL_CAN_DET_HOST_VEH_CLUTTER_010";
BA_ "GenSigCmt" SG_ 769 MRR_FL_CAN_DET_RANGE_010 "Detected object range";
BA_ "GenSigVtEn" SG_ 769 MRR_FL_CAN_DET_CONFID_AZIMU_0010 "TRUE";
BA_ "GenSigCmt" SG_ 769 MRR_FL_CAN_DET_CONFID_AZIMU_0010 "Signal to noise level";
BA_ "SystemSignalLongSymbol" SG_ 769 MRR_FL_CAN_DET_CONFID_AZIMU_0010 "MRR_FL_CAN_DET_CONFID_AZIMUTH_010";
BA_ "GenSigCmt" SG_ 769 MRR_FL_CAN_DET_RANGE_RATE_010 "Detected object range rate";
BA_ "GenSigStartValue" SG_ 769 MRR_FL_CAN_DET_RANGE_RATE_010 8192;
BA_ "GenSigCmt" SG_ 769 MRR_FL_CAN_SCAN_INDEX_2LSB_010 "The two LSB of scan index";
BA_ "GenSigCmt" SG_ 769 MRR_FL_CAN_DET_AMPLITUDE_010 "Detected object amplitude";
BA_ "GenSigStartValue" SG_ 769 MRR_FL_CAN_DET_AMPLITUDE_010 64;
BA_ "GenSigCmt" SG_ 769 MRR_FL_CAN_DET_VALID_LEVEL_010 "Detected object valid level";
BA_ "GenSigCmt" SG_ 769 MRR_FL_CAN_DET_ELEVATION_009 "Detected object elevation position";
BA_ "GenSigStartValue" SG_ 769 MRR_FL_CAN_DET_ELEVATION_009 63.8646288209607;
BA_ "GenSigCmt" SG_ 769 MRR_FL_CAN_DET_SUPER_RES_TA_0012 "Super resolution target";
BA_ "SystemSignalLongSymbol" SG_ 769 MRR_FL_CAN_DET_SUPER_RES_TA_0012 "MRR_FL_CAN_DET_SUPER_RES_TARGET_009";
BA_ "GenSigCmt" SG_ 769 MRR_FL_CAN_DET_AZIMUTH_009 "Detected object azimuth position";
BA_ "GenSigStartValue" SG_ 769 MRR_FL_CAN_DET_AZIMUTH_009 8194.05320813772;
BA_ "GenSigCmt" SG_ 769 MRR_FL_CAN_DET_CONFID_ELEVA_0012 "Elevation Angle Confidence";
BA_ "SystemSignalLongSymbol" SG_ 769 MRR_FL_CAN_DET_CONFID_ELEVA_0012 "MRR_FL_CAN_DET_CONFID_ELEVATION_009";
BA_ "GenSigCmt" SG_ 769 MRR_FL_CAN_DET_HOST_VEH_CLU_0012 "Host vehicle clutter";
BA_ "SystemSignalLongSymbol" SG_ 769 MRR_FL_CAN_DET_HOST_VEH_CLU_0012 "MRR_FL_CAN_DET_HOST_VEH_CLUTTER_009";
BA_ "GenSigCmt" SG_ 769 MRR_FL_CAN_DET_RANGE_009 "Detected object range";
BA_ "GenSigVtEn" SG_ 769 MRR_FL_CAN_DET_CONFID_AZIMU_0011 "TRUE";
BA_ "GenSigCmt" SG_ 769 MRR_FL_CAN_DET_CONFID_AZIMU_0011 "Signal to noise level";
BA_ "SystemSignalLongSymbol" SG_ 769 MRR_FL_CAN_DET_CONFID_AZIMU_0011 "MRR_FL_CAN_DET_CONFID_AZIMUTH_009";
BA_ "GenSigCmt" SG_ 769 MRR_FL_CAN_DET_RANGE_RATE_009 "Detected object range rate";
BA_ "GenSigStartValue" SG_ 769 MRR_FL_CAN_DET_RANGE_RATE_009 8192;
BA_ "GenSigCmt" SG_ 769 MRR_FL_CAN_SCAN_INDEX_2LSB_009 "The two LSB of scan index";
BA_ "GenSigCmt" SG_ 769 MRR_FL_CAN_DET_AMPLITUDE_009 "Detected object amplitude";
BA_ "GenSigStartValue" SG_ 769 MRR_FL_CAN_DET_AMPLITUDE_009 64;
BA_ "GenSigCmt" SG_ 769 MRR_FL_CAN_DET_VALID_LEVEL_009 "Detected object valid level";
BA_ "SignalDescription" SG_ 770 MRR_FL_CAN_DET_MID_TARGET_021 "MID_Target_Discrimination";
BA_ "GenSigSendType" SG_ 770 MRR_FL_CAN_DET_MID_TARGET_021 1;
BA_ "SignalDescription" SG_ 770 MRR_FL_CAN_DET_MID_TARGET_020 "MID_Target_Discrimination";
BA_ "SignalDescription" SG_ 770 MRR_FL_CAN_DET_MID_TARGET_019 "MID_Target_Discrimination";
BA_ "SignalDescription" SG_ 770 MRR_FL_CAN_DET_MID_TARGET_018 "MID_Target_Discrimination";
BA_ "SignalDescription" SG_ 770 MRR_FL_CAN_DET_MID_TARGET_017 "MID_Target_Discrimination";
BA_ "SignalDescription" SG_ 770 MRR_FL_CAN_DET_MID_TARGET_016 "MID_Target_Discrimination";
BA_ "SignalDescription" SG_ 770 MRR_FL_CAN_DET_MID_TARGET_015 "MID_Target_Discrimination";
BA_ "SignalDescription" SG_ 770 MRR_FL_CAN_DET_Near_TARGET_015 "Near_Target_Discrimination";
BA_ "SignalDescription" SG_ 770 MRR_FL_CAN_DET_Near_TARGET_016 "Near_Target_Discrimination";
BA_ "SignalDescription" SG_ 770 MRR_FL_CAN_DET_Near_TARGET_017 "Near_Target_Discrimination";
BA_ "SignalDescription" SG_ 770 MRR_FL_CAN_DET_Near_TARGET_018 "Near_Target_Discrimination";
BA_ "SignalDescription" SG_ 770 MRR_FL_CAN_DET_Near_TARGET_019 "Near_Target_Discrimination";
BA_ "SignalDescription" SG_ 770 MRR_FL_CAN_DET_Near_TARGET_020 "Near_Target_Discrimination";
BA_ "SignalDescription" SG_ 770 MRR_FL_CAN_DET_Near_TARGET_021 "Near_Target_Discrimination";
BA_ "GenSigCmt" SG_ 770 MRR_FL_CAN_DET_ELEVATION_015 "Detected object elevation position";
BA_ "GenSigStartValue" SG_ 770 MRR_FL_CAN_DET_ELEVATION_015 63.8646288209607;
BA_ "GenSigCmt" SG_ 770 MRR_FL_CAN_DET_CONFID_AZIMU_0012 "Signal to noise level";
BA_ "GenSigVtEn" SG_ 770 MRR_FL_CAN_DET_CONFID_AZIMU_0012 "TRUE";
BA_ "SystemSignalLongSymbol" SG_ 770 MRR_FL_CAN_DET_CONFID_AZIMU_0012 "MRR_FL_CAN_DET_CONFID_AZIMUTH_015";
BA_ "GenSigCmt" SG_ 770 MRR_FL_CAN_DET_SUPER_RES_TA_0013 "Super resolution target";
BA_ "SystemSignalLongSymbol" SG_ 770 MRR_FL_CAN_DET_SUPER_RES_TA_0013 "MRR_FL_CAN_DET_SUPER_RES_TARGET_015";
BA_ "GenSigCmt" SG_ 770 MRR_FL_CAN_DET_CONFID_ELEVA_0013 "Elevation Angle Confidence";
BA_ "SystemSignalLongSymbol" SG_ 770 MRR_FL_CAN_DET_CONFID_ELEVA_0013 "MRR_FL_CAN_DET_CONFID_ELEVATION_015";
BA_ "GenSigCmt" SG_ 770 MRR_FL_CAN_DET_HOST_VEH_CLU_0013 "Host vehicle clutter";
BA_ "SystemSignalLongSymbol" SG_ 770 MRR_FL_CAN_DET_HOST_VEH_CLU_0013 "MRR_FL_CAN_DET_HOST_VEH_CLUTTER_015";
BA_ "GenSigCmt" SG_ 770 MRR_FL_CAN_DET_VALID_LEVEL_015 "Detected object valid level";
BA_ "GenSigCmt" SG_ 770 MRR_FL_CAN_DET_AZIMUTH_015 "Detected object azimuth position";
BA_ "GenSigStartValue" SG_ 770 MRR_FL_CAN_DET_AZIMUTH_015 8194.05320813772;
BA_ "GenSigCmt" SG_ 770 MRR_FL_CAN_DET_RANGE_015 "Detected object range";
BA_ "GenSigCmt" SG_ 770 MRR_FL_CAN_DET_RANGE_RATE_015 "Detected object range rate";
BA_ "GenSigStartValue" SG_ 770 MRR_FL_CAN_DET_RANGE_RATE_015 8192;
BA_ "GenSigCmt" SG_ 770 MRR_FL_CAN_DET_AMPLITUDE_015 "Detected object amplitude";
BA_ "GenSigStartValue" SG_ 770 MRR_FL_CAN_DET_AMPLITUDE_015 64;
BA_ "GenSigCmt" SG_ 770 MRR_FL_CAN_SCAN_INDEX_2LSB_015 "The two LSB of scan index";
BA_ "GenSigStartValue" SG_ 770 MRR_FL_CAN_DET_ELEVATION_021 63.8646288209607;
BA_ "GenSigCmt" SG_ 770 MRR_FL_CAN_DET_ELEVATION_021 "Detected object elevation position";
BA_ "GenSigCmt" SG_ 770 MRR_FL_CAN_DET_SUPER_RES_TA_0014 "Super resolution target";
BA_ "SystemSignalLongSymbol" SG_ 770 MRR_FL_CAN_DET_SUPER_RES_TA_0014 "MRR_FL_CAN_DET_SUPER_RES_TARGET_021";
BA_ "GenSigCmt" SG_ 770 MRR_FL_CAN_DET_AZIMUTH_021 "Detected object azimuth position";
BA_ "GenSigStartValue" SG_ 770 MRR_FL_CAN_DET_AZIMUTH_021 8194.05320813772;
BA_ "GenSigCmt" SG_ 770 MRR_FL_CAN_DET_CONFID_ELEVA_0014 "Elevation Angle Confidence";
BA_ "SystemSignalLongSymbol" SG_ 770 MRR_FL_CAN_DET_CONFID_ELEVA_0014 "MRR_FL_CAN_DET_CONFID_ELEVATION_021";
BA_ "GenSigCmt" SG_ 770 MRR_FL_CAN_DET_HOST_VEH_CLU_0014 "Host vehicle clutter";
BA_ "SystemSignalLongSymbol" SG_ 770 MRR_FL_CAN_DET_HOST_VEH_CLU_0014 "MRR_FL_CAN_DET_HOST_VEH_CLUTTER_021";
BA_ "GenSigCmt" SG_ 770 MRR_FL_CAN_DET_RANGE_021 "Detected object range";
BA_ "GenSigVtEn" SG_ 770 MRR_FL_CAN_DET_CONFID_AZIMUTH_02 "TRUE";
BA_ "GenSigCmt" SG_ 770 MRR_FL_CAN_DET_CONFID_AZIMUTH_02 "Signal to noise level";
BA_ "SystemSignalLongSymbol" SG_ 770 MRR_FL_CAN_DET_CONFID_AZIMUTH_02 "MRR_FL_CAN_DET_CONFID_AZIMUTH_021";
BA_ "GenSigCmt" SG_ 770 MRR_FL_CAN_DET_RANGE_RATE_021 "Detected object range rate";
BA_ "GenSigStartValue" SG_ 770 MRR_FL_CAN_DET_RANGE_RATE_021 8192;
BA_ "GenSigCmt" SG_ 770 MRR_FL_CAN_SCAN_INDEX_2LSB_021 "The two LSB of scan index";
BA_ "GenSigCmt" SG_ 770 MRR_FL_CAN_DET_AMPLITUDE_021 "Detected object amplitude";
BA_ "GenSigStartValue" SG_ 770 MRR_FL_CAN_DET_AMPLITUDE_021 64;
BA_ "GenSigCmt" SG_ 770 MRR_FL_CAN_DET_VALID_LEVEL_021 "Detected object valid level";
BA_ "GenSigCmt" SG_ 770 MRR_FL_CAN_DET_ELEVATION_020 "Detected object elevation position";
BA_ "GenSigStartValue" SG_ 770 MRR_FL_CAN_DET_ELEVATION_020 63.8646288209607;
BA_ "GenSigCmt" SG_ 770 MRR_FL_CAN_DET_SUPER_RES_TA_0015 "Super resolution target";
BA_ "SystemSignalLongSymbol" SG_ 770 MRR_FL_CAN_DET_SUPER_RES_TA_0015 "MRR_FL_CAN_DET_SUPER_RES_TARGET_020";
BA_ "GenSigCmt" SG_ 770 MRR_FL_CAN_DET_AZIMUTH_020 "Detected object azimuth position";
BA_ "GenSigStartValue" SG_ 770 MRR_FL_CAN_DET_AZIMUTH_020 8194.05320813772;
BA_ "GenSigCmt" SG_ 770 MRR_FL_CAN_DET_CONFID_ELEVA_0015 "Elevation Angle Confidence";
BA_ "SystemSignalLongSymbol" SG_ 770 MRR_FL_CAN_DET_CONFID_ELEVA_0015 "MRR_FL_CAN_DET_CONFID_ELEVATION_020";
BA_ "GenSigCmt" SG_ 770 MRR_FL_CAN_DET_HOST_VEH_CLU_0015 "Host vehicle clutter";
BA_ "SystemSignalLongSymbol" SG_ 770 MRR_FL_CAN_DET_HOST_VEH_CLU_0015 "MRR_FL_CAN_DET_HOST_VEH_CLUTTER_020";
BA_ "GenSigCmt" SG_ 770 MRR_FL_CAN_DET_RANGE_020 "Detected object range";
BA_ "GenSigVtEn" SG_ 770 MRR_FL_CAN_DET_CONFID_AZIMU_0013 "TRUE";
BA_ "GenSigCmt" SG_ 770 MRR_FL_CAN_DET_CONFID_AZIMU_0013 "Signal to noise level";
BA_ "SystemSignalLongSymbol" SG_ 770 MRR_FL_CAN_DET_CONFID_AZIMU_0013 "MRR_FL_CAN_DET_CONFID_AZIMUTH_020";
BA_ "GenSigCmt" SG_ 770 MRR_FL_CAN_DET_RANGE_RATE_020 "Detected object range rate";
BA_ "GenSigStartValue" SG_ 770 MRR_FL_CAN_DET_RANGE_RATE_020 8192;
BA_ "GenSigCmt" SG_ 770 MRR_FL_CAN_SCAN_INDEX_2LSB_020 "The two LSB of scan index";
BA_ "GenSigCmt" SG_ 770 MRR_FL_CAN_DET_AMPLITUDE_020 "Detected object amplitude";
BA_ "GenSigStartValue" SG_ 770 MRR_FL_CAN_DET_AMPLITUDE_020 64;
BA_ "GenSigCmt" SG_ 770 MRR_FL_CAN_DET_VALID_LEVEL_020 "Detected object valid level";
BA_ "GenSigCmt" SG_ 770 MRR_FL_CAN_DET_ELEVATION_019 "Detected object elevation position";
BA_ "GenSigStartValue" SG_ 770 MRR_FL_CAN_DET_ELEVATION_019 63.8646288209607;
BA_ "GenSigCmt" SG_ 770 MRR_FL_CAN_DET_SUPER_RES_TA_0016 "Super resolution target";
BA_ "SystemSignalLongSymbol" SG_ 770 MRR_FL_CAN_DET_SUPER_RES_TA_0016 "MRR_FL_CAN_DET_SUPER_RES_TARGET_019";
BA_ "GenSigCmt" SG_ 770 MRR_FL_CAN_DET_AZIMUTH_019 "Detected object azimuth position";
BA_ "GenSigStartValue" SG_ 770 MRR_FL_CAN_DET_AZIMUTH_019 8194.05320813772;
BA_ "GenSigCmt" SG_ 770 MRR_FL_CAN_DET_CONFID_ELEVA_0016 "Elevation Angle Confidence";
BA_ "SystemSignalLongSymbol" SG_ 770 MRR_FL_CAN_DET_CONFID_ELEVA_0016 "MRR_FL_CAN_DET_CONFID_ELEVATION_019";
BA_ "GenSigCmt" SG_ 770 MRR_FL_CAN_DET_HOST_VEH_CLU_0016 "Host vehicle clutter";
BA_ "SystemSignalLongSymbol" SG_ 770 MRR_FL_CAN_DET_HOST_VEH_CLU_0016 "MRR_FL_CAN_DET_HOST_VEH_CLUTTER_019";
BA_ "GenSigCmt" SG_ 770 MRR_FL_CAN_DET_RANGE_019 "Detected object range";
BA_ "GenSigVtEn" SG_ 770 MRR_FL_CAN_DET_CONFID_AZIMU_0014 "TRUE";
BA_ "GenSigCmt" SG_ 770 MRR_FL_CAN_DET_CONFID_AZIMU_0014 "Signal to noise level";
BA_ "SystemSignalLongSymbol" SG_ 770 MRR_FL_CAN_DET_CONFID_AZIMU_0014 "MRR_FL_CAN_DET_CONFID_AZIMUTH_019";
BA_ "GenSigCmt" SG_ 770 MRR_FL_CAN_DET_RANGE_RATE_019 "Detected object range rate";
BA_ "GenSigStartValue" SG_ 770 MRR_FL_CAN_DET_RANGE_RATE_019 8192;
BA_ "GenSigCmt" SG_ 770 MRR_FL_CAN_SCAN_INDEX_2LSB_019 "The two LSB of scan index";
BA_ "GenSigCmt" SG_ 770 MRR_FL_CAN_DET_AMPLITUDE_019 "Detected object amplitude";
BA_ "GenSigStartValue" SG_ 770 MRR_FL_CAN_DET_AMPLITUDE_019 64;
BA_ "GenSigCmt" SG_ 770 MRR_FL_CAN_DET_VALID_LEVEL_019 "Detected object valid level";
BA_ "GenSigCmt" SG_ 770 MRR_FL_CAN_DET_ELEVATION_018 "Detected object elevation position";
BA_ "GenSigStartValue" SG_ 770 MRR_FL_CAN_DET_ELEVATION_018 63.8646288209607;
BA_ "GenSigCmt" SG_ 770 MRR_FL_CAN_DET_SUPER_RES_TA_0017 "Super resolution target";
BA_ "SystemSignalLongSymbol" SG_ 770 MRR_FL_CAN_DET_SUPER_RES_TA_0017 "MRR_FL_CAN_DET_SUPER_RES_TARGET_018";
BA_ "GenSigCmt" SG_ 770 MRR_FL_CAN_DET_AZIMUTH_018 "Detected object azimuth position";
BA_ "GenSigStartValue" SG_ 770 MRR_FL_CAN_DET_AZIMUTH_018 8194.05320813772;
BA_ "GenSigCmt" SG_ 770 MRR_FL_CAN_DET_CONFID_ELEVA_0017 "Elevation Angle Confidence";
BA_ "SystemSignalLongSymbol" SG_ 770 MRR_FL_CAN_DET_CONFID_ELEVA_0017 "MRR_FL_CAN_DET_CONFID_ELEVATION_018";
BA_ "GenSigCmt" SG_ 770 MRR_FL_CAN_DET_HOST_VEH_CLU_0017 "Host vehicle clutter";
BA_ "SystemSignalLongSymbol" SG_ 770 MRR_FL_CAN_DET_HOST_VEH_CLU_0017 "MRR_FL_CAN_DET_HOST_VEH_CLUTTER_018";
BA_ "GenSigCmt" SG_ 770 MRR_FL_CAN_DET_RANGE_018 "Detected object range";
BA_ "GenSigVtEn" SG_ 770 MRR_FL_CAN_DET_CONFID_AZIMU_0015 "TRUE";
BA_ "GenSigCmt" SG_ 770 MRR_FL_CAN_DET_CONFID_AZIMU_0015 "Signal to noise level";
BA_ "SystemSignalLongSymbol" SG_ 770 MRR_FL_CAN_DET_CONFID_AZIMU_0015 "MRR_FL_CAN_DET_CONFID_AZIMUTH_018";
BA_ "GenSigCmt" SG_ 770 MRR_FL_CAN_DET_RANGE_RATE_018 "Detected object range rate";
BA_ "GenSigStartValue" SG_ 770 MRR_FL_CAN_DET_RANGE_RATE_018 8192;
BA_ "GenSigCmt" SG_ 770 MRR_FL_CAN_SCAN_INDEX_2LSB_018 "The two LSB of scan index";
BA_ "GenSigCmt" SG_ 770 MRR_FL_CAN_DET_AMPLITUDE_018 "Detected object amplitude";
BA_ "GenSigStartValue" SG_ 770 MRR_FL_CAN_DET_AMPLITUDE_018 64;
BA_ "GenSigCmt" SG_ 770 MRR_FL_CAN_DET_VALID_LEVEL_018 "Detected object valid level";
BA_ "GenSigCmt" SG_ 770 MRR_FL_CAN_DET_ELEVATION_017 "Detected object elevation position";
BA_ "GenSigStartValue" SG_ 770 MRR_FL_CAN_DET_ELEVATION_017 63.8646288209607;
BA_ "GenSigCmt" SG_ 770 MRR_FL_CAN_DET_SUPER_RES_TA_0018 "Super resolution target";
BA_ "SystemSignalLongSymbol" SG_ 770 MRR_FL_CAN_DET_SUPER_RES_TA_0018 "MRR_FL_CAN_DET_SUPER_RES_TARGET_017";
BA_ "GenSigCmt" SG_ 770 MRR_FL_CAN_DET_AZIMUTH_017 "Detected object azimuth position";
BA_ "GenSigStartValue" SG_ 770 MRR_FL_CAN_DET_AZIMUTH_017 8194.05320813772;
BA_ "GenSigCmt" SG_ 770 MRR_FL_CAN_DET_CONFID_ELEVA_0018 "Elevation Angle Confidence";
BA_ "SystemSignalLongSymbol" SG_ 770 MRR_FL_CAN_DET_CONFID_ELEVA_0018 "MRR_FL_CAN_DET_CONFID_ELEVATION_017";
BA_ "GenSigCmt" SG_ 770 MRR_FL_CAN_DET_HOST_VEH_CLU_0018 "Host vehicle clutter";
BA_ "SystemSignalLongSymbol" SG_ 770 MRR_FL_CAN_DET_HOST_VEH_CLU_0018 "MRR_FL_CAN_DET_HOST_VEH_CLUTTER_017";
BA_ "GenSigCmt" SG_ 770 MRR_FL_CAN_DET_RANGE_017 "Detected object range";
BA_ "GenSigVtEn" SG_ 770 MRR_FL_CAN_DET_CONFID_AZIMU_0016 "TRUE";
BA_ "GenSigCmt" SG_ 770 MRR_FL_CAN_DET_CONFID_AZIMU_0016 "Signal to noise level";
BA_ "SystemSignalLongSymbol" SG_ 770 MRR_FL_CAN_DET_CONFID_AZIMU_0016 "MRR_FL_CAN_DET_CONFID_AZIMUTH_017";
BA_ "GenSigCmt" SG_ 770 MRR_FL_CAN_DET_RANGE_RATE_017 "Detected object range rate";
BA_ "GenSigStartValue" SG_ 770 MRR_FL_CAN_DET_RANGE_RATE_017 8192;
BA_ "GenSigCmt" SG_ 770 MRR_FL_CAN_SCAN_INDEX_2LSB_017 "The two LSB of scan index";
BA_ "GenSigCmt" SG_ 770 MRR_FL_CAN_DET_AMPLITUDE_017 "Detected object amplitude";
BA_ "GenSigStartValue" SG_ 770 MRR_FL_CAN_DET_AMPLITUDE_017 64;
BA_ "GenSigCmt" SG_ 770 MRR_FL_CAN_DET_VALID_LEVEL_017 "Detected object valid level";
BA_ "GenSigCmt" SG_ 770 MRR_FL_CAN_DET_ELEVATION_016 "Detected object elevation position";
BA_ "GenSigStartValue" SG_ 770 MRR_FL_CAN_DET_ELEVATION_016 63.8646288209607;
BA_ "GenSigCmt" SG_ 770 MRR_FL_CAN_DET_SUPER_RES_TA_0019 "Super resolution target";
BA_ "SystemSignalLongSymbol" SG_ 770 MRR_FL_CAN_DET_SUPER_RES_TA_0019 "MRR_FL_CAN_DET_SUPER_RES_TARGET_016";
BA_ "GenSigCmt" SG_ 770 MRR_FL_CAN_DET_AZIMUTH_016 "Detected object azimuth position";
BA_ "GenSigStartValue" SG_ 770 MRR_FL_CAN_DET_AZIMUTH_016 8194.05320813772;
BA_ "GenSigCmt" SG_ 770 MRR_FL_CAN_DET_CONFID_ELEVA_0019 "Elevation Angle Confidence";
BA_ "SystemSignalLongSymbol" SG_ 770 MRR_FL_CAN_DET_CONFID_ELEVA_0019 "MRR_FL_CAN_DET_CONFID_ELEVATION_016";
BA_ "GenSigCmt" SG_ 770 MRR_FL_CAN_DET_HOST_VEH_CLU_0019 "Host vehicle clutter";
BA_ "SystemSignalLongSymbol" SG_ 770 MRR_FL_CAN_DET_HOST_VEH_CLU_0019 "MRR_FL_CAN_DET_HOST_VEH_CLUTTER_016";
BA_ "GenSigCmt" SG_ 770 MRR_FL_CAN_DET_RANGE_016 "Detected object range";
BA_ "GenSigVtEn" SG_ 770 MRR_FL_CAN_DET_CONFID_AZIMU_0017 "TRUE";
BA_ "GenSigCmt" SG_ 770 MRR_FL_CAN_DET_CONFID_AZIMU_0017 "Signal to noise level";
BA_ "SystemSignalLongSymbol" SG_ 770 MRR_FL_CAN_DET_CONFID_AZIMU_0017 "MRR_FL_CAN_DET_CONFID_AZIMUTH_016";
BA_ "GenSigCmt" SG_ 770 MRR_FL_CAN_DET_RANGE_RATE_016 "Detected object range rate";
BA_ "GenSigStartValue" SG_ 770 MRR_FL_CAN_DET_RANGE_RATE_016 8192;
BA_ "GenSigCmt" SG_ 770 MRR_FL_CAN_SCAN_INDEX_2LSB_016 "The two LSB of scan index";
BA_ "GenSigCmt" SG_ 770 MRR_FL_CAN_DET_AMPLITUDE_016 "Detected object amplitude";
BA_ "GenSigStartValue" SG_ 770 MRR_FL_CAN_DET_AMPLITUDE_016 64;
BA_ "GenSigCmt" SG_ 770 MRR_FL_CAN_DET_VALID_LEVEL_016 "Detected object valid level";
BA_ "SignalDescription" SG_ 771 MRR_FL_CAN_DET_MID_TARGET_028 "MID_Target_Discrimination";
BA_ "GenSigSendType" SG_ 771 MRR_FL_CAN_DET_MID_TARGET_028 1;
BA_ "SignalDescription" SG_ 771 MRR_FL_CAN_DET_MID_TARGET_027 "MID_Target_Discrimination";
BA_ "SignalDescription" SG_ 771 MRR_FL_CAN_DET_MID_TARGET_026 "MID_Target_Discrimination";
BA_ "SignalDescription" SG_ 771 MRR_FL_CAN_DET_MID_TARGET_025 "MID_Target_Discrimination";
BA_ "SignalDescription" SG_ 771 MRR_FL_CAN_DET_MID_TARGET_024 "MID_Target_Discrimination";
BA_ "SignalDescription" SG_ 771 MRR_FL_CAN_DET_MID_TARGET_023 "MID_Target_Discrimination";
BA_ "SignalDescription" SG_ 771 MRR_FL_CAN_DET_MID_TARGET_022 "MID_Target_Discrimination";
BA_ "SignalDescription" SG_ 771 MRR_FL_CAN_DET_Near_TARGET_022 "Near_Target_Discrimination";
BA_ "SignalDescription" SG_ 771 MRR_FL_CAN_DET_Near_TARGET_023 "Near_Target_Discrimination";
BA_ "SignalDescription" SG_ 771 MRR_FL_CAN_DET_Near_TARGET_024 "Near_Target_Discrimination";
BA_ "SignalDescription" SG_ 771 MRR_FL_CAN_DET_Near_TARGET_025 "Near_Target_Discrimination";
BA_ "SignalDescription" SG_ 771 MRR_FL_CAN_DET_Near_TARGET_026 "Near_Target_Discrimination";
BA_ "SignalDescription" SG_ 771 MRR_FL_CAN_DET_Near_TARGET_027 "Near_Target_Discrimination";
BA_ "SignalDescription" SG_ 771 MRR_FL_CAN_DET_Near_TARGET_028 "Near_Target_Discrimination";
BA_ "GenSigCmt" SG_ 771 MRR_FL_CAN_DET_ELEVATION_022 "Detected object elevation position";
BA_ "GenSigStartValue" SG_ 771 MRR_FL_CAN_DET_ELEVATION_022 63.8646288209607;
BA_ "GenSigCmt" SG_ 771 MRR_FL_CAN_DET_CONFID_AZIMU_0018 "Signal to noise level";
BA_ "GenSigVtEn" SG_ 771 MRR_FL_CAN_DET_CONFID_AZIMU_0018 "TRUE";
BA_ "SystemSignalLongSymbol" SG_ 771 MRR_FL_CAN_DET_CONFID_AZIMU_0018 "MRR_FL_CAN_DET_CONFID_AZIMUTH_022";
BA_ "GenSigCmt" SG_ 771 MRR_FL_CAN_DET_SUPER_RES_TA_0020 "Super resolution target";
BA_ "SystemSignalLongSymbol" SG_ 771 MRR_FL_CAN_DET_SUPER_RES_TA_0020 "MRR_FL_CAN_DET_SUPER_RES_TARGET_022";
BA_ "GenSigCmt" SG_ 771 MRR_FL_CAN_DET_CONFID_ELEVA_0020 "Elevation Angle Confidence";
BA_ "SystemSignalLongSymbol" SG_ 771 MRR_FL_CAN_DET_CONFID_ELEVA_0020 "MRR_FL_CAN_DET_CONFID_ELEVATION_022";
BA_ "GenSigCmt" SG_ 771 MRR_FL_CAN_DET_HOST_VEH_CLU_0020 "Host vehicle clutter";
BA_ "SystemSignalLongSymbol" SG_ 771 MRR_FL_CAN_DET_HOST_VEH_CLU_0020 "MRR_FL_CAN_DET_HOST_VEH_CLUTTER_022";
BA_ "GenSigCmt" SG_ 771 MRR_FL_CAN_DET_VALID_LEVEL_022 "Detected object valid level";
BA_ "GenSigCmt" SG_ 771 MRR_FL_CAN_DET_AZIMUTH_022 "Detected object azimuth position";
BA_ "GenSigStartValue" SG_ 771 MRR_FL_CAN_DET_AZIMUTH_022 8194.05320813772;
BA_ "GenSigCmt" SG_ 771 MRR_FL_CAN_DET_RANGE_022 "Detected object range";
BA_ "GenSigCmt" SG_ 771 MRR_FL_CAN_DET_RANGE_RATE_022 "Detected object range rate";
BA_ "GenSigStartValue" SG_ 771 MRR_FL_CAN_DET_RANGE_RATE_022 8192;
BA_ "GenSigCmt" SG_ 771 MRR_FL_CAN_DET_AMPLITUDE_022 "Detected object amplitude";
BA_ "GenSigStartValue" SG_ 771 MRR_FL_CAN_DET_AMPLITUDE_022 64;
BA_ "GenSigCmt" SG_ 771 MRR_FL_CAN_SCAN_INDEX_2LSB_022 "The two LSB of scan index";
BA_ "GenSigStartValue" SG_ 771 MRR_FL_CAN_DET_ELEVATION_028 63.8646288209607;
BA_ "GenSigCmt" SG_ 771 MRR_FL_CAN_DET_ELEVATION_028 "Detected object elevation position";
BA_ "GenSigCmt" SG_ 771 MRR_FL_CAN_DET_SUPER_RES_TA_0021 "Super resolution target";
BA_ "SystemSignalLongSymbol" SG_ 771 MRR_FL_CAN_DET_SUPER_RES_TA_0021 "MRR_FL_CAN_DET_SUPER_RES_TARGET_028";
BA_ "GenSigCmt" SG_ 771 MRR_FL_CAN_DET_AZIMUTH_028 "Detected object azimuth position";
BA_ "GenSigStartValue" SG_ 771 MRR_FL_CAN_DET_AZIMUTH_028 8194.05320813772;
BA_ "GenSigCmt" SG_ 771 MRR_FL_CAN_DET_CONFID_ELEVA_0021 "Elevation Angle Confidence";
BA_ "SystemSignalLongSymbol" SG_ 771 MRR_FL_CAN_DET_CONFID_ELEVA_0021 "MRR_FL_CAN_DET_CONFID_ELEVATION_028";
BA_ "GenSigCmt" SG_ 771 MRR_FL_CAN_DET_HOST_VEH_CLU_0021 "Host vehicle clutter";
BA_ "SystemSignalLongSymbol" SG_ 771 MRR_FL_CAN_DET_HOST_VEH_CLU_0021 "MRR_FL_CAN_DET_HOST_VEH_CLUTTER_028";
BA_ "GenSigCmt" SG_ 771 MRR_FL_CAN_DET_RANGE_028 "Detected object range";
BA_ "GenSigCmt" SG_ 771 MRR_FL_CAN_DET_CONFID_AZIMU_0019 "Signal to noise level";
BA_ "GenSigVtEn" SG_ 771 MRR_FL_CAN_DET_CONFID_AZIMU_0019 "TRUE";
BA_ "SystemSignalLongSymbol" SG_ 771 MRR_FL_CAN_DET_CONFID_AZIMU_0019 "MRR_FL_CAN_DET_CONFID_AZIMUTH_028";
BA_ "GenSigCmt" SG_ 771 MRR_FL_CAN_DET_RANGE_RATE_028 "Detected object range rate";
BA_ "GenSigStartValue" SG_ 771 MRR_FL_CAN_DET_RANGE_RATE_028 8192;
BA_ "GenSigCmt" SG_ 771 MRR_FL_CAN_SCAN_INDEX_2LSB_028 "The two LSB of scan index";
BA_ "GenSigCmt" SG_ 771 MRR_FL_CAN_DET_AMPLITUDE_028 "Detected object amplitude";
BA_ "GenSigStartValue" SG_ 771 MRR_FL_CAN_DET_AMPLITUDE_028 64;
BA_ "GenSigCmt" SG_ 771 MRR_FL_CAN_DET_VALID_LEVEL_028 "Detected object valid level";
BA_ "GenSigCmt" SG_ 771 MRR_FL_CAN_DET_ELEVATION_027 "Detected object elevation position";
BA_ "GenSigStartValue" SG_ 771 MRR_FL_CAN_DET_ELEVATION_027 63.8646288209607;
BA_ "GenSigCmt" SG_ 771 MRR_FL_CAN_DET_SUPER_RES_TA_0022 "Super resolution target";
BA_ "SystemSignalLongSymbol" SG_ 771 MRR_FL_CAN_DET_SUPER_RES_TA_0022 "MRR_FL_CAN_DET_SUPER_RES_TARGET_027";
BA_ "GenSigCmt" SG_ 771 MRR_FL_CAN_DET_AZIMUTH_027 "Detected object azimuth position";
BA_ "GenSigStartValue" SG_ 771 MRR_FL_CAN_DET_AZIMUTH_027 8194.05320813772;
BA_ "GenSigCmt" SG_ 771 MRR_FL_CAN_DET_CONFID_ELEVA_0022 "Elevation Angle Confidence";
BA_ "SystemSignalLongSymbol" SG_ 771 MRR_FL_CAN_DET_CONFID_ELEVA_0022 "MRR_FL_CAN_DET_CONFID_ELEVATION_027";
BA_ "GenSigCmt" SG_ 771 MRR_FL_CAN_DET_HOST_VEH_CLU_0022 "Host vehicle clutter";
BA_ "SystemSignalLongSymbol" SG_ 771 MRR_FL_CAN_DET_HOST_VEH_CLU_0022 "MRR_FL_CAN_DET_HOST_VEH_CLUTTER_027";
BA_ "GenSigCmt" SG_ 771 MRR_FL_CAN_DET_RANGE_027 "Detected object range";
BA_ "GenSigCmt" SG_ 771 MRR_FL_CAN_DET_CONFID_AZIMU_0020 "Signal to noise level";
BA_ "GenSigVtEn" SG_ 771 MRR_FL_CAN_DET_CONFID_AZIMU_0020 "TRUE";
BA_ "SystemSignalLongSymbol" SG_ 771 MRR_FL_CAN_DET_CONFID_AZIMU_0020 "MRR_FL_CAN_DET_CONFID_AZIMUTH_027";
BA_ "GenSigCmt" SG_ 771 MRR_FL_CAN_DET_RANGE_RATE_027 "Detected object range rate";
BA_ "GenSigStartValue" SG_ 771 MRR_FL_CAN_DET_RANGE_RATE_027 8192;
BA_ "GenSigCmt" SG_ 771 MRR_FL_CAN_SCAN_INDEX_2LSB_027 "The two LSB of scan index";
BA_ "GenSigCmt" SG_ 771 MRR_FL_CAN_DET_AMPLITUDE_027 "Detected object amplitude";
BA_ "GenSigStartValue" SG_ 771 MRR_FL_CAN_DET_AMPLITUDE_027 64;
BA_ "GenSigCmt" SG_ 771 MRR_FL_CAN_DET_VALID_LEVEL_027 "Detected object valid level";
BA_ "GenSigCmt" SG_ 771 MRR_FL_CAN_DET_ELEVATION_026 "Detected object elevation position";
BA_ "GenSigStartValue" SG_ 771 MRR_FL_CAN_DET_ELEVATION_026 63.8646288209607;
BA_ "GenSigCmt" SG_ 771 MRR_FL_CAN_DET_SUPER_RES_TA_0023 "Super resolution target";
BA_ "SystemSignalLongSymbol" SG_ 771 MRR_FL_CAN_DET_SUPER_RES_TA_0023 "MRR_FL_CAN_DET_SUPER_RES_TARGET_026";
BA_ "GenSigCmt" SG_ 771 MRR_FL_CAN_DET_AZIMUTH_026 "Detected object azimuth position";
BA_ "GenSigStartValue" SG_ 771 MRR_FL_CAN_DET_AZIMUTH_026 8194.05320813772;
BA_ "GenSigCmt" SG_ 771 MRR_FL_CAN_DET_CONFID_ELEVA_0023 "Elevation Angle Confidence";
BA_ "SystemSignalLongSymbol" SG_ 771 MRR_FL_CAN_DET_CONFID_ELEVA_0023 "MRR_FL_CAN_DET_CONFID_ELEVATION_026";
BA_ "GenSigCmt" SG_ 771 MRR_FL_CAN_DET_HOST_VEH_CLU_0023 "Host vehicle clutter";
BA_ "SystemSignalLongSymbol" SG_ 771 MRR_FL_CAN_DET_HOST_VEH_CLU_0023 "MRR_FL_CAN_DET_HOST_VEH_CLUTTER_026";
BA_ "GenSigCmt" SG_ 771 MRR_FL_CAN_DET_RANGE_026 "Detected object range";
BA_ "GenSigCmt" SG_ 771 MRR_FL_CAN_DET_CONFID_AZIMU_0021 "Signal to noise level";
BA_ "GenSigVtEn" SG_ 771 MRR_FL_CAN_DET_CONFID_AZIMU_0021 "TRUE";
BA_ "SystemSignalLongSymbol" SG_ 771 MRR_FL_CAN_DET_CONFID_AZIMU_0021 "MRR_FL_CAN_DET_CONFID_AZIMUTH_026";
BA_ "GenSigCmt" SG_ 771 MRR_FL_CAN_DET_RANGE_RATE_026 "Detected object range rate";
BA_ "GenSigStartValue" SG_ 771 MRR_FL_CAN_DET_RANGE_RATE_026 8192;
BA_ "GenSigCmt" SG_ 771 MRR_FL_CAN_SCAN_INDEX_2LSB_026 "The two LSB of scan index";
BA_ "GenSigCmt" SG_ 771 MRR_FL_CAN_DET_AMPLITUDE_026 "Detected object amplitude";
BA_ "GenSigStartValue" SG_ 771 MRR_FL_CAN_DET_AMPLITUDE_026 64;
BA_ "GenSigCmt" SG_ 771 MRR_FL_CAN_DET_VALID_LEVEL_026 "Detected object valid level";
BA_ "GenSigCmt" SG_ 771 MRR_FL_CAN_DET_ELEVATION_025 "Detected object elevation position";
BA_ "GenSigStartValue" SG_ 771 MRR_FL_CAN_DET_ELEVATION_025 63.8646288209607;
BA_ "GenSigCmt" SG_ 771 MRR_FL_CAN_DET_SUPER_RES_TA_0024 "Super resolution target";
BA_ "SystemSignalLongSymbol" SG_ 771 MRR_FL_CAN_DET_SUPER_RES_TA_0024 "MRR_FL_CAN_DET_SUPER_RES_TARGET_025";
BA_ "GenSigCmt" SG_ 771 MRR_FL_CAN_DET_AZIMUTH_025 "Detected object azimuth position";
BA_ "GenSigStartValue" SG_ 771 MRR_FL_CAN_DET_AZIMUTH_025 8194.05320813772;
BA_ "GenSigCmt" SG_ 771 MRR_FL_CAN_DET_CONFID_ELEVA_0024 "Elevation Angle Confidence";
BA_ "SystemSignalLongSymbol" SG_ 771 MRR_FL_CAN_DET_CONFID_ELEVA_0024 "MRR_FL_CAN_DET_CONFID_ELEVATION_025";
BA_ "GenSigCmt" SG_ 771 MRR_FL_CAN_DET_HOST_VEH_CLU_0024 "Host vehicle clutter";
BA_ "SystemSignalLongSymbol" SG_ 771 MRR_FL_CAN_DET_HOST_VEH_CLU_0024 "MRR_FL_CAN_DET_HOST_VEH_CLUTTER_025";
BA_ "GenSigCmt" SG_ 771 MRR_FL_CAN_DET_RANGE_025 "Detected object range";
BA_ "GenSigCmt" SG_ 771 MRR_FL_CAN_DET_CONFID_AZIMU_0022 "Signal to noise level";
BA_ "GenSigVtEn" SG_ 771 MRR_FL_CAN_DET_CONFID_AZIMU_0022 "TRUE";
BA_ "SystemSignalLongSymbol" SG_ 771 MRR_FL_CAN_DET_CONFID_AZIMU_0022 "MRR_FL_CAN_DET_CONFID_AZIMUTH_025";
BA_ "GenSigCmt" SG_ 771 MRR_FL_CAN_DET_RANGE_RATE_025 "Detected object range rate";
BA_ "GenSigStartValue" SG_ 771 MRR_FL_CAN_DET_RANGE_RATE_025 8192;
BA_ "GenSigCmt" SG_ 771 MRR_FL_CAN_SCAN_INDEX_2LSB_025 "The two LSB of scan index";
BA_ "GenSigCmt" SG_ 771 MRR_FL_CAN_DET_AMPLITUDE_025 "Detected object amplitude";
BA_ "GenSigStartValue" SG_ 771 MRR_FL_CAN_DET_AMPLITUDE_025 64;
BA_ "GenSigCmt" SG_ 771 MRR_FL_CAN_DET_VALID_LEVEL_025 "Detected object valid level";
BA_ "GenSigCmt" SG_ 771 MRR_FL_CAN_DET_ELEVATION_024 "Detected object elevation position";
BA_ "GenSigStartValue" SG_ 771 MRR_FL_CAN_DET_ELEVATION_024 63.8646288209607;
BA_ "GenSigCmt" SG_ 771 MRR_FL_CAN_DET_SUPER_RES_TA_0025 "Super resolution target";
BA_ "SystemSignalLongSymbol" SG_ 771 MRR_FL_CAN_DET_SUPER_RES_TA_0025 "MRR_FL_CAN_DET_SUPER_RES_TARGET_024";
BA_ "GenSigCmt" SG_ 771 MRR_FL_CAN_DET_AZIMUTH_024 "Detected object azimuth position";
BA_ "GenSigStartValue" SG_ 771 MRR_FL_CAN_DET_AZIMUTH_024 8194.05320813772;
BA_ "GenSigCmt" SG_ 771 MRR_FL_CAN_DET_CONFID_ELEVA_0025 "Elevation Angle Confidence";
BA_ "SystemSignalLongSymbol" SG_ 771 MRR_FL_CAN_DET_CONFID_ELEVA_0025 "MRR_FL_CAN_DET_CONFID_ELEVATION_024";
BA_ "GenSigCmt" SG_ 771 MRR_FL_CAN_DET_HOST_VEH_CLU_0025 "Host vehicle clutter";
BA_ "SystemSignalLongSymbol" SG_ 771 MRR_FL_CAN_DET_HOST_VEH_CLU_0025 "MRR_FL_CAN_DET_HOST_VEH_CLUTTER_024";
BA_ "GenSigCmt" SG_ 771 MRR_FL_CAN_DET_RANGE_024 "Detected object range";
BA_ "GenSigCmt" SG_ 771 MRR_FL_CAN_DET_CONFID_AZIMU_0023 "Signal to noise level";
BA_ "GenSigVtEn" SG_ 771 MRR_FL_CAN_DET_CONFID_AZIMU_0023 "TRUE";
BA_ "SystemSignalLongSymbol" SG_ 771 MRR_FL_CAN_DET_CONFID_AZIMU_0023 "MRR_FL_CAN_DET_CONFID_AZIMUTH_024";
BA_ "GenSigCmt" SG_ 771 MRR_FL_CAN_DET_RANGE_RATE_024 "Detected object range rate";
BA_ "GenSigStartValue" SG_ 771 MRR_FL_CAN_DET_RANGE_RATE_024 8192;
BA_ "GenSigCmt" SG_ 771 MRR_FL_CAN_SCAN_INDEX_2LSB_024 "The two LSB of scan index";
BA_ "GenSigCmt" SG_ 771 MRR_FL_CAN_DET_AMPLITUDE_024 "Detected object amplitude";
BA_ "GenSigStartValue" SG_ 771 MRR_FL_CAN_DET_AMPLITUDE_024 64;
BA_ "GenSigCmt" SG_ 771 MRR_FL_CAN_DET_VALID_LEVEL_024 "Detected object valid level";
BA_ "GenSigCmt" SG_ 771 MRR_FL_CAN_DET_ELEVATION_023 "Detected object elevation position";
BA_ "GenSigStartValue" SG_ 771 MRR_FL_CAN_DET_ELEVATION_023 63.8646288209607;
BA_ "GenSigCmt" SG_ 771 MRR_FL_CAN_DET_SUPER_RES_TA_0026 "Super resolution target";
BA_ "SystemSignalLongSymbol" SG_ 771 MRR_FL_CAN_DET_SUPER_RES_TA_0026 "MRR_FL_CAN_DET_SUPER_RES_TARGET_023";
BA_ "GenSigCmt" SG_ 771 MRR_FL_CAN_DET_AZIMUTH_023 "Detected object azimuth position";
BA_ "GenSigStartValue" SG_ 771 MRR_FL_CAN_DET_AZIMUTH_023 8194.05320813772;
BA_ "GenSigCmt" SG_ 771 MRR_FL_CAN_DET_CONFID_ELEVA_0026 "Elevation Angle Confidence";
BA_ "SystemSignalLongSymbol" SG_ 771 MRR_FL_CAN_DET_CONFID_ELEVA_0026 "MRR_FL_CAN_DET_CONFID_ELEVATION_023";
BA_ "GenSigCmt" SG_ 771 MRR_FL_CAN_DET_HOST_VEH_CLU_0026 "Host vehicle clutter";
BA_ "SystemSignalLongSymbol" SG_ 771 MRR_FL_CAN_DET_HOST_VEH_CLU_0026 "MRR_FL_CAN_DET_HOST_VEH_CLUTTER_023";
BA_ "GenSigCmt" SG_ 771 MRR_FL_CAN_DET_RANGE_023 "Detected object range";
BA_ "GenSigCmt" SG_ 771 MRR_FL_CAN_DET_CONFID_AZIMU_0024 "Signal to noise level";
BA_ "GenSigVtEn" SG_ 771 MRR_FL_CAN_DET_CONFID_AZIMU_0024 "TRUE";
BA_ "SystemSignalLongSymbol" SG_ 771 MRR_FL_CAN_DET_CONFID_AZIMU_0024 "MRR_FL_CAN_DET_CONFID_AZIMUTH_023";
BA_ "GenSigCmt" SG_ 771 MRR_FL_CAN_DET_RANGE_RATE_023 "Detected object range rate";
BA_ "GenSigStartValue" SG_ 771 MRR_FL_CAN_DET_RANGE_RATE_023 8192;
BA_ "GenSigCmt" SG_ 771 MRR_FL_CAN_SCAN_INDEX_2LSB_023 "The two LSB of scan index";
BA_ "GenSigCmt" SG_ 771 MRR_FL_CAN_DET_AMPLITUDE_023 "Detected object amplitude";
BA_ "GenSigStartValue" SG_ 771 MRR_FL_CAN_DET_AMPLITUDE_023 64;
BA_ "GenSigCmt" SG_ 771 MRR_FL_CAN_DET_VALID_LEVEL_023 "Detected object valid level";
BA_ "SignalDescription" SG_ 772 MRR_FL_CAN_DET_MID_TARGET_035 "MID_Target_Discrimination";
BA_ "GenSigSendType" SG_ 772 MRR_FL_CAN_DET_MID_TARGET_035 1;
BA_ "SignalDescription" SG_ 772 MRR_FL_CAN_DET_MID_TARGET_034 "MID_Target_Discrimination";
BA_ "SignalDescription" SG_ 772 MRR_FL_CAN_DET_MID_TARGET_033 "MID_Target_Discrimination";
BA_ "SignalDescription" SG_ 772 MRR_FL_CAN_DET_MID_TARGET_032 "MID_Target_Discrimination";
BA_ "SignalDescription" SG_ 772 MRR_FL_CAN_DET_MID_TARGET_031 "MID_Target_Discrimination";
BA_ "SignalDescription" SG_ 772 MRR_FL_CAN_DET_MID_TARGET_030 "MID_Target_Discrimination";
BA_ "SignalDescription" SG_ 772 MRR_FL_CAN_DET_MID_TARGET_029 "MID_Target_Discrimination";
BA_ "SignalDescription" SG_ 772 MRR_FL_CAN_DET_Near_TARGET_029 "Near_Target_Discrimination";
BA_ "SignalDescription" SG_ 772 MRR_FL_CAN_DET_Near_TARGET_030 "Near_Target_Discrimination";
BA_ "SignalDescription" SG_ 772 MRR_FL_CAN_DET_Near_TARGET_031 "Near_Target_Discrimination";
BA_ "SignalDescription" SG_ 772 MRR_FL_CAN_DET_Near_TARGET_032 "Near_Target_Discrimination";
BA_ "SignalDescription" SG_ 772 MRR_FL_CAN_DET_Near_TARGET_033 "Near_Target_Discrimination";
BA_ "SignalDescription" SG_ 772 MRR_FL_CAN_DET_Near_TARGET_034 "Near_Target_Discrimination";
BA_ "SignalDescription" SG_ 772 MRR_FL_CAN_DET_Near_TARGET_035 "Near_Target_Discrimination";
BA_ "GenSigCmt" SG_ 772 MRR_FL_CAN_DET_ELEVATION_029 "Detected object elevation position";
BA_ "GenSigStartValue" SG_ 772 MRR_FL_CAN_DET_ELEVATION_029 63.8646288209607;
BA_ "GenSigCmt" SG_ 772 MRR_FL_CAN_DET_CONFID_AZIMU_0025 "Signal to noise level";
BA_ "GenSigVtEn" SG_ 772 MRR_FL_CAN_DET_CONFID_AZIMU_0025 "TRUE";
BA_ "SystemSignalLongSymbol" SG_ 772 MRR_FL_CAN_DET_CONFID_AZIMU_0025 "MRR_FL_CAN_DET_CONFID_AZIMUTH_029";
BA_ "GenSigCmt" SG_ 772 MRR_FL_CAN_DET_SUPER_RES_TA_0027 "Super resolution target";
BA_ "SystemSignalLongSymbol" SG_ 772 MRR_FL_CAN_DET_SUPER_RES_TA_0027 "MRR_FL_CAN_DET_SUPER_RES_TARGET_029";
BA_ "GenSigCmt" SG_ 772 MRR_FL_CAN_DET_CONFID_ELEVA_0027 "Elevation Angle Confidence";
BA_ "SystemSignalLongSymbol" SG_ 772 MRR_FL_CAN_DET_CONFID_ELEVA_0027 "MRR_FL_CAN_DET_CONFID_ELEVATION_029";
BA_ "GenSigCmt" SG_ 772 MRR_FL_CAN_DET_HOST_VEH_CLU_0027 "Host vehicle clutter";
BA_ "SystemSignalLongSymbol" SG_ 772 MRR_FL_CAN_DET_HOST_VEH_CLU_0027 "MRR_FL_CAN_DET_HOST_VEH_CLUTTER_029";
BA_ "GenSigCmt" SG_ 772 MRR_FL_CAN_DET_VALID_LEVEL_029 "Detected object valid level";
BA_ "GenSigCmt" SG_ 772 MRR_FL_CAN_DET_AZIMUTH_029 "Detected object azimuth position";
BA_ "GenSigStartValue" SG_ 772 MRR_FL_CAN_DET_AZIMUTH_029 8194.05320813772;
BA_ "GenSigCmt" SG_ 772 MRR_FL_CAN_DET_RANGE_029 "Detected object range";
BA_ "GenSigCmt" SG_ 772 MRR_FL_CAN_DET_RANGE_RATE_029 "Detected object range rate";
BA_ "GenSigStartValue" SG_ 772 MRR_FL_CAN_DET_RANGE_RATE_029 8192;
BA_ "GenSigCmt" SG_ 772 MRR_FL_CAN_DET_AMPLITUDE_029 "Detected object amplitude";
BA_ "GenSigStartValue" SG_ 772 MRR_FL_CAN_DET_AMPLITUDE_029 64;
BA_ "GenSigCmt" SG_ 772 MRR_FL_CAN_SCAN_INDEX_2LSB_029 "The two LSB of scan index";
BA_ "GenSigStartValue" SG_ 772 MRR_FL_CAN_DET_ELEVATION_035 63.8646288209607;
BA_ "GenSigCmt" SG_ 772 MRR_FL_CAN_DET_ELEVATION_035 "Detected object elevation position";
BA_ "GenSigCmt" SG_ 772 MRR_FL_CAN_DET_SUPER_RES_TA_0028 "Super resolution target";
BA_ "SystemSignalLongSymbol" SG_ 772 MRR_FL_CAN_DET_SUPER_RES_TA_0028 "MRR_FL_CAN_DET_SUPER_RES_TARGET_035";
BA_ "GenSigCmt" SG_ 772 MRR_FL_CAN_DET_AZIMUTH_035 "Detected object azimuth position";
BA_ "GenSigStartValue" SG_ 772 MRR_FL_CAN_DET_AZIMUTH_035 8194.05320813772;
BA_ "GenSigCmt" SG_ 772 MRR_FL_CAN_DET_CONFID_ELEVA_0028 "Elevation Angle Confidence";
BA_ "SystemSignalLongSymbol" SG_ 772 MRR_FL_CAN_DET_CONFID_ELEVA_0028 "MRR_FL_CAN_DET_CONFID_ELEVATION_035";
BA_ "GenSigCmt" SG_ 772 MRR_FL_CAN_DET_HOST_VEH_CLU_0028 "Host vehicle clutter";
BA_ "SystemSignalLongSymbol" SG_ 772 MRR_FL_CAN_DET_HOST_VEH_CLU_0028 "MRR_FL_CAN_DET_HOST_VEH_CLUTTER_035";
BA_ "GenSigCmt" SG_ 772 MRR_FL_CAN_DET_RANGE_035 "Detected object range";
BA_ "GenSigVtEn" SG_ 772 MRR_FL_CAN_DET_CONFID_AZIMUTH_03 "TRUE";
BA_ "GenSigCmt" SG_ 772 MRR_FL_CAN_DET_CONFID_AZIMUTH_03 "Signal to noise level";
BA_ "SystemSignalLongSymbol" SG_ 772 MRR_FL_CAN_DET_CONFID_AZIMUTH_03 "MRR_FL_CAN_DET_CONFID_AZIMUTH_035";
BA_ "GenSigCmt" SG_ 772 MRR_FL_CAN_DET_RANGE_RATE_035 "Detected object range rate";
BA_ "GenSigStartValue" SG_ 772 MRR_FL_CAN_DET_RANGE_RATE_035 8192;
BA_ "GenSigCmt" SG_ 772 MRR_FL_CAN_SCAN_INDEX_2LSB_035 "The two LSB of scan index";
BA_ "GenSigCmt" SG_ 772 MRR_FL_CAN_DET_AMPLITUDE_035 "Detected object amplitude";
BA_ "GenSigStartValue" SG_ 772 MRR_FL_CAN_DET_AMPLITUDE_035 64;
BA_ "GenSigCmt" SG_ 772 MRR_FL_CAN_DET_VALID_LEVEL_035 "Detected object valid level";
BA_ "GenSigCmt" SG_ 772 MRR_FL_CAN_DET_ELEVATION_034 "Detected object elevation position";
BA_ "GenSigStartValue" SG_ 772 MRR_FL_CAN_DET_ELEVATION_034 63.8646288209607;
BA_ "GenSigCmt" SG_ 772 MRR_FL_CAN_DET_SUPER_RES_TA_0029 "Super resolution target";
BA_ "SystemSignalLongSymbol" SG_ 772 MRR_FL_CAN_DET_SUPER_RES_TA_0029 "MRR_FL_CAN_DET_SUPER_RES_TARGET_034";
BA_ "GenSigCmt" SG_ 772 MRR_FL_CAN_DET_AZIMUTH_034 "Detected object azimuth position";
BA_ "GenSigStartValue" SG_ 772 MRR_FL_CAN_DET_AZIMUTH_034 8194.05320813772;
BA_ "GenSigCmt" SG_ 772 MRR_FL_CAN_DET_CONFID_ELEVA_0029 "Elevation Angle Confidence";
BA_ "SystemSignalLongSymbol" SG_ 772 MRR_FL_CAN_DET_CONFID_ELEVA_0029 "MRR_FL_CAN_DET_CONFID_ELEVATION_034";
BA_ "GenSigCmt" SG_ 772 MRR_FL_CAN_DET_HOST_VEH_CLU_0029 "Host vehicle clutter";
BA_ "SystemSignalLongSymbol" SG_ 772 MRR_FL_CAN_DET_HOST_VEH_CLU_0029 "MRR_FL_CAN_DET_HOST_VEH_CLUTTER_034";
BA_ "GenSigCmt" SG_ 772 MRR_FL_CAN_DET_RANGE_034 "Detected object range";
BA_ "GenSigVtEn" SG_ 772 MRR_FL_CAN_DET_CONFID_AZIMU_0026 "TRUE";
BA_ "GenSigCmt" SG_ 772 MRR_FL_CAN_DET_CONFID_AZIMU_0026 "Signal to noise level";
BA_ "SystemSignalLongSymbol" SG_ 772 MRR_FL_CAN_DET_CONFID_AZIMU_0026 "MRR_FL_CAN_DET_CONFID_AZIMUTH_034";
BA_ "GenSigCmt" SG_ 772 MRR_FL_CAN_DET_RANGE_RATE_034 "Detected object range rate";
BA_ "GenSigStartValue" SG_ 772 MRR_FL_CAN_DET_RANGE_RATE_034 8192;
BA_ "GenSigCmt" SG_ 772 MRR_FL_CAN_SCAN_INDEX_2LSB_034 "The two LSB of scan index";
BA_ "GenSigCmt" SG_ 772 MRR_FL_CAN_DET_AMPLITUDE_034 "Detected object amplitude";
BA_ "GenSigStartValue" SG_ 772 MRR_FL_CAN_DET_AMPLITUDE_034 64;
BA_ "GenSigCmt" SG_ 772 MRR_FL_CAN_DET_VALID_LEVEL_034 "Detected object valid level";
BA_ "GenSigCmt" SG_ 772 MRR_FL_CAN_DET_ELEVATION_033 "Detected object elevation position";
BA_ "GenSigStartValue" SG_ 772 MRR_FL_CAN_DET_ELEVATION_033 63.8646288209607;
BA_ "GenSigCmt" SG_ 772 MRR_FL_CAN_DET_SUPER_RES_TA_0030 "Super resolution target";
BA_ "SystemSignalLongSymbol" SG_ 772 MRR_FL_CAN_DET_SUPER_RES_TA_0030 "MRR_FL_CAN_DET_SUPER_RES_TARGET_033";
BA_ "GenSigCmt" SG_ 772 MRR_FL_CAN_DET_AZIMUTH_033 "Detected object azimuth position";
BA_ "GenSigStartValue" SG_ 772 MRR_FL_CAN_DET_AZIMUTH_033 8194.05320813772;
BA_ "GenSigCmt" SG_ 772 MRR_FL_CAN_DET_CONFID_ELEVA_0030 "Elevation Angle Confidence";
BA_ "SystemSignalLongSymbol" SG_ 772 MRR_FL_CAN_DET_CONFID_ELEVA_0030 "MRR_FL_CAN_DET_CONFID_ELEVATION_033";
BA_ "GenSigCmt" SG_ 772 MRR_FL_CAN_DET_HOST_VEH_CLU_0030 "Host vehicle clutter";
BA_ "SystemSignalLongSymbol" SG_ 772 MRR_FL_CAN_DET_HOST_VEH_CLU_0030 "MRR_FL_CAN_DET_HOST_VEH_CLUTTER_033";
BA_ "GenSigCmt" SG_ 772 MRR_FL_CAN_DET_RANGE_033 "Detected object range";
BA_ "GenSigVtEn" SG_ 772 MRR_FL_CAN_DET_CONFID_AZIMU_0027 "TRUE";
BA_ "GenSigCmt" SG_ 772 MRR_FL_CAN_DET_CONFID_AZIMU_0027 "Signal to noise level";
BA_ "SystemSignalLongSymbol" SG_ 772 MRR_FL_CAN_DET_CONFID_AZIMU_0027 "MRR_FL_CAN_DET_CONFID_AZIMUTH_033";
BA_ "GenSigCmt" SG_ 772 MRR_FL_CAN_DET_RANGE_RATE_033 "Detected object range rate";
BA_ "GenSigStartValue" SG_ 772 MRR_FL_CAN_DET_RANGE_RATE_033 8192;
BA_ "GenSigCmt" SG_ 772 MRR_FL_CAN_SCAN_INDEX_2LSB_033 "The two LSB of scan index";
BA_ "GenSigCmt" SG_ 772 MRR_FL_CAN_DET_AMPLITUDE_033 "Detected object amplitude";
BA_ "GenSigStartValue" SG_ 772 MRR_FL_CAN_DET_AMPLITUDE_033 64;
BA_ "GenSigCmt" SG_ 772 MRR_FL_CAN_DET_VALID_LEVEL_033 "Detected object valid level";
BA_ "GenSigCmt" SG_ 772 MRR_FL_CAN_DET_ELEVATION_032 "Detected object elevation position";
BA_ "GenSigStartValue" SG_ 772 MRR_FL_CAN_DET_ELEVATION_032 63.8646288209607;
BA_ "GenSigCmt" SG_ 772 MRR_FL_CAN_DET_SUPER_RES_TA_0031 "Super resolution target";
BA_ "SystemSignalLongSymbol" SG_ 772 MRR_FL_CAN_DET_SUPER_RES_TA_0031 "MRR_FL_CAN_DET_SUPER_RES_TARGET_032";
BA_ "GenSigCmt" SG_ 772 MRR_FL_CAN_DET_AZIMUTH_032 "Detected object azimuth position";
BA_ "GenSigStartValue" SG_ 772 MRR_FL_CAN_DET_AZIMUTH_032 8194.05320813772;
BA_ "GenSigCmt" SG_ 772 MRR_FL_CAN_DET_CONFID_ELEVA_0031 "Elevation Angle Confidence";
BA_ "SystemSignalLongSymbol" SG_ 772 MRR_FL_CAN_DET_CONFID_ELEVA_0031 "MRR_FL_CAN_DET_CONFID_ELEVATION_032";
BA_ "GenSigCmt" SG_ 772 MRR_FL_CAN_DET_HOST_VEH_CLU_0031 "Host vehicle clutter";
BA_ "SystemSignalLongSymbol" SG_ 772 MRR_FL_CAN_DET_HOST_VEH_CLU_0031 "MRR_FL_CAN_DET_HOST_VEH_CLUTTER_032";
BA_ "GenSigCmt" SG_ 772 MRR_FL_CAN_DET_RANGE_032 "Detected object range";
BA_ "GenSigVtEn" SG_ 772 MRR_FL_CAN_DET_CONFID_AZIMU_0028 "TRUE";
BA_ "GenSigCmt" SG_ 772 MRR_FL_CAN_DET_CONFID_AZIMU_0028 "Signal to noise level";
BA_ "SystemSignalLongSymbol" SG_ 772 MRR_FL_CAN_DET_CONFID_AZIMU_0028 "MRR_FL_CAN_DET_CONFID_AZIMUTH_032";
BA_ "GenSigCmt" SG_ 772 MRR_FL_CAN_DET_RANGE_RATE_032 "Detected object range rate";
BA_ "GenSigStartValue" SG_ 772 MRR_FL_CAN_DET_RANGE_RATE_032 8192;
BA_ "GenSigCmt" SG_ 772 MRR_FL_CAN_SCAN_INDEX_2LSB_032 "The two LSB of scan index";
BA_ "GenSigCmt" SG_ 772 MRR_FL_CAN_DET_AMPLITUDE_032 "Detected object amplitude";
BA_ "GenSigStartValue" SG_ 772 MRR_FL_CAN_DET_AMPLITUDE_032 64;
BA_ "GenSigCmt" SG_ 772 MRR_FL_CAN_DET_VALID_LEVEL_032 "Detected object valid level";
BA_ "GenSigCmt" SG_ 772 MRR_FL_CAN_DET_ELEVATION_031 "Detected object elevation position";
BA_ "GenSigStartValue" SG_ 772 MRR_FL_CAN_DET_ELEVATION_031 63.8646288209607;
BA_ "GenSigCmt" SG_ 772 MRR_FL_CAN_DET_SUPER_RES_TA_0032 "Super resolution target";
BA_ "SystemSignalLongSymbol" SG_ 772 MRR_FL_CAN_DET_SUPER_RES_TA_0032 "MRR_FL_CAN_DET_SUPER_RES_TARGET_031";
BA_ "GenSigCmt" SG_ 772 MRR_FL_CAN_DET_AZIMUTH_031 "Detected object azimuth position";
BA_ "GenSigStartValue" SG_ 772 MRR_FL_CAN_DET_AZIMUTH_031 8194.05320813772;
BA_ "GenSigCmt" SG_ 772 MRR_FL_CAN_DET_CONFID_ELEVA_0032 "Elevation Angle Confidence";
BA_ "SystemSignalLongSymbol" SG_ 772 MRR_FL_CAN_DET_CONFID_ELEVA_0032 "MRR_FL_CAN_DET_CONFID_ELEVATION_031";
BA_ "GenSigCmt" SG_ 772 MRR_FL_CAN_DET_HOST_VEH_CLU_0032 "Host vehicle clutter";
BA_ "SystemSignalLongSymbol" SG_ 772 MRR_FL_CAN_DET_HOST_VEH_CLU_0032 "MRR_FL_CAN_DET_HOST_VEH_CLUTTER_031";
BA_ "GenSigCmt" SG_ 772 MRR_FL_CAN_DET_RANGE_031 "Detected object range";
BA_ "GenSigVtEn" SG_ 772 MRR_FL_CAN_DET_CONFID_AZIMU_0029 "TRUE";
BA_ "GenSigCmt" SG_ 772 MRR_FL_CAN_DET_CONFID_AZIMU_0029 "Signal to noise level";
BA_ "SystemSignalLongSymbol" SG_ 772 MRR_FL_CAN_DET_CONFID_AZIMU_0029 "MRR_FL_CAN_DET_CONFID_AZIMUTH_031";
BA_ "GenSigCmt" SG_ 772 MRR_FL_CAN_DET_RANGE_RATE_031 "Detected object range rate";
BA_ "GenSigStartValue" SG_ 772 MRR_FL_CAN_DET_RANGE_RATE_031 8192;
BA_ "GenSigCmt" SG_ 772 MRR_FL_CAN_SCAN_INDEX_2LSB_031 "The two LSB of scan index";
BA_ "GenSigCmt" SG_ 772 MRR_FL_CAN_DET_AMPLITUDE_031 "Detected object amplitude";
BA_ "GenSigStartValue" SG_ 772 MRR_FL_CAN_DET_AMPLITUDE_031 64;
BA_ "GenSigCmt" SG_ 772 MRR_FL_CAN_DET_VALID_LEVEL_031 "Detected object valid level";
BA_ "GenSigCmt" SG_ 772 MRR_FL_CAN_DET_ELEVATION_030 "Detected object elevation position";
BA_ "GenSigStartValue" SG_ 772 MRR_FL_CAN_DET_ELEVATION_030 63.8646288209607;
BA_ "GenSigCmt" SG_ 772 MRR_FL_CAN_DET_SUPER_RES_TA_0033 "Super resolution target";
BA_ "SystemSignalLongSymbol" SG_ 772 MRR_FL_CAN_DET_SUPER_RES_TA_0033 "MRR_FL_CAN_DET_SUPER_RES_TARGET_030";
BA_ "GenSigCmt" SG_ 772 MRR_FL_CAN_DET_AZIMUTH_030 "Detected object azimuth position";
BA_ "GenSigStartValue" SG_ 772 MRR_FL_CAN_DET_AZIMUTH_030 8194.05320813772;
BA_ "GenSigCmt" SG_ 772 MRR_FL_CAN_DET_CONFID_ELEVA_0033 "Elevation Angle Confidence";
BA_ "SystemSignalLongSymbol" SG_ 772 MRR_FL_CAN_DET_CONFID_ELEVA_0033 "MRR_FL_CAN_DET_CONFID_ELEVATION_030";
BA_ "GenSigCmt" SG_ 772 MRR_FL_CAN_DET_HOST_VEH_CLU_0033 "Host vehicle clutter";
BA_ "SystemSignalLongSymbol" SG_ 772 MRR_FL_CAN_DET_HOST_VEH_CLU_0033 "MRR_FL_CAN_DET_HOST_VEH_CLUTTER_030";
BA_ "GenSigCmt" SG_ 772 MRR_FL_CAN_DET_RANGE_030 "Detected object range";
BA_ "GenSigVtEn" SG_ 772 MRR_FL_CAN_DET_CONFID_AZIMU_0030 "TRUE";
BA_ "GenSigCmt" SG_ 772 MRR_FL_CAN_DET_CONFID_AZIMU_0030 "Signal to noise level";
BA_ "SystemSignalLongSymbol" SG_ 772 MRR_FL_CAN_DET_CONFID_AZIMU_0030 "MRR_FL_CAN_DET_CONFID_AZIMUTH_030";
BA_ "GenSigCmt" SG_ 772 MRR_FL_CAN_DET_RANGE_RATE_030 "Detected object range rate";
BA_ "GenSigStartValue" SG_ 772 MRR_FL_CAN_DET_RANGE_RATE_030 8192;
BA_ "GenSigCmt" SG_ 772 MRR_FL_CAN_SCAN_INDEX_2LSB_030 "The two LSB of scan index";
BA_ "GenSigCmt" SG_ 772 MRR_FL_CAN_DET_AMPLITUDE_030 "Detected object amplitude";
BA_ "GenSigStartValue" SG_ 772 MRR_FL_CAN_DET_AMPLITUDE_030 64;
BA_ "GenSigCmt" SG_ 772 MRR_FL_CAN_DET_VALID_LEVEL_030 "Detected object valid level";
BA_ "SignalDescription" SG_ 773 MRR_FL_CAN_DET_MID_TARGET_042 "MID_Target_Discrimination";
BA_ "GenSigSendType" SG_ 773 MRR_FL_CAN_DET_MID_TARGET_042 1;
BA_ "SignalDescription" SG_ 773 MRR_FL_CAN_DET_MID_TARGET_041 "MID_Target_Discrimination";
BA_ "SignalDescription" SG_ 773 MRR_FL_CAN_DET_MID_TARGET_040 "MID_Target_Discrimination";
BA_ "SignalDescription" SG_ 773 MRR_FL_CAN_DET_MID_TARGET_039 "MID_Target_Discrimination";
BA_ "SignalDescription" SG_ 773 MRR_FL_CAN_DET_MID_TARGET_038 "MID_Target_Discrimination";
BA_ "SignalDescription" SG_ 773 MRR_FL_CAN_DET_MID_TARGET_037 "MID_Target_Discrimination";
BA_ "SignalDescription" SG_ 773 MRR_FL_CAN_DET_MID_TARGET_036 "MID_Target_Discrimination";
BA_ "SignalDescription" SG_ 773 MRR_FL_CAN_DET_Near_TARGET_036 "Near_Target_Discrimination";
BA_ "SignalDescription" SG_ 773 MRR_FL_CAN_DET_Near_TARGET_037 "Near_Target_Discrimination";
BA_ "SignalDescription" SG_ 773 MRR_FL_CAN_DET_Near_TARGET_038 "Near_Target_Discrimination";
BA_ "SignalDescription" SG_ 773 MRR_FL_CAN_DET_Near_TARGET_039 "Near_Target_Discrimination";
BA_ "SignalDescription" SG_ 773 MRR_FL_CAN_DET_Near_TARGET_040 "Near_Target_Discrimination";
BA_ "SignalDescription" SG_ 773 MRR_FL_CAN_DET_Near_TARGET_041 "Near_Target_Discrimination";
BA_ "SignalDescription" SG_ 773 MRR_FL_CAN_DET_Near_TARGET_042 "Near_Target_Discrimination";
BA_ "GenSigCmt" SG_ 773 MRR_FL_CAN_DET_ELEVATION_036 "Detected object elevation position";
BA_ "GenSigStartValue" SG_ 773 MRR_FL_CAN_DET_ELEVATION_036 63.8646288209607;
BA_ "GenSigCmt" SG_ 773 MRR_FL_CAN_DET_CONFID_AZIMU_0031 "Signal to noise level";
BA_ "GenSigVtEn" SG_ 773 MRR_FL_CAN_DET_CONFID_AZIMU_0031 "TRUE";
BA_ "SystemSignalLongSymbol" SG_ 773 MRR_FL_CAN_DET_CONFID_AZIMU_0031 "MRR_FL_CAN_DET_CONFID_AZIMUTH_036";
BA_ "GenSigCmt" SG_ 773 MRR_FL_CAN_DET_SUPER_RES_TA_0034 "Super resolution target";
BA_ "SystemSignalLongSymbol" SG_ 773 MRR_FL_CAN_DET_SUPER_RES_TA_0034 "MRR_FL_CAN_DET_SUPER_RES_TARGET_036";
BA_ "GenSigCmt" SG_ 773 MRR_FL_CAN_DET_CONFID_ELEVA_0034 "Elevation Angle Confidence";
BA_ "SystemSignalLongSymbol" SG_ 773 MRR_FL_CAN_DET_CONFID_ELEVA_0034 "MRR_FL_CAN_DET_CONFID_ELEVATION_036";
BA_ "GenSigCmt" SG_ 773 MRR_FL_CAN_DET_HOST_VEH_CLU_0034 "Host vehicle clutter";
BA_ "SystemSignalLongSymbol" SG_ 773 MRR_FL_CAN_DET_HOST_VEH_CLU_0034 "MRR_FL_CAN_DET_HOST_VEH_CLUTTER_036";
BA_ "GenSigCmt" SG_ 773 MRR_FL_CAN_DET_VALID_LEVEL_036 "Detected object valid level";
BA_ "GenSigCmt" SG_ 773 MRR_FL_CAN_DET_AZIMUTH_036 "Detected object azimuth position";
BA_ "GenSigStartValue" SG_ 773 MRR_FL_CAN_DET_AZIMUTH_036 8194.05320813772;
BA_ "GenSigCmt" SG_ 773 MRR_FL_CAN_DET_RANGE_036 "Detected object range";
BA_ "GenSigCmt" SG_ 773 MRR_FL_CAN_DET_RANGE_RATE_036 "Detected object range rate";
BA_ "GenSigStartValue" SG_ 773 MRR_FL_CAN_DET_RANGE_RATE_036 8192;
BA_ "GenSigCmt" SG_ 773 MRR_FL_CAN_DET_AMPLITUDE_036 "Detected object amplitude";
BA_ "GenSigStartValue" SG_ 773 MRR_FL_CAN_DET_AMPLITUDE_036 64;
BA_ "GenSigCmt" SG_ 773 MRR_FL_CAN_SCAN_INDEX_2LSB_036 "The two LSB of scan index";
BA_ "GenSigStartValue" SG_ 773 MRR_FL_CAN_DET_ELEVATION_042 63.8646288209607;
BA_ "GenSigCmt" SG_ 773 MRR_FL_CAN_DET_ELEVATION_042 "Detected object elevation position";
BA_ "GenSigCmt" SG_ 773 MRR_FL_CAN_DET_SUPER_RES_TA_0035 "Super resolution target";
BA_ "SystemSignalLongSymbol" SG_ 773 MRR_FL_CAN_DET_SUPER_RES_TA_0035 "MRR_FL_CAN_DET_SUPER_RES_TARGET_042";
BA_ "GenSigCmt" SG_ 773 MRR_FL_CAN_DET_AZIMUTH_042 "Detected object azimuth position";
BA_ "GenSigStartValue" SG_ 773 MRR_FL_CAN_DET_AZIMUTH_042 8194.05320813772;
BA_ "GenSigCmt" SG_ 773 MRR_FL_CAN_DET_CONFID_ELEVA_0035 "Elevation Angle Confidence";
BA_ "SystemSignalLongSymbol" SG_ 773 MRR_FL_CAN_DET_CONFID_ELEVA_0035 "MRR_FL_CAN_DET_CONFID_ELEVATION_042";
BA_ "GenSigCmt" SG_ 773 MRR_FL_CAN_DET_HOST_VEH_CLU_0035 "Host vehicle clutter";
BA_ "SystemSignalLongSymbol" SG_ 773 MRR_FL_CAN_DET_HOST_VEH_CLU_0035 "MRR_FL_CAN_DET_HOST_VEH_CLUTTER_042";
BA_ "GenSigCmt" SG_ 773 MRR_FL_CAN_DET_RANGE_042 "Detected object range";
BA_ "GenSigVtEn" SG_ 773 MRR_FL_CAN_DET_CONFID_AZIMUTH_04 "TRUE";
BA_ "GenSigCmt" SG_ 773 MRR_FL_CAN_DET_CONFID_AZIMUTH_04 "Signal to noise level";
BA_ "SystemSignalLongSymbol" SG_ 773 MRR_FL_CAN_DET_CONFID_AZIMUTH_04 "MRR_FL_CAN_DET_CONFID_AZIMUTH_042";
BA_ "GenSigCmt" SG_ 773 MRR_FL_CAN_DET_RANGE_RATE_042 "Detected object range rate";
BA_ "GenSigStartValue" SG_ 773 MRR_FL_CAN_DET_RANGE_RATE_042 8192;
BA_ "GenSigCmt" SG_ 773 MRR_FL_CAN_SCAN_INDEX_2LSB_042 "The two LSB of scan index";
BA_ "GenSigCmt" SG_ 773 MRR_FL_CAN_DET_AMPLITUDE_042 "Detected object amplitude";
BA_ "GenSigStartValue" SG_ 773 MRR_FL_CAN_DET_AMPLITUDE_042 64;
BA_ "GenSigCmt" SG_ 773 MRR_FL_CAN_DET_VALID_LEVEL_042 "Detected object valid level";
BA_ "GenSigCmt" SG_ 773 MRR_FL_CAN_DET_ELEVATION_041 "Detected object elevation position";
BA_ "GenSigStartValue" SG_ 773 MRR_FL_CAN_DET_ELEVATION_041 63.8646288209607;
BA_ "GenSigCmt" SG_ 773 MRR_FL_CAN_DET_SUPER_RES_TA_0036 "Super resolution target";
BA_ "SystemSignalLongSymbol" SG_ 773 MRR_FL_CAN_DET_SUPER_RES_TA_0036 "MRR_FL_CAN_DET_SUPER_RES_TARGET_041";
BA_ "GenSigCmt" SG_ 773 MRR_FL_CAN_DET_AZIMUTH_041 "Detected object azimuth position";
BA_ "GenSigStartValue" SG_ 773 MRR_FL_CAN_DET_AZIMUTH_041 8194.05320813772;
BA_ "GenSigCmt" SG_ 773 MRR_FL_CAN_DET_CONFID_ELEVA_0036 "Elevation Angle Confidence";
BA_ "SystemSignalLongSymbol" SG_ 773 MRR_FL_CAN_DET_CONFID_ELEVA_0036 "MRR_FL_CAN_DET_CONFID_ELEVATION_041";
BA_ "GenSigCmt" SG_ 773 MRR_FL_CAN_DET_HOST_VEH_CLU_0036 "Host vehicle clutter";
BA_ "SystemSignalLongSymbol" SG_ 773 MRR_FL_CAN_DET_HOST_VEH_CLU_0036 "MRR_FL_CAN_DET_HOST_VEH_CLUTTER_041";
BA_ "GenSigCmt" SG_ 773 MRR_FL_CAN_DET_RANGE_041 "Detected object range";
BA_ "GenSigVtEn" SG_ 773 MRR_FL_CAN_DET_CONFID_AZIMU_0032 "TRUE";
BA_ "GenSigCmt" SG_ 773 MRR_FL_CAN_DET_CONFID_AZIMU_0032 "Signal to noise level";
BA_ "SystemSignalLongSymbol" SG_ 773 MRR_FL_CAN_DET_CONFID_AZIMU_0032 "MRR_FL_CAN_DET_CONFID_AZIMUTH_041";
BA_ "GenSigCmt" SG_ 773 MRR_FL_CAN_DET_RANGE_RATE_041 "Detected object range rate";
BA_ "GenSigStartValue" SG_ 773 MRR_FL_CAN_DET_RANGE_RATE_041 8192;
BA_ "GenSigCmt" SG_ 773 MRR_FL_CAN_SCAN_INDEX_2LSB_041 "The two LSB of scan index";
BA_ "GenSigCmt" SG_ 773 MRR_FL_CAN_DET_AMPLITUDE_041 "Detected object amplitude";
BA_ "GenSigStartValue" SG_ 773 MRR_FL_CAN_DET_AMPLITUDE_041 64;
BA_ "GenSigCmt" SG_ 773 MRR_FL_CAN_DET_VALID_LEVEL_041 "Detected object valid level";
BA_ "GenSigCmt" SG_ 773 MRR_FL_CAN_DET_ELEVATION_040 "Detected object elevation position";
BA_ "GenSigStartValue" SG_ 773 MRR_FL_CAN_DET_ELEVATION_040 63.8646288209607;
BA_ "GenSigCmt" SG_ 773 MRR_FL_CAN_DET_SUPER_RES_TA_0037 "Super resolution target";
BA_ "SystemSignalLongSymbol" SG_ 773 MRR_FL_CAN_DET_SUPER_RES_TA_0037 "MRR_FL_CAN_DET_SUPER_RES_TARGET_040";
BA_ "GenSigCmt" SG_ 773 MRR_FL_CAN_DET_AZIMUTH_040 "Detected object azimuth position";
BA_ "GenSigStartValue" SG_ 773 MRR_FL_CAN_DET_AZIMUTH_040 8194.05320813772;
BA_ "GenSigCmt" SG_ 773 MRR_FL_CAN_DET_CONFID_ELEVA_0037 "Elevation Angle Confidence";
BA_ "SystemSignalLongSymbol" SG_ 773 MRR_FL_CAN_DET_CONFID_ELEVA_0037 "MRR_FL_CAN_DET_CONFID_ELEVATION_040";
BA_ "GenSigCmt" SG_ 773 MRR_FL_CAN_DET_HOST_VEH_CLU_0037 "Host vehicle clutter";
BA_ "SystemSignalLongSymbol" SG_ 773 MRR_FL_CAN_DET_HOST_VEH_CLU_0037 "MRR_FL_CAN_DET_HOST_VEH_CLUTTER_040";
BA_ "GenSigCmt" SG_ 773 MRR_FL_CAN_DET_RANGE_040 "Detected object range";
BA_ "GenSigVtEn" SG_ 773 MRR_FL_CAN_DET_CONFID_AZIMU_0033 "TRUE";
BA_ "GenSigCmt" SG_ 773 MRR_FL_CAN_DET_CONFID_AZIMU_0033 "Signal to noise level";
BA_ "SystemSignalLongSymbol" SG_ 773 MRR_FL_CAN_DET_CONFID_AZIMU_0033 "MRR_FL_CAN_DET_CONFID_AZIMUTH_040";
BA_ "GenSigCmt" SG_ 773 MRR_FL_CAN_DET_RANGE_RATE_040 "Detected object range rate";
BA_ "GenSigStartValue" SG_ 773 MRR_FL_CAN_DET_RANGE_RATE_040 8192;
BA_ "GenSigCmt" SG_ 773 MRR_FL_CAN_SCAN_INDEX_2LSB_040 "The two LSB of scan index";
BA_ "GenSigCmt" SG_ 773 MRR_FL_CAN_DET_AMPLITUDE_040 "Detected object amplitude";
BA_ "GenSigStartValue" SG_ 773 MRR_FL_CAN_DET_AMPLITUDE_040 64;
BA_ "GenSigCmt" SG_ 773 MRR_FL_CAN_DET_VALID_LEVEL_040 "Detected object valid level";
BA_ "GenSigCmt" SG_ 773 MRR_FL_CAN_DET_ELEVATION_039 "Detected object elevation position";
BA_ "GenSigStartValue" SG_ 773 MRR_FL_CAN_DET_ELEVATION_039 63.8646288209607;
BA_ "GenSigCmt" SG_ 773 MRR_FL_CAN_DET_SUPER_RES_TA_0038 "Super resolution target";
BA_ "SystemSignalLongSymbol" SG_ 773 MRR_FL_CAN_DET_SUPER_RES_TA_0038 "MRR_FL_CAN_DET_SUPER_RES_TARGET_039";
BA_ "GenSigCmt" SG_ 773 MRR_FL_CAN_DET_AZIMUTH_039 "Detected object azimuth position";
BA_ "GenSigStartValue" SG_ 773 MRR_FL_CAN_DET_AZIMUTH_039 8194.05320813772;
BA_ "GenSigCmt" SG_ 773 MRR_FL_CAN_DET_CONFID_ELEVA_0038 "Elevation Angle Confidence";
BA_ "SystemSignalLongSymbol" SG_ 773 MRR_FL_CAN_DET_CONFID_ELEVA_0038 "MRR_FL_CAN_DET_CONFID_ELEVATION_039";
BA_ "GenSigCmt" SG_ 773 MRR_FL_CAN_DET_HOST_VEH_CLU_0038 "Host vehicle clutter";
BA_ "SystemSignalLongSymbol" SG_ 773 MRR_FL_CAN_DET_HOST_VEH_CLU_0038 "MRR_FL_CAN_DET_HOST_VEH_CLUTTER_039";
BA_ "GenSigCmt" SG_ 773 MRR_FL_CAN_DET_RANGE_039 "Detected object range";
BA_ "GenSigVtEn" SG_ 773 MRR_FL_CAN_DET_CONFID_AZIMU_0034 "TRUE";
BA_ "GenSigCmt" SG_ 773 MRR_FL_CAN_DET_CONFID_AZIMU_0034 "Signal to noise level";
BA_ "SystemSignalLongSymbol" SG_ 773 MRR_FL_CAN_DET_CONFID_AZIMU_0034 "MRR_FL_CAN_DET_CONFID_AZIMUTH_039";
BA_ "GenSigCmt" SG_ 773 MRR_FL_CAN_DET_RANGE_RATE_039 "Detected object range rate";
BA_ "GenSigStartValue" SG_ 773 MRR_FL_CAN_DET_RANGE_RATE_039 8192;
BA_ "GenSigCmt" SG_ 773 MRR_FL_CAN_SCAN_INDEX_2LSB_039 "The two LSB of scan index";
BA_ "GenSigCmt" SG_ 773 MRR_FL_CAN_DET_AMPLITUDE_039 "Detected object amplitude";
BA_ "GenSigStartValue" SG_ 773 MRR_FL_CAN_DET_AMPLITUDE_039 64;
BA_ "GenSigCmt" SG_ 773 MRR_FL_CAN_DET_VALID_LEVEL_039 "Detected object valid level";
BA_ "GenSigCmt" SG_ 773 MRR_FL_CAN_DET_ELEVATION_038 "Detected object elevation position";
BA_ "GenSigStartValue" SG_ 773 MRR_FL_CAN_DET_ELEVATION_038 63.8646288209607;
BA_ "GenSigCmt" SG_ 773 MRR_FL_CAN_DET_SUPER_RES_TA_0039 "Super resolution target";
BA_ "SystemSignalLongSymbol" SG_ 773 MRR_FL_CAN_DET_SUPER_RES_TA_0039 "MRR_FL_CAN_DET_SUPER_RES_TARGET_038";
BA_ "GenSigCmt" SG_ 773 MRR_FL_CAN_DET_AZIMUTH_038 "Detected object azimuth position";
BA_ "GenSigStartValue" SG_ 773 MRR_FL_CAN_DET_AZIMUTH_038 8194.05320813772;
BA_ "GenSigCmt" SG_ 773 MRR_FL_CAN_DET_CONFID_ELEVA_0039 "Elevation Angle Confidence";
BA_ "SystemSignalLongSymbol" SG_ 773 MRR_FL_CAN_DET_CONFID_ELEVA_0039 "MRR_FL_CAN_DET_CONFID_ELEVATION_038";
BA_ "GenSigCmt" SG_ 773 MRR_FL_CAN_DET_HOST_VEH_CLU_0039 "Host vehicle clutter";
BA_ "SystemSignalLongSymbol" SG_ 773 MRR_FL_CAN_DET_HOST_VEH_CLU_0039 "MRR_FL_CAN_DET_HOST_VEH_CLUTTER_038";
BA_ "GenSigCmt" SG_ 773 MRR_FL_CAN_DET_RANGE_038 "Detected object range";
BA_ "GenSigVtEn" SG_ 773 MRR_FL_CAN_DET_CONFID_AZIMU_0035 "TRUE";
BA_ "GenSigCmt" SG_ 773 MRR_FL_CAN_DET_CONFID_AZIMU_0035 "Signal to noise level";
BA_ "SystemSignalLongSymbol" SG_ 773 MRR_FL_CAN_DET_CONFID_AZIMU_0035 "MRR_FL_CAN_DET_CONFID_AZIMUTH_038";
BA_ "GenSigCmt" SG_ 773 MRR_FL_CAN_DET_RANGE_RATE_038 "Detected object range rate";
BA_ "GenSigStartValue" SG_ 773 MRR_FL_CAN_DET_RANGE_RATE_038 8192;
BA_ "GenSigCmt" SG_ 773 MRR_FL_CAN_SCAN_INDEX_2LSB_038 "The two LSB of scan index";
BA_ "GenSigStartValue" SG_ 773 MRR_FL_CAN_DET_AMPLITUDE_038 64;
BA_ "GenSigCmt" SG_ 773 MRR_FL_CAN_DET_AMPLITUDE_038 "Detected object amplitude";
BA_ "GenSigCmt" SG_ 773 MRR_FL_CAN_DET_VALID_LEVEL_038 "Detected object valid level";
BA_ "GenSigCmt" SG_ 773 MRR_FL_CAN_DET_ELEVATION_037 "Detected object elevation position";
BA_ "GenSigStartValue" SG_ 773 MRR_FL_CAN_DET_ELEVATION_037 63.8646288209607;
BA_ "GenSigCmt" SG_ 773 MRR_FL_CAN_DET_SUPER_RES_TA_0040 "Super resolution target";
BA_ "SystemSignalLongSymbol" SG_ 773 MRR_FL_CAN_DET_SUPER_RES_TA_0040 "MRR_FL_CAN_DET_SUPER_RES_TARGET_037";
BA_ "GenSigCmt" SG_ 773 MRR_FL_CAN_DET_AZIMUTH_037 "Detected object azimuth position";
BA_ "GenSigStartValue" SG_ 773 MRR_FL_CAN_DET_AZIMUTH_037 8194.05320813772;
BA_ "GenSigCmt" SG_ 773 MRR_FL_CAN_DET_CONFID_ELEVA_0040 "Elevation Angle Confidence";
BA_ "SystemSignalLongSymbol" SG_ 773 MRR_FL_CAN_DET_CONFID_ELEVA_0040 "MRR_FL_CAN_DET_CONFID_ELEVATION_037";
BA_ "GenSigCmt" SG_ 773 MRR_FL_CAN_DET_HOST_VEH_CLU_0040 "Host vehicle clutter";
BA_ "SystemSignalLongSymbol" SG_ 773 MRR_FL_CAN_DET_HOST_VEH_CLU_0040 "MRR_FL_CAN_DET_HOST_VEH_CLUTTER_037";
BA_ "GenSigCmt" SG_ 773 MRR_FL_CAN_DET_RANGE_037 "Detected object range";
BA_ "GenSigVtEn" SG_ 773 MRR_FL_CAN_DET_CONFID_AZIMU_0036 "TRUE";
BA_ "GenSigCmt" SG_ 773 MRR_FL_CAN_DET_CONFID_AZIMU_0036 "Signal to noise level";
BA_ "SystemSignalLongSymbol" SG_ 773 MRR_FL_CAN_DET_CONFID_AZIMU_0036 "MRR_FL_CAN_DET_CONFID_AZIMUTH_037";
BA_ "GenSigCmt" SG_ 773 MRR_FL_CAN_DET_RANGE_RATE_037 "Detected object range rate";
BA_ "GenSigStartValue" SG_ 773 MRR_FL_CAN_DET_RANGE_RATE_037 8192;
BA_ "GenSigCmt" SG_ 773 MRR_FL_CAN_SCAN_INDEX_2LSB_037 "The two LSB of scan index";
BA_ "GenSigCmt" SG_ 773 MRR_FL_CAN_DET_AMPLITUDE_037 "Detected object amplitude";
BA_ "GenSigStartValue" SG_ 773 MRR_FL_CAN_DET_AMPLITUDE_037 64;
BA_ "GenSigCmt" SG_ 773 MRR_FL_CAN_DET_VALID_LEVEL_037 "Detected object valid level";
BA_ "SignalDescription" SG_ 774 MRR_FL_CAN_DET_MID_TARGET_049 "MID_Target_Discrimination";
BA_ "GenSigSendType" SG_ 774 MRR_FL_CAN_DET_MID_TARGET_049 1;
BA_ "SignalDescription" SG_ 774 MRR_FL_CAN_DET_MID_TARGET_048 "MID_Target_Discrimination";
BA_ "SignalDescription" SG_ 774 MRR_FL_CAN_DET_MID_TARGET_047 "MID_Target_Discrimination";
BA_ "SignalDescription" SG_ 774 MRR_FL_CAN_DET_MID_TARGET_046 "MID_Target_Discrimination";
BA_ "SignalDescription" SG_ 774 MRR_FL_CAN_DET_MID_TARGET_045 "MID_Target_Discrimination";
BA_ "SignalDescription" SG_ 774 MRR_FL_CAN_DET_MID_TARGET_044 "MID_Target_Discrimination";
BA_ "SignalDescription" SG_ 774 MRR_FL_CAN_DET_MID_TARGET_043 "MID_Target_Discrimination";
BA_ "SignalDescription" SG_ 774 MRR_FL_CAN_DET_Near_TARGET_043 "Near_Target_Discrimination";
BA_ "SignalDescription" SG_ 774 MRR_FL_CAN_DET_Near_TARGET_044 "Near_Target_Discrimination";
BA_ "SignalDescription" SG_ 774 MRR_FL_CAN_DET_Near_TARGET_045 "Near_Target_Discrimination";
BA_ "SignalDescription" SG_ 774 MRR_FL_CAN_DET_Near_TARGET_046 "Near_Target_Discrimination";
BA_ "SignalDescription" SG_ 774 MRR_FL_CAN_DET_Near_TARGET_047 "Near_Target_Discrimination";
BA_ "SignalDescription" SG_ 774 MRR_FL_CAN_DET_Near_TARGET_048 "Near_Target_Discrimination";
BA_ "SignalDescription" SG_ 774 MRR_FL_CAN_DET_Near_TARGET_049 "Near_Target_Discrimination";
BA_ "GenSigCmt" SG_ 774 MRR_FL_CAN_DET_ELEVATION_043 "Detected object elevation position";
BA_ "GenSigStartValue" SG_ 774 MRR_FL_CAN_DET_ELEVATION_043 63.8646288209607;
BA_ "GenSigCmt" SG_ 774 MRR_FL_CAN_DET_CONFID_AZIMU_0037 "Signal to noise level";
BA_ "GenSigVtEn" SG_ 774 MRR_FL_CAN_DET_CONFID_AZIMU_0037 "TRUE";
BA_ "SystemSignalLongSymbol" SG_ 774 MRR_FL_CAN_DET_CONFID_AZIMU_0037 "MRR_FL_CAN_DET_CONFID_AZIMUTH_043";
BA_ "GenSigCmt" SG_ 774 MRR_FL_CAN_DET_SUPER_RES_TA_0041 "Super resolution target";
BA_ "SystemSignalLongSymbol" SG_ 774 MRR_FL_CAN_DET_SUPER_RES_TA_0041 "MRR_FL_CAN_DET_SUPER_RES_TARGET_043";
BA_ "GenSigCmt" SG_ 774 MRR_FL_CAN_DET_CONFID_ELEVA_0041 "Elevation Angle Confidence";
BA_ "SystemSignalLongSymbol" SG_ 774 MRR_FL_CAN_DET_CONFID_ELEVA_0041 "MRR_FL_CAN_DET_CONFID_ELEVATION_043";
BA_ "GenSigCmt" SG_ 774 MRR_FL_CAN_DET_HOST_VEH_CLU_0041 "Host vehicle clutter";
BA_ "SystemSignalLongSymbol" SG_ 774 MRR_FL_CAN_DET_HOST_VEH_CLU_0041 "MRR_FL_CAN_DET_HOST_VEH_CLUTTER_043";
BA_ "GenSigCmt" SG_ 774 MRR_FL_CAN_DET_VALID_LEVEL_043 "Detected object valid level";
BA_ "GenSigCmt" SG_ 774 MRR_FL_CAN_DET_AZIMUTH_043 "Detected object azimuth position";
BA_ "GenSigStartValue" SG_ 774 MRR_FL_CAN_DET_AZIMUTH_043 8194.05320813772;
BA_ "GenSigCmt" SG_ 774 MRR_FL_CAN_DET_RANGE_043 "Detected object range";
BA_ "GenSigCmt" SG_ 774 MRR_FL_CAN_DET_RANGE_RATE_043 "Detected object range rate";
BA_ "GenSigStartValue" SG_ 774 MRR_FL_CAN_DET_RANGE_RATE_043 8192;
BA_ "GenSigCmt" SG_ 774 MRR_FL_CAN_DET_AMPLITUDE_043 "Detected object amplitude";
BA_ "GenSigStartValue" SG_ 774 MRR_FL_CAN_DET_AMPLITUDE_043 64;
BA_ "GenSigCmt" SG_ 774 MRR_FL_CAN_SCAN_INDEX_2LSB_043 "The two LSB of scan index";
BA_ "GenSigStartValue" SG_ 774 MRR_FL_CAN_DET_ELEVATION_049 63.8646288209607;
BA_ "GenSigCmt" SG_ 774 MRR_FL_CAN_DET_ELEVATION_049 "Detected object elevation position";
BA_ "GenSigCmt" SG_ 774 MRR_FL_CAN_DET_SUPER_RES_TA_0042 "Super resolution target";
BA_ "SystemSignalLongSymbol" SG_ 774 MRR_FL_CAN_DET_SUPER_RES_TA_0042 "MRR_FL_CAN_DET_SUPER_RES_TARGET_049";
BA_ "GenSigCmt" SG_ 774 MRR_FL_CAN_DET_AZIMUTH_049 "Detected object azimuth position";
BA_ "GenSigStartValue" SG_ 774 MRR_FL_CAN_DET_AZIMUTH_049 8194.05320813772;
BA_ "GenSigCmt" SG_ 774 MRR_FL_CAN_DET_CONFID_ELEVA_0042 "Elevation Angle Confidence";
BA_ "SystemSignalLongSymbol" SG_ 774 MRR_FL_CAN_DET_CONFID_ELEVA_0042 "MRR_FL_CAN_DET_CONFID_ELEVATION_049";
BA_ "GenSigCmt" SG_ 774 MRR_FL_CAN_DET_HOST_VEH_CLU_0042 "Host vehicle clutter";
BA_ "SystemSignalLongSymbol" SG_ 774 MRR_FL_CAN_DET_HOST_VEH_CLU_0042 "MRR_FL_CAN_DET_HOST_VEH_CLUTTER_049";
BA_ "GenSigCmt" SG_ 774 MRR_FL_CAN_DET_RANGE_049 "Detected object range";
BA_ "GenSigVtEn" SG_ 774 MRR_FL_CAN_DET_CONFID_AZIMU_0038 "TRUE";
BA_ "GenSigCmt" SG_ 774 MRR_FL_CAN_DET_CONFID_AZIMU_0038 "Signal to noise level";
BA_ "SystemSignalLongSymbol" SG_ 774 MRR_FL_CAN_DET_CONFID_AZIMU_0038 "MRR_FL_CAN_DET_CONFID_AZIMUTH_049";
BA_ "GenSigCmt" SG_ 774 MRR_FL_CAN_DET_RANGE_RATE_049 "Detected object range rate";
BA_ "GenSigStartValue" SG_ 774 MRR_FL_CAN_DET_RANGE_RATE_049 8192;
BA_ "GenSigCmt" SG_ 774 MRR_FL_CAN_SCAN_INDEX_2LSB_049 "The two LSB of scan index";
BA_ "GenSigCmt" SG_ 774 MRR_FL_CAN_DET_AMPLITUDE_049 "Detected object amplitude";
BA_ "GenSigStartValue" SG_ 774 MRR_FL_CAN_DET_AMPLITUDE_049 64;
BA_ "GenSigCmt" SG_ 774 MRR_FL_CAN_DET_VALID_LEVEL_049 "Detected object valid level";
BA_ "GenSigCmt" SG_ 774 MRR_FL_CAN_DET_ELEVATION_048 "Detected object elevation position";
BA_ "GenSigStartValue" SG_ 774 MRR_FL_CAN_DET_ELEVATION_048 63.8646288209607;
BA_ "GenSigCmt" SG_ 774 MRR_FL_CAN_DET_SUPER_RES_TA_0043 "Super resolution target";
BA_ "SystemSignalLongSymbol" SG_ 774 MRR_FL_CAN_DET_SUPER_RES_TA_0043 "MRR_FL_CAN_DET_SUPER_RES_TARGET_048";
BA_ "GenSigCmt" SG_ 774 MRR_FL_CAN_DET_AZIMUTH_048 "Detected object azimuth position";
BA_ "GenSigStartValue" SG_ 774 MRR_FL_CAN_DET_AZIMUTH_048 8194.05320813772;
BA_ "GenSigCmt" SG_ 774 MRR_FL_CAN_DET_CONFID_ELEVA_0043 "Elevation Angle Confidence";
BA_ "SystemSignalLongSymbol" SG_ 774 MRR_FL_CAN_DET_CONFID_ELEVA_0043 "MRR_FL_CAN_DET_CONFID_ELEVATION_048";
BA_ "GenSigCmt" SG_ 774 MRR_FL_CAN_DET_HOST_VEH_CLU_0043 "Host vehicle clutter";
BA_ "SystemSignalLongSymbol" SG_ 774 MRR_FL_CAN_DET_HOST_VEH_CLU_0043 "MRR_FL_CAN_DET_HOST_VEH_CLUTTER_048";
BA_ "GenSigCmt" SG_ 774 MRR_FL_CAN_DET_RANGE_048 "Detected object range";
BA_ "GenSigVtEn" SG_ 774 MRR_FL_CAN_DET_CONFID_AZIMU_0039 "TRUE";
BA_ "GenSigCmt" SG_ 774 MRR_FL_CAN_DET_CONFID_AZIMU_0039 "Signal to noise level";
BA_ "SystemSignalLongSymbol" SG_ 774 MRR_FL_CAN_DET_CONFID_AZIMU_0039 "MRR_FL_CAN_DET_CONFID_AZIMUTH_048";
BA_ "GenSigCmt" SG_ 774 MRR_FL_CAN_DET_RANGE_RATE_048 "Detected object range rate";
BA_ "GenSigStartValue" SG_ 774 MRR_FL_CAN_DET_RANGE_RATE_048 8192;
BA_ "GenSigCmt" SG_ 774 MRR_FL_CAN_SCAN_INDEX_2LSB_048 "The two LSB of scan index";
BA_ "GenSigCmt" SG_ 774 MRR_FL_CAN_DET_AMPLITUDE_048 "Detected object amplitude";
BA_ "GenSigStartValue" SG_ 774 MRR_FL_CAN_DET_AMPLITUDE_048 64;
BA_ "GenSigCmt" SG_ 774 MRR_FL_CAN_DET_VALID_LEVEL_048 "Detected object valid level";
BA_ "GenSigCmt" SG_ 774 MRR_FL_CAN_DET_ELEVATION_047 "Detected object elevation position";
BA_ "GenSigStartValue" SG_ 774 MRR_FL_CAN_DET_ELEVATION_047 63.8646288209607;
BA_ "GenSigCmt" SG_ 774 MRR_FL_CAN_DET_SUPER_RES_TA_0044 "Super resolution target";
BA_ "SystemSignalLongSymbol" SG_ 774 MRR_FL_CAN_DET_SUPER_RES_TA_0044 "MRR_FL_CAN_DET_SUPER_RES_TARGET_047";
BA_ "GenSigCmt" SG_ 774 MRR_FL_CAN_DET_AZIMUTH_047 "Detected object azimuth position";
BA_ "GenSigStartValue" SG_ 774 MRR_FL_CAN_DET_AZIMUTH_047 8194.05320813772;
BA_ "GenSigCmt" SG_ 774 MRR_FL_CAN_DET_CONFID_ELEVA_0044 "Elevation Angle Confidence";
BA_ "SystemSignalLongSymbol" SG_ 774 MRR_FL_CAN_DET_CONFID_ELEVA_0044 "MRR_FL_CAN_DET_CONFID_ELEVATION_047";
BA_ "GenSigCmt" SG_ 774 MRR_FL_CAN_DET_HOST_VEH_CLU_0044 "Host vehicle clutter";
BA_ "SystemSignalLongSymbol" SG_ 774 MRR_FL_CAN_DET_HOST_VEH_CLU_0044 "MRR_FL_CAN_DET_HOST_VEH_CLUTTER_047";
BA_ "GenSigCmt" SG_ 774 MRR_FL_CAN_DET_RANGE_047 "Detected object range";
BA_ "GenSigVtEn" SG_ 774 MRR_FL_CAN_DET_CONFID_AZIMU_0040 "TRUE";
BA_ "GenSigCmt" SG_ 774 MRR_FL_CAN_DET_CONFID_AZIMU_0040 "Signal to noise level";
BA_ "SystemSignalLongSymbol" SG_ 774 MRR_FL_CAN_DET_CONFID_AZIMU_0040 "MRR_FL_CAN_DET_CONFID_AZIMUTH_047";
BA_ "GenSigCmt" SG_ 774 MRR_FL_CAN_DET_RANGE_RATE_047 "Detected object range rate";
BA_ "GenSigStartValue" SG_ 774 MRR_FL_CAN_DET_RANGE_RATE_047 8192;
BA_ "GenSigCmt" SG_ 774 MRR_FL_CAN_SCAN_INDEX_2LSB_047 "The two LSB of scan index";
BA_ "GenSigCmt" SG_ 774 MRR_FL_CAN_DET_AMPLITUDE_047 "Detected object amplitude";
BA_ "GenSigStartValue" SG_ 774 MRR_FL_CAN_DET_AMPLITUDE_047 64;
BA_ "GenSigCmt" SG_ 774 MRR_FL_CAN_DET_VALID_LEVEL_047 "Detected object valid level";
BA_ "GenSigCmt" SG_ 774 MRR_FL_CAN_DET_ELEVATION_046 "Detected object elevation position";
BA_ "GenSigStartValue" SG_ 774 MRR_FL_CAN_DET_ELEVATION_046 63.8646288209607;
BA_ "GenSigCmt" SG_ 774 MRR_FL_CAN_DET_SUPER_RES_TA_0045 "Super resolution target";
BA_ "SystemSignalLongSymbol" SG_ 774 MRR_FL_CAN_DET_SUPER_RES_TA_0045 "MRR_FL_CAN_DET_SUPER_RES_TARGET_046";
BA_ "GenSigCmt" SG_ 774 MRR_FL_CAN_DET_AZIMUTH_046 "Detected object azimuth position";
BA_ "GenSigStartValue" SG_ 774 MRR_FL_CAN_DET_AZIMUTH_046 8194.05320813772;
BA_ "GenSigCmt" SG_ 774 MRR_FL_CAN_DET_CONFID_ELEVA_0045 "Elevation Angle Confidence";
BA_ "SystemSignalLongSymbol" SG_ 774 MRR_FL_CAN_DET_CONFID_ELEVA_0045 "MRR_FL_CAN_DET_CONFID_ELEVATION_046";
BA_ "GenSigCmt" SG_ 774 MRR_FL_CAN_DET_HOST_VEH_CLU_0045 "Host vehicle clutter";
BA_ "SystemSignalLongSymbol" SG_ 774 MRR_FL_CAN_DET_HOST_VEH_CLU_0045 "MRR_FL_CAN_DET_HOST_VEH_CLUTTER_046";
BA_ "GenSigCmt" SG_ 774 MRR_FL_CAN_DET_RANGE_046 "Detected object range";
BA_ "GenSigVtEn" SG_ 774 MRR_FL_CAN_DET_CONFID_AZIMU_0041 "TRUE";
BA_ "GenSigCmt" SG_ 774 MRR_FL_CAN_DET_CONFID_AZIMU_0041 "Signal to noise level";
BA_ "SystemSignalLongSymbol" SG_ 774 MRR_FL_CAN_DET_CONFID_AZIMU_0041 "MRR_FL_CAN_DET_CONFID_AZIMUTH_046";
BA_ "GenSigCmt" SG_ 774 MRR_FL_CAN_DET_RANGE_RATE_046 "Detected object range rate";
BA_ "GenSigStartValue" SG_ 774 MRR_FL_CAN_DET_RANGE_RATE_046 8192;
BA_ "GenSigCmt" SG_ 774 MRR_FL_CAN_SCAN_INDEX_2LSB_046 "The two LSB of scan index";
BA_ "GenSigCmt" SG_ 774 MRR_FL_CAN_DET_AMPLITUDE_046 "Detected object amplitude";
BA_ "GenSigStartValue" SG_ 774 MRR_FL_CAN_DET_AMPLITUDE_046 64;
BA_ "GenSigCmt" SG_ 774 MRR_FL_CAN_DET_VALID_LEVEL_046 "Detected object valid level";
BA_ "GenSigCmt" SG_ 774 MRR_FL_CAN_DET_ELEVATION_045 "Detected object elevation position";
BA_ "GenSigStartValue" SG_ 774 MRR_FL_CAN_DET_ELEVATION_045 63.8646288209607;
BA_ "GenSigCmt" SG_ 774 MRR_FL_CAN_DET_SUPER_RES_TA_0046 "Super resolution target";
BA_ "SystemSignalLongSymbol" SG_ 774 MRR_FL_CAN_DET_SUPER_RES_TA_0046 "MRR_FL_CAN_DET_SUPER_RES_TARGET_045";
BA_ "GenSigCmt" SG_ 774 MRR_FL_CAN_DET_AZIMUTH_045 "Detected object azimuth position";
BA_ "GenSigStartValue" SG_ 774 MRR_FL_CAN_DET_AZIMUTH_045 8194.05320813772;
BA_ "GenSigCmt" SG_ 774 MRR_FL_CAN_DET_CONFID_ELEVA_0046 "Elevation Angle Confidence";
BA_ "SystemSignalLongSymbol" SG_ 774 MRR_FL_CAN_DET_CONFID_ELEVA_0046 "MRR_FL_CAN_DET_CONFID_ELEVATION_045";
BA_ "GenSigCmt" SG_ 774 MRR_FL_CAN_DET_HOST_VEH_CLU_0046 "Host vehicle clutter";
BA_ "SystemSignalLongSymbol" SG_ 774 MRR_FL_CAN_DET_HOST_VEH_CLU_0046 "MRR_FL_CAN_DET_HOST_VEH_CLUTTER_045";
BA_ "GenSigCmt" SG_ 774 MRR_FL_CAN_DET_RANGE_045 "Detected object range";
BA_ "GenSigVtEn" SG_ 774 MRR_FL_CAN_DET_CONFID_AZIMU_0042 "TRUE";
BA_ "GenSigCmt" SG_ 774 MRR_FL_CAN_DET_CONFID_AZIMU_0042 "Signal to noise level";
BA_ "SystemSignalLongSymbol" SG_ 774 MRR_FL_CAN_DET_CONFID_AZIMU_0042 "MRR_FL_CAN_DET_CONFID_AZIMUTH_045";
BA_ "GenSigCmt" SG_ 774 MRR_FL_CAN_DET_RANGE_RATE_045 "Detected object range rate";
BA_ "GenSigStartValue" SG_ 774 MRR_FL_CAN_DET_RANGE_RATE_045 8192;
BA_ "GenSigCmt" SG_ 774 MRR_FL_CAN_SCAN_INDEX_2LSB_045 "The two LSB of scan index";
BA_ "GenSigCmt" SG_ 774 MRR_FL_CAN_DET_AMPLITUDE_045 "Detected object amplitude";
BA_ "GenSigStartValue" SG_ 774 MRR_FL_CAN_DET_AMPLITUDE_045 64;
BA_ "GenSigCmt" SG_ 774 MRR_FL_CAN_DET_VALID_LEVEL_045 "Detected object valid level";
BA_ "GenSigCmt" SG_ 774 MRR_FL_CAN_DET_ELEVATION_044 "Detected object elevation position";
BA_ "GenSigStartValue" SG_ 774 MRR_FL_CAN_DET_ELEVATION_044 63.8646288209607;
BA_ "GenSigCmt" SG_ 774 MRR_FL_CAN_DET_SUPER_RES_TA_0047 "Super resolution target";
BA_ "SystemSignalLongSymbol" SG_ 774 MRR_FL_CAN_DET_SUPER_RES_TA_0047 "MRR_FL_CAN_DET_SUPER_RES_TARGET_044";
BA_ "GenSigCmt" SG_ 774 MRR_FL_CAN_DET_AZIMUTH_044 "Detected object azimuth position";
BA_ "GenSigStartValue" SG_ 774 MRR_FL_CAN_DET_AZIMUTH_044 8194.05320813772;
BA_ "GenSigCmt" SG_ 774 MRR_FL_CAN_DET_CONFID_ELEVA_0047 "Elevation Angle Confidence";
BA_ "SystemSignalLongSymbol" SG_ 774 MRR_FL_CAN_DET_CONFID_ELEVA_0047 "MRR_FL_CAN_DET_CONFID_ELEVATION_044";
BA_ "GenSigCmt" SG_ 774 MRR_FL_CAN_DET_HOST_VEH_CLU_0047 "Host vehicle clutter";
BA_ "SystemSignalLongSymbol" SG_ 774 MRR_FL_CAN_DET_HOST_VEH_CLU_0047 "MRR_FL_CAN_DET_HOST_VEH_CLUTTER_044";
BA_ "GenSigCmt" SG_ 774 MRR_FL_CAN_DET_RANGE_044 "Detected object range";
BA_ "GenSigVtEn" SG_ 774 MRR_FL_CAN_DET_CONFID_AZIMU_0043 "TRUE";
BA_ "GenSigCmt" SG_ 774 MRR_FL_CAN_DET_CONFID_AZIMU_0043 "Signal to noise level";
BA_ "SystemSignalLongSymbol" SG_ 774 MRR_FL_CAN_DET_CONFID_AZIMU_0043 "MRR_FL_CAN_DET_CONFID_AZIMUTH_044";
BA_ "GenSigCmt" SG_ 774 MRR_FL_CAN_DET_RANGE_RATE_044 "Detected object range rate";
BA_ "GenSigStartValue" SG_ 774 MRR_FL_CAN_DET_RANGE_RATE_044 8192;
BA_ "GenSigCmt" SG_ 774 MRR_FL_CAN_SCAN_INDEX_2LSB_044 "The two LSB of scan index";
BA_ "GenSigCmt" SG_ 774 MRR_FL_CAN_DET_AMPLITUDE_044 "Detected object amplitude";
BA_ "GenSigStartValue" SG_ 774 MRR_FL_CAN_DET_AMPLITUDE_044 64;
BA_ "GenSigCmt" SG_ 774 MRR_FL_CAN_DET_VALID_LEVEL_044 "Detected object valid level";
VAL_ 456 MRR_CAN_RadarWaveform_FR 4 "Unused" 3 "AutoHitch" 2 "Standard_Rear" 1 "Standard_Front" 0 "Unknown" ;
VAL_ 398 MRR_FL_System_Operation_Mode_Sta 2 "RADIATE_ON" 1 "RADIATE_OFF" 0 "INIT" ;
VAL_ 398 RadarSensorNotOperational_MRRFL 1 "TRUE" 0 "FALSE" ;
VAL_ 398 RadarAlignmentOutOfRange_MRRFL 1 "Radar out of range" 0 "Radar within range" ;
VAL_ 398 RadarBlockageDetected_MRRFL 1 "Radar Blockage" 0 "No Radar Blockage" ;
VAL_ 398 RadarExternalConditionsNotOK_MRR 1 "Too high temp or insufficient pw" 0 "External conditions OK" ;
VAL_ 398 RadarAlignmentIncomplete_MRRFL 1 "Alignment Incomplete" 0 "Alignment Completed" ;
VAL_ 398 RadarAlignmentNotStarted_MRRFL 1 "Radar align not started" 0 "Radar align started" ;
VAL_ 462 MRR_FR_System_Operation_Mode_Sta 2 "RADIATE_ON" 1 "RADIATE_OFF" 0 "INIT" ;
VAL_ 462 RadarSensorNotOperational_MRRFR 1 "TRUE" 0 "FALSE" ;
VAL_ 462 RadarAlignmentOutOfRange_MRRFR 1 "Radar out of range" 0 "Radar within range" ;
VAL_ 462 RadarBlockageDetected_MRRFR 1 "Radar Blockage" 0 "No Radar Blockage" ;
VAL_ 462 RadarExternalConditionsNotO_0000 1 "Too high temp or insufficient pw" 0 "External conditions OK" ;
VAL_ 462 RadarAlignmentIncomplete_MRRFR 1 "Alignment Incomplete" 0 "Alignment Completed" ;
VAL_ 462 RadarAlignmentNotStarted_MRRFR 1 "Radar align not started" 0 "Radar align started" ;
VAL_ 769 MRR_FL_CAN_DET_CONFID_AZIMU_0006 3 "Low" 2 "MidLow" 1 "MidHigh" 0 "High" ;
VAL_ 769 MRR_FL_CAN_DET_CONFID_AZIMUTH_01 3 "Low" 2 "MidLow" 1 "MidHigh" 0 "High" ;
VAL_ 769 MRR_FL_CAN_DET_CONFID_AZIMU_0007 3 "Low" 2 "MidLow" 1 "MidHigh" 0 "High" ;
VAL_ 769 MRR_FL_CAN_DET_CONFID_AZIMU_0008 3 "Low" 2 "MidLow" 1 "MidHigh" 0 "High" ;
VAL_ 769 MRR_FL_CAN_DET_CONFID_AZIMU_0009 3 "Low" 2 "MidLow" 1 "MidHigh" 0 "High" ;
VAL_ 769 MRR_FL_CAN_DET_CONFID_AZIMU_0010 3 "Low" 2 "MidLow" 1 "MidHigh" 0 "High" ;
VAL_ 769 MRR_FL_CAN_DET_CONFID_AZIMU_0011 3 "Low" 2 "MidLow" 1 "MidHigh" 0 "High" ;
VAL_ 770 MRR_FL_CAN_DET_CONFID_AZIMU_0012 3 "Low" 2 "MidLow" 1 "MidHigh" 0 "High" ;
VAL_ 770 MRR_FL_CAN_DET_CONFID_AZIMUTH_02 3 "Low" 2 "MidLow" 1 "MidHigh" 0 "High" ;
VAL_ 770 MRR_FL_CAN_DET_CONFID_AZIMU_0013 3 "Low" 2 "MidLow" 1 "MidHigh" 0 "High" ;
VAL_ 770 MRR_FL_CAN_DET_CONFID_AZIMU_0014 3 "Low" 2 "MidLow" 1 "MidHigh" 0 "High" ;
VAL_ 770 MRR_FL_CAN_DET_CONFID_AZIMU_0015 3 "Low" 2 "MidLow" 1 "MidHigh" 0 "High" ;
VAL_ 770 MRR_FL_CAN_DET_CONFID_AZIMU_0016 3 "Low" 2 "MidLow" 1 "MidHigh" 0 "High" ;
VAL_ 770 MRR_FL_CAN_DET_CONFID_AZIMU_0017 3 "Low" 2 "MidLow" 1 "MidHigh" 0 "High" ;
VAL_ 771 MRR_FL_CAN_DET_CONFID_AZIMU_0018 3 "Low" 2 "MidLow" 1 "MidHigh" 0 "High" ;
VAL_ 771 MRR_FL_CAN_DET_CONFID_AZIMU_0019 3 "Low" 2 "MidLow" 1 "MidHigh" 0 "High" ;
VAL_ 771 MRR_FL_CAN_DET_CONFID_AZIMU_0020 3 "Low" 2 "MidLow" 1 "MidHigh" 0 "High" ;
VAL_ 771 MRR_FL_CAN_DET_CONFID_AZIMU_0021 3 "Low" 2 "MidLow" 1 "MidHigh" 0 "High" ;
VAL_ 771 MRR_FL_CAN_DET_CONFID_AZIMU_0022 3 "Low" 2 "MidLow" 1 "MidHigh" 0 "High" ;
VAL_ 771 MRR_FL_CAN_DET_CONFID_AZIMU_0023 3 "Low" 2 "MidLow" 1 "MidHigh" 0 "High" ;
VAL_ 771 MRR_FL_CAN_DET_CONFID_AZIMU_0024 3 "Low" 2 "MidLow" 1 "MidHigh" 0 "High" ;
VAL_ 772 MRR_FL_CAN_DET_CONFID_AZIMU_0025 3 "Low" 2 "MidLow" 1 "MidHigh" 0 "High" ;
VAL_ 772 MRR_FL_CAN_DET_CONFID_AZIMUTH_03 3 "Low" 2 "MidLow" 1 "MidHigh" 0 "High" ;
VAL_ 772 MRR_FL_CAN_DET_CONFID_AZIMU_0026 3 "Low" 2 "MidLow" 1 "MidHigh" 0 "High" ;
VAL_ 772 MRR_FL_CAN_DET_CONFID_AZIMU_0027 3 "Low" 2 "MidLow" 1 "MidHigh" 0 "High" ;
VAL_ 772 MRR_FL_CAN_DET_CONFID_AZIMU_0028 3 "Low" 2 "MidLow" 1 "MidHigh" 0 "High" ;
VAL_ 772 MRR_FL_CAN_DET_CONFID_AZIMU_0029 3 "Low" 2 "MidLow" 1 "MidHigh" 0 "High" ;
VAL_ 772 MRR_FL_CAN_DET_CONFID_AZIMU_0030 3 "Low" 2 "MidLow" 1 "MidHigh" 0 "High" ;
VAL_ 773 MRR_FL_CAN_DET_CONFID_AZIMU_0031 3 "Low" 2 "MidLow" 1 "MidHigh" 0 "High" ;
VAL_ 773 MRR_FL_CAN_DET_CONFID_AZIMUTH_04 3 "Low" 2 "MidLow" 1 "MidHigh" 0 "High" ;
VAL_ 773 MRR_FL_CAN_DET_CONFID_AZIMU_0032 3 "Low" 2 "MidLow" 1 "MidHigh" 0 "High" ;
VAL_ 773 MRR_FL_CAN_DET_CONFID_AZIMU_0033 3 "Low" 2 "MidLow" 1 "MidHigh" 0 "High" ;
VAL_ 773 MRR_FL_CAN_DET_CONFID_AZIMU_0034 3 "Low" 2 "MidLow" 1 "MidHigh" 0 "High" ;
VAL_ 773 MRR_FL_CAN_DET_CONFID_AZIMU_0035 3 "Low" 2 "MidLow" 1 "MidHigh" 0 "High" ;
VAL_ 773 MRR_FL_CAN_DET_CONFID_AZIMU_0036 3 "Low" 2 "MidLow" 1 "MidHigh" 0 "High" ;
VAL_ 774 MRR_FL_CAN_DET_CONFID_AZIMU_0037 3 "Low" 2 "MidLow" 1 "MidHigh" 0 "High" ;
VAL_ 774 MRR_FL_CAN_DET_CONFID_AZIMU_0038 3 "Low" 2 "MidLow" 1 "MidHigh" 0 "High" ;
VAL_ 774 MRR_FL_CAN_DET_CONFID_AZIMU_0039 3 "Low" 2 "MidLow" 1 "MidHigh" 0 "High" ;
VAL_ 774 MRR_FL_CAN_DET_CONFID_AZIMU_0040 3 "Low" 2 "MidLow" 1 "MidHigh" 0 "High" ;
VAL_ 774 MRR_FL_CAN_DET_CONFID_AZIMU_0041 3 "Low" 2 "MidLow" 1 "MidHigh" 0 "High" ;
VAL_ 774 MRR_FL_CAN_DET_CONFID_AZIMU_0042 3 "Low" 2 "MidLow" 1 "MidHigh" 0 "High" ;
VAL_ 774 MRR_FL_CAN_DET_CONFID_AZIMU_0043 3 "Low" 2 "MidLow" 1 "MidHigh" 0 "High" ;
SIG_GROUP_ 456 MRR_FR_Header_SensorCoverage 1 : MRR_FR_Radar_Spec_Status_MC MRR_FR_Radar_Spec_Status_CRC MRR_CAN_RadarWaveform_FR MRR_FR_CAN_RANGE_COVERAGE MRR_FR_CAN_DOPPLER_COVERAGE MRR_FR_CAN_FOV_HOR MRR_FR_CAN_FOV_VER;
SIG_GROUP_ 398 MRR_FL_Status_Radar 1 : MRR_FL_System_Operation_Mode_Sta MRR_FL_Status_Radar_CRC MRR_FL_Status_Radar_MC CAN_Core2_Cpu_Load_MRRFL CAN_Core1_Cpu_Load_MRRFL CAN_Core0_Cpu_Load_MRRFL RadarSensorNotOperational_MRRFL RadarAlignmentOutOfRange_MRRFL RadarBlockageDetected_MRRFL RadarExternalConditionsNotOK_MRR RadarAlignmentIncomplete_MRRFL RadarAlignmentNotStarted_MRRFL;
SIG_GROUP_ 462 MRR_FR_Status_Radar 1 : MRR_FR_System_Operation_Mode_Sta MRR_FR_Status_Radar_CRC MRR_FR_Status_Radar_MC CAN_Core2_Cpu_Load_MRRFR CAN_Core1_Cpu_Load_MRRFR CAN_Core0_Cpu_Load_MRRFR RadarSensorNotOperational_MRRFR RadarAlignmentOutOfRange_MRRFR RadarBlockageDetected_MRRFR RadarExternalConditionsNotO_0000 RadarAlignmentIncomplete_MRRFR RadarAlignmentNotStarted_MRRFR;
SIG_GROUP_ 769 MRR_FL_Detection_008_014 1 : MRR_FL_CAN_DET_Near_TARGET_014 MRR_FL_CAN_DET_Near_TARGET_013 MRR_FL_CAN_DET_Near_TARGET_012 MRR_FL_CAN_DET_Near_TARGET_011 MRR_FL_CAN_DET_Near_TARGET_010 MRR_FL_CAN_DET_Near_TARGET_009 MRR_FL_CAN_DET_Near_TARGET_008 MRR_FL_CAN_DET_MID_TARGET_008 MRR_FL_CAN_DET_MID_TARGET_009 MRR_FL_CAN_DET_MID_TARGET_010 MRR_FL_CAN_DET_MID_TARGET_011 MRR_FL_CAN_DET_MID_TARGET_012 MRR_FL_CAN_DET_MID_TARGET_013 MRR_FL_CAN_DET_MID_TARGET_014 MRR_FL_CAN_DET_ELEVATION_008 MRR_FL_CAN_DET_CONFID_AZIMU_0006 MRR_FL_CAN_DET_SUPER_RES_TA_0006 MRR_FL_CAN_DET_VALID_LEVEL_008 MRR_FL_CAN_DET_RANGE_009 MRR_FL_CAN_SCAN_INDEX_2LSB_009 MRR_FL_CAN_DET_CONFID_ELEVA_0006 MRR_FL_CAN_DET_RANGE_RATE_009 MRR_FL_CAN_DET_AZIMUTH_008 MRR_FL_DET_MC_002 MRR_FL_CAN_DET_RANGE_008 MRR_FL_CAN_DET_CONFID_ELEVA_0012 MRR_FL_CAN_DET_AMPLITUDE_009 MRR_FL_CAN_DET_AMPLITUDE_013 MRR_FL_CAN_DET_CONFID_AZIMU_0010 MRR_FL_DET_CRC_002 MRR_FL_CAN_DET_SUPER_RES_TA_0012 MRR_FL_CAN_DET_CONFID_AZIMU_0011 MRR_FL_CAN_DET_CONFID_ELEVA_0009 MRR_FL_CAN_DET_HOST_VEH_CLU_0011 MRR_FL_CAN_DET_RANGE_010 MRR_FL_CAN_DET_ELEVATION_011 MRR_FL_CAN_DET_AMPLITUDE_011 MRR_FL_CAN_DET_VALID_LEVEL_010 MRR_FL_CAN_SCAN_INDEX_2LSB_011 MRR_FL_CAN_DET_CONFID_AZIMU_0009 MRR_FL_CAN_DET_AMPLITUDE_012 MRR_FL_CAN_SCAN_INDEX_2LSB_010 MRR_FL_CAN_DET_AZIMUTH_011 MRR_FL_CAN_DET_RANGE_011 MRR_FL_CAN_DET_ELEVATION_010 MRR_FL_CAN_DET_AZIMUTH_010 MRR_FL_CAN_DET_SUPER_RES_TA_0009 MRR_FL_CAN_DET_RANGE_RATE_013 MRR_FL_CAN_DET_HOST_VEH_CLU_0006 MRR_FL_CAN_DET_AZIMUTH_012 MRR_FL_CAN_DET_VALID_LEVEL_012 MRR_FL_CAN_DET_RANGE_012 MRR_FL_CAN_DET_RANGE_RATE_008 MRR_FL_CAN_DET_AMPLITUDE_008 MRR_FL_CAN_SCAN_INDEX_2LSB_008 MRR_FL_CAN_SCAN_INDEX_2LSB_012 MRR_FL_CAN_DET_ELEVATION_012 MRR_FL_CAN_SCAN_INDEX_2LSB_013 MRR_FL_CAN_DET_RANGE_RATE_012 MRR_FL_CAN_DET_CONFID_AZIMU_0008 MRR_FL_CAN_DET_HOST_VEH_CLU_0009 MRR_FL_CAN_DET_VALID_LEVEL_013 MRR_FL_CAN_DET_AZIMUTH_009 MRR_FL_CAN_DET_RANGE_RATE_011 MRR_FL_CAN_DET_SUPER_RES_TA_0010 MRR_FL_CAN_DET_VALID_LEVEL_011 MRR_FL_CAN_DET_SUPER_RES_TA_0011 MRR_FL_CAN_DET_RANGE_RATE_014 MRR_FL_CAN_DET_ELEVATION_009 MRR_FL_CAN_DET_CONFID_ELEVA_0010 MRR_FL_CAN_DET_AZIMUTH_014 MRR_FL_CAN_DET_ELEVATION_014 MRR_FL_CAN_DET_SUPER_RES_TA_0007 MRR_FL_CAN_DET_CONFID_ELEVA_0011 MRR_FL_CAN_DET_CONFID_AZIMU_0007 MRR_FL_CAN_DET_RANGE_RATE_010 MRR_FL_CAN_DET_HOST_VEH_CLU_0010 MRR_FL_CAN_DET_CONFID_AZIMUTH_01 MRR_FL_CAN_DET_RANGE_014 MRR_FL_CAN_DET_CONFID_ELEVA_0007 MRR_FL_CAN_DET_AMPLITUDE_010 MRR_FL_CAN_DET_RANGE_013 MRR_FL_CAN_DET_AMPLITUDE_014 MRR_FL_CAN_DET_ELEVATION_013 MRR_FL_CAN_DET_HOST_VEH_CLU_0012 MRR_FL_CAN_DET_HOST_VEH_CLU_0008 MRR_FL_CAN_DET_CONFID_ELEVA_0008 MRR_FL_CAN_SCAN_INDEX_2LSB_014 MRR_FL_CAN_DET_HOST_VEH_CLU_0007 MRR_FL_CAN_DET_VALID_LEVEL_014 MRR_FL_CAN_DET_SUPER_RES_TA_0008 MRR_FL_CAN_DET_AZIMUTH_013 MRR_FL_CAN_DET_VALID_LEVEL_009;
SIG_GROUP_ 770 MRR_FL_Detection_015_021 1 : MRR_FL_CAN_DET_Near_TARGET_021 MRR_FL_CAN_DET_Near_TARGET_020 MRR_FL_CAN_DET_Near_TARGET_019 MRR_FL_CAN_DET_Near_TARGET_018 MRR_FL_CAN_DET_Near_TARGET_017 MRR_FL_CAN_DET_Near_TARGET_016 MRR_FL_CAN_DET_Near_TARGET_015 MRR_FL_CAN_DET_MID_TARGET_015 MRR_FL_CAN_DET_MID_TARGET_016 MRR_FL_CAN_DET_MID_TARGET_017 MRR_FL_CAN_DET_MID_TARGET_018 MRR_FL_CAN_DET_MID_TARGET_019 MRR_FL_CAN_DET_MID_TARGET_020 MRR_FL_CAN_DET_MID_TARGET_021 MRR_FL_CAN_DET_ELEVATION_015 MRR_FL_CAN_DET_CONFID_AZIMU_0012 MRR_FL_CAN_DET_SUPER_RES_TA_0013 MRR_FL_CAN_DET_CONFID_ELEVA_0013 MRR_FL_CAN_DET_HOST_VEH_CLU_0013 MRR_FL_CAN_DET_VALID_LEVEL_015 MRR_FL_CAN_DET_RANGE_015 MRR_FL_CAN_DET_RANGE_RATE_015 MRR_FL_CAN_DET_AMPLITUDE_015 MRR_FL_CAN_DET_RANGE_RATE_021 MRR_FL_CAN_DET_AZIMUTH_020 MRR_FL_CAN_DET_ELEVATION_019 MRR_FL_CAN_DET_HOST_VEH_CLU_0016 MRR_FL_CAN_DET_SUPER_RES_TA_0016 MRR_FL_CAN_DET_CONFID_AZIMU_0014 MRR_FL_CAN_DET_CONFID_ELEVA_0019 MRR_FL_CAN_DET_CONFID_AZIMU_0017 MRR_FL_CAN_DET_VALID_LEVEL_016 MRR_FL_CAN_DET_AMPLITUDE_019 MRR_FL_CAN_DET_AMPLITUDE_016 MRR_FL_CAN_DET_AZIMUTH_019 MRR_FL_CAN_DET_RANGE_017 MRR_FL_CAN_DET_AZIMUTH_016 MRR_FL_CAN_DET_RANGE_RATE_016 MRR_FL_CAN_DET_CONFID_AZIMU_0016 MRR_FL_CAN_SCAN_INDEX_2LSB_016 MRR_FL_CAN_DET_VALID_LEVEL_019 MRR_FL_CAN_DET_HOST_VEH_CLU_0019 MRR_FL_CAN_DET_SUPER_RES_TA_0019 MRR_FL_CAN_DET_ELEVATION_016 MRR_FL_CAN_DET_VALID_LEVEL_017 MRR_FL_CAN_DET_RANGE_018 MRR_FL_CAN_DET_VALID_LEVEL_018 MRR_FL_CAN_DET_SUPER_RES_TA_0018 MRR_FL_CAN_SCAN_INDEX_2LSB_019 MRR_FL_CAN_DET_RANGE_RATE_020 MRR_FL_CAN_DET_VALID_LEVEL_020 MRR_FL_DET_MC_003 MRR_FL_CAN_DET_HOST_VEH_CLU_0017 MRR_FL_CAN_DET_CONFID_AZIMUTH_02 MRR_FL_CAN_DET_RANGE_020 MRR_FL_DET_CRC_003 MRR_FL_CAN_SCAN_INDEX_2LSB_015 MRR_FL_CAN_DET_AMPLITUDE_017 MRR_FL_CAN_SCAN_INDEX_2LSB_017 MRR_FL_CAN_DET_AMPLITUDE_020 MRR_FL_CAN_DET_CONFID_ELEVA_0018 MRR_FL_CAN_DET_ELEVATION_018 MRR_FL_CAN_DET_AZIMUTH_017 MRR_FL_CAN_DET_AMPLITUDE_018 MRR_FL_CAN_DET_RANGE_RATE_019 MRR_FL_CAN_DET_AZIMUTH_015 MRR_FL_CAN_DET_RANGE_RATE_018 MRR_FL_CAN_DET_ELEVATION_017 MRR_FL_CAN_SCAN_INDEX_2LSB_020 MRR_FL_CAN_DET_SUPER_RES_TA_0017 MRR_FL_CAN_DET_RANGE_RATE_017 MRR_FL_CAN_SCAN_INDEX_2LSB_018 MRR_FL_CAN_DET_CONFID_ELEVA_0017 MRR_FL_CAN_DET_CONFID_AZIMU_0015 MRR_FL_CAN_DET_AZIMUTH_018 MRR_FL_CAN_DET_RANGE_019 MRR_FL_CAN_DET_CONFID_ELEVA_0014 MRR_FL_CAN_DET_HOST_VEH_CLU_0014 MRR_FL_CAN_DET_RANGE_021 MRR_FL_CAN_SCAN_INDEX_2LSB_021 MRR_FL_CAN_DET_CONFID_ELEVA_0015 MRR_FL_CAN_DET_AMPLITUDE_021 MRR_FL_CAN_DET_VALID_LEVEL_021 MRR_FL_CAN_DET_HOST_VEH_CLU_0018 MRR_FL_CAN_DET_CONFID_ELEVA_0016 MRR_FL_CAN_DET_ELEVATION_020 MRR_FL_CAN_DET_SUPER_RES_TA_0015 MRR_FL_CAN_DET_HOST_VEH_CLU_0015 MRR_FL_CAN_DET_CONFID_AZIMU_0013 MRR_FL_CAN_DET_RANGE_016 MRR_FL_CAN_DET_AZIMUTH_021 MRR_FL_CAN_DET_ELEVATION_021 MRR_FL_CAN_DET_SUPER_RES_TA_0014;
SIG_GROUP_ 771 MRR_FL_Detection_022_028 1 : MRR_FL_CAN_DET_Near_TARGET_028 MRR_FL_CAN_DET_Near_TARGET_027 MRR_FL_CAN_DET_Near_TARGET_026 MRR_FL_CAN_DET_Near_TARGET_025 MRR_FL_CAN_DET_Near_TARGET_024 MRR_FL_CAN_DET_Near_TARGET_023 MRR_FL_CAN_DET_Near_TARGET_022 MRR_FL_CAN_DET_MID_TARGET_022 MRR_FL_CAN_DET_MID_TARGET_023 MRR_FL_CAN_DET_MID_TARGET_024 MRR_FL_CAN_DET_MID_TARGET_025 MRR_FL_CAN_DET_MID_TARGET_026 MRR_FL_CAN_DET_MID_TARGET_027 MRR_FL_CAN_DET_MID_TARGET_028 MRR_FL_CAN_DET_ELEVATION_022 MRR_FL_CAN_DET_CONFID_AZIMU_0018 MRR_FL_CAN_DET_SUPER_RES_TA_0020 MRR_FL_CAN_DET_CONFID_ELEVA_0020 MRR_FL_CAN_DET_HOST_VEH_CLU_0020 MRR_FL_CAN_DET_VALID_LEVEL_022 MRR_FL_CAN_DET_AZIMUTH_022 MRR_FL_CAN_DET_RANGE_022 MRR_FL_CAN_DET_AMPLITUDE_022 MRR_FL_CAN_SCAN_INDEX_2LSB_022 MRR_FL_CAN_DET_ELEVATION_028 MRR_FL_CAN_DET_SUPER_RES_TA_0021 MRR_FL_CAN_DET_RANGE_028 MRR_FL_CAN_DET_RANGE_RATE_028 MRR_FL_CAN_SCAN_INDEX_2LSB_028 MRR_FL_CAN_DET_RANGE_RATE_027 MRR_FL_CAN_DET_ELEVATION_026 MRR_FL_CAN_DET_CONFID_ELEVA_0023 MRR_FL_CAN_SCAN_INDEX_2LSB_026 MRR_FL_CAN_DET_SUPER_RES_TA_0024 MRR_FL_CAN_DET_RANGE_RATE_025 MRR_FL_CAN_DET_AMPLITUDE_025 MRR_FL_CAN_DET_ELEVATION_024 MRR_FL_CAN_DET_CONFID_ELEVA_0025 MRR_FL_CAN_DET_VALID_LEVEL_026 MRR_FL_CAN_SCAN_INDEX_2LSB_025 MRR_FL_CAN_DET_CONFID_AZIMU_0022 MRR_FL_CAN_DET_SUPER_RES_TA_0023 MRR_FL_CAN_DET_VALID_LEVEL_027 MRR_FL_CAN_DET_CONFID_AZIMU_0019 MRR_FL_CAN_DET_RANGE_RATE_026 MRR_FL_CAN_DET_RANGE_026 MRR_FL_CAN_DET_CONFID_AZIMU_0023 MRR_FL_CAN_DET_AMPLITUDE_024 MRR_FL_CAN_DET_ELEVATION_023 MRR_FL_CAN_DET_RANGE_023 MRR_FL_CAN_DET_CONFID_AZIMU_0024 MRR_FL_CAN_DET_RANGE_RATE_023 MRR_FL_CAN_SCAN_INDEX_2LSB_023 MRR_FL_CAN_DET_AMPLITUDE_023 MRR_FL_CAN_DET_AZIMUTH_023 MRR_FL_CAN_DET_AMPLITUDE_026 MRR_FL_CAN_DET_CONFID_AZIMU_0021 MRR_FL_CAN_DET_HOST_VEH_CLU_0023 MRR_FL_CAN_DET_AZIMUTH_026 MRR_FL_CAN_DET_SUPER_RES_TA_0025 MRR_FL_DET_MC_004 MRR_FL_DET_CRC_004 MRR_FL_CAN_DET_SUPER_RES_TA_0026 MRR_FL_CAN_DET_VALID_LEVEL_025 MRR_FL_CAN_DET_RANGE_024 MRR_FL_CAN_SCAN_INDEX_2LSB_024 MRR_FL_CAN_DET_CONFID_ELEVA_0024 MRR_FL_CAN_DET_HOST_VEH_CLU_0025 MRR_FL_CAN_DET_ELEVATION_025 MRR_FL_CAN_DET_VALID_LEVEL_024 MRR_FL_CAN_DET_CONFID_ELEVA_0026 MRR_FL_CAN_DET_AZIMUTH_025 MRR_FL_CAN_DET_RANGE_025 MRR_FL_CAN_DET_AZIMUTH_024 MRR_FL_CAN_DET_AMPLITUDE_027 MRR_FL_CAN_DET_AMPLITUDE_028 MRR_FL_CAN_DET_RANGE_RATE_024 MRR_FL_CAN_DET_HOST_VEH_CLU_0024 MRR_FL_CAN_DET_HOST_VEH_CLU_0026 MRR_FL_CAN_DET_RANGE_RATE_022 MRR_FL_CAN_DET_AZIMUTH_028 MRR_FL_CAN_DET_CONFID_ELEVA_0021 MRR_FL_CAN_DET_HOST_VEH_CLU_0021 MRR_FL_CAN_DET_CONFID_AZIMU_0020 MRR_FL_CAN_DET_VALID_LEVEL_028 MRR_FL_CAN_DET_RANGE_027 MRR_FL_CAN_DET_CONFID_ELEVA_0022 MRR_FL_CAN_DET_HOST_VEH_CLU_0022 MRR_FL_CAN_DET_ELEVATION_027 MRR_FL_CAN_SCAN_INDEX_2LSB_027 MRR_FL_CAN_DET_SUPER_RES_TA_0022 MRR_FL_CAN_DET_AZIMUTH_027 MRR_FL_CAN_DET_VALID_LEVEL_023;
SIG_GROUP_ 772 MRR_FL_Detection_029_035 1 : MRR_FL_CAN_DET_Near_TARGET_035 MRR_FL_CAN_DET_Near_TARGET_034 MRR_FL_CAN_DET_Near_TARGET_033 MRR_FL_CAN_DET_Near_TARGET_032 MRR_FL_CAN_DET_Near_TARGET_031 MRR_FL_CAN_DET_Near_TARGET_030 MRR_FL_CAN_DET_Near_TARGET_029 MRR_FL_CAN_DET_MID_TARGET_029 MRR_FL_CAN_DET_MID_TARGET_030 MRR_FL_CAN_DET_MID_TARGET_031 MRR_FL_CAN_DET_MID_TARGET_032 MRR_FL_CAN_DET_MID_TARGET_033 MRR_FL_CAN_DET_MID_TARGET_034 MRR_FL_CAN_DET_MID_TARGET_035 MRR_FL_CAN_DET_ELEVATION_029 MRR_FL_CAN_DET_CONFID_AZIMU_0025 MRR_FL_CAN_DET_SUPER_RES_TA_0027 MRR_FL_CAN_DET_CONFID_ELEVA_0027 MRR_FL_CAN_DET_HOST_VEH_CLU_0027 MRR_FL_CAN_DET_AZIMUTH_029 MRR_FL_CAN_DET_RANGE_029 MRR_FL_CAN_DET_RANGE_RATE_029 MRR_FL_CAN_DET_AMPLITUDE_029 MRR_FL_DET_MC_005 MRR_FL_CAN_DET_ELEVATION_035 MRR_FL_CAN_DET_HOST_VEH_CLU_0028 MRR_FL_CAN_DET_CONFID_ELEVA_0029 MRR_FL_CAN_DET_ELEVATION_033 MRR_FL_CAN_DET_AMPLITUDE_032 MRR_FL_CAN_DET_SUPER_RES_TA_0033 MRR_FL_CAN_DET_CONFID_ELEVA_0033 MRR_FL_CAN_DET_HOST_VEH_CLU_0033 MRR_FL_CAN_DET_RANGE_030 MRR_FL_CAN_DET_RANGE_RATE_030 MRR_FL_DET_CRC_005 MRR_FL_CAN_DET_CONFID_AZIMUTH_03 MRR_FL_CAN_DET_SUPER_RES_TA_0028 MRR_FL_CAN_DET_AZIMUTH_035 MRR_FL_CAN_SCAN_INDEX_2LSB_029 MRR_FL_CAN_DET_AMPLITUDE_030 MRR_FL_CAN_DET_VALID_LEVEL_030 MRR_FL_CAN_DET_AMPLITUDE_031 MRR_FL_CAN_DET_RANGE_034 MRR_FL_CAN_DET_RANGE_RATE_033 MRR_FL_CAN_SCAN_INDEX_2LSB_031 MRR_FL_CAN_DET_CONFID_AZIMU_0029 MRR_FL_CAN_DET_VALID_LEVEL_033 MRR_FL_CAN_SCAN_INDEX_2LSB_030 MRR_FL_CAN_DET_RANGE_031 MRR_FL_CAN_DET_AZIMUTH_032 MRR_FL_CAN_DET_SUPER_RES_TA_0032 MRR_FL_CAN_DET_ELEVATION_031 MRR_FL_CAN_SCAN_INDEX_2LSB_032 MRR_FL_CAN_DET_CONFID_ELEVA_0032 MRR_FL_CAN_DET_CONFID_AZIMU_0026 MRR_FL_CAN_SCAN_INDEX_2LSB_034 MRR_FL_CAN_DET_CONFID_ELEVA_0028 MRR_FL_CAN_DET_CONFID_AZIMU_0030 MRR_FL_CAN_DET_HOST_VEH_CLU_0032 MRR_FL_CAN_DET_ELEVATION_030 MRR_FL_CAN_DET_AZIMUTH_033 MRR_FL_CAN_DET_VALID_LEVEL_031 MRR_FL_CAN_DET_AMPLITUDE_034 MRR_FL_CAN_DET_RANGE_RATE_034 MRR_FL_CAN_DET_RANGE_RATE_031 MRR_FL_CAN_DET_RANGE_033 MRR_FL_CAN_DET_AZIMUTH_031 MRR_FL_CAN_DET_CONFID_AZIMU_0028 MRR_FL_CAN_DET_HOST_VEH_CLU_0029 MRR_FL_CAN_DET_CONFID_ELEVA_0031 MRR_FL_CAN_DET_SUPER_RES_TA_0031 MRR_FL_CAN_DET_RANGE_032 MRR_FL_CAN_DET_HOST_VEH_CLU_0031 MRR_FL_CAN_DET_ELEVATION_032 MRR_FL_CAN_DET_VALID_LEVEL_034 MRR_FL_CAN_SCAN_INDEX_2LSB_033 MRR_FL_CAN_DET_AZIMUTH_034 MRR_FL_CAN_DET_RANGE_035 MRR_FL_CAN_DET_SUPER_RES_TA_0029 MRR_FL_CAN_DET_CONFID_AZIMU_0027 MRR_FL_CAN_DET_CONFID_ELEVA_0030 MRR_FL_CAN_DET_VALID_LEVEL_029 MRR_FL_CAN_DET_AZIMUTH_030 MRR_FL_CAN_DET_AMPLITUDE_035 MRR_FL_CAN_DET_RANGE_RATE_035 MRR_FL_CAN_DET_AMPLITUDE_033 MRR_FL_CAN_DET_VALID_LEVEL_032 MRR_FL_CAN_DET_SUPER_RES_TA_0030 MRR_FL_CAN_SCAN_INDEX_2LSB_035 MRR_FL_CAN_DET_ELEVATION_034 MRR_FL_CAN_DET_VALID_LEVEL_035 MRR_FL_CAN_DET_RANGE_RATE_032 MRR_FL_CAN_DET_HOST_VEH_CLU_0030;
SIG_GROUP_ 773 MRR_FL_Detection_036_042 1 : MRR_FL_CAN_DET_Near_TARGET_042 MRR_FL_CAN_DET_Near_TARGET_041 MRR_FL_CAN_DET_Near_TARGET_040 MRR_FL_CAN_DET_Near_TARGET_039 MRR_FL_CAN_DET_Near_TARGET_038 MRR_FL_CAN_DET_Near_TARGET_037 MRR_FL_CAN_DET_Near_TARGET_036 MRR_FL_CAN_DET_MID_TARGET_036 MRR_FL_CAN_DET_MID_TARGET_037 MRR_FL_CAN_DET_MID_TARGET_038 MRR_FL_CAN_DET_MID_TARGET_039 MRR_FL_CAN_DET_MID_TARGET_040 MRR_FL_CAN_DET_MID_TARGET_041 MRR_FL_CAN_DET_MID_TARGET_042 MRR_FL_CAN_DET_ELEVATION_036 MRR_FL_CAN_DET_CONFID_AZIMU_0031 MRR_FL_CAN_DET_SUPER_RES_TA_0034 MRR_FL_CAN_DET_CONFID_ELEVA_0034 MRR_FL_CAN_DET_HOST_VEH_CLU_0034 MRR_FL_CAN_DET_VALID_LEVEL_036 MRR_FL_CAN_DET_RANGE_RATE_036 MRR_FL_CAN_DET_AMPLITUDE_036 MRR_FL_CAN_DET_AZIMUTH_038 MRR_FL_CAN_SCAN_INDEX_2LSB_038 MRR_FL_CAN_DET_SUPER_RES_TA_0040 MRR_FL_CAN_DET_AZIMUTH_037 MRR_FL_CAN_DET_CONFID_AZIMU_0036 MRR_FL_CAN_DET_RANGE_RATE_037 MRR_FL_CAN_SCAN_INDEX_2LSB_037 MRR_FL_CAN_DET_AMPLITUDE_037 MRR_FL_CAN_DET_VALID_LEVEL_037 MRR_FL_CAN_DET_RANGE_037 MRR_FL_CAN_DET_HOST_VEH_CLU_0040 MRR_FL_CAN_DET_CONFID_ELEVA_0039 MRR_FL_CAN_DET_SUPER_RES_TA_0035 MRR_FL_CAN_DET_HOST_VEH_CLU_0036 MRR_FL_CAN_DET_AZIMUTH_036 MRR_FL_CAN_DET_SUPER_RES_TA_0036 MRR_FL_CAN_SCAN_INDEX_2LSB_036 MRR_FL_CAN_DET_AZIMUTH_042 MRR_FL_CAN_DET_HOST_VEH_CLU_0035 MRR_FL_CAN_DET_RANGE_042 MRR_FL_DET_MC_006 MRR_FL_CAN_SCAN_INDEX_2LSB_042 MRR_FL_CAN_DET_SUPER_RES_TA_0039 MRR_FL_CAN_SCAN_INDEX_2LSB_039 MRR_FL_CAN_DET_ELEVATION_038 MRR_FL_CAN_DET_SUPER_RES_TA_0038 MRR_FL_CAN_DET_RANGE_041 MRR_FL_CAN_DET_AZIMUTH_039 MRR_FL_CAN_DET_VALID_LEVEL_039 MRR_FL_CAN_DET_VALID_LEVEL_041 MRR_FL_CAN_DET_AMPLITUDE_041 MRR_FL_CAN_DET_RANGE_039 MRR_FL_CAN_DET_HOST_VEH_CLU_0038 MRR_FL_CAN_DET_RANGE_RATE_041 MRR_FL_DET_CRC_006 MRR_FL_CAN_SCAN_INDEX_2LSB_041 MRR_FL_CAN_DET_RANGE_RATE_038 MRR_FL_CAN_DET_HOST_VEH_CLU_0039 MRR_FL_CAN_DET_RANGE_038 MRR_FL_CAN_DET_AMPLITUDE_039 MRR_FL_CAN_DET_CONFID_AZIMU_0032 MRR_FL_CAN_DET_AZIMUTH_041 MRR_FL_CAN_DET_CONFID_ELEVA_0036 MRR_FL_CAN_DET_CONFID_ELEVA_0035 MRR_FL_CAN_DET_VALID_LEVEL_040 MRR_FL_CAN_DET_VALID_LEVEL_042 MRR_FL_CAN_SCAN_INDEX_2LSB_040 MRR_FL_CAN_DET_RANGE_RATE_042 MRR_FL_CAN_DET_CONFID_AZIMU_0033 MRR_FL_CAN_DET_ELEVATION_040 MRR_FL_CAN_DET_AZIMUTH_040 MRR_FL_CAN_DET_ELEVATION_039 MRR_FL_CAN_DET_ELEVATION_041 MRR_FL_CAN_DET_RANGE_036 MRR_FL_CAN_DET_VALID_LEVEL_038 MRR_FL_CAN_DET_CONFID_AZIMU_0034 MRR_FL_CAN_DET_RANGE_RATE_039 MRR_FL_CAN_DET_RANGE_RATE_040 MRR_FL_CAN_DET_RANGE_040 MRR_FL_CAN_DET_CONFID_ELEVA_0037 MRR_FL_CAN_DET_AMPLITUDE_040 MRR_FL_CAN_DET_ELEVATION_042 MRR_FL_CAN_DET_ELEVATION_037 MRR_FL_CAN_DET_CONFID_ELEVA_0038 MRR_FL_CAN_DET_CONFID_AZIMU_0035 MRR_FL_CAN_DET_SUPER_RES_TA_0037 MRR_FL_CAN_DET_CONFID_AZIMUTH_04 MRR_FL_CAN_DET_CONFID_ELEVA_0040 MRR_FL_CAN_DET_HOST_VEH_CLU_0037 MRR_FL_CAN_DET_AMPLITUDE_042 MRR_FL_CAN_DET_AMPLITUDE_038;
SIG_GROUP_ 774 MRR_FL_Detection_043_049 1 : MRR_FL_CAN_DET_Near_TARGET_049 MRR_FL_CAN_DET_Near_TARGET_048 MRR_FL_CAN_DET_Near_TARGET_047 MRR_FL_CAN_DET_Near_TARGET_046 MRR_FL_CAN_DET_Near_TARGET_045 MRR_FL_CAN_DET_Near_TARGET_044 MRR_FL_CAN_DET_Near_TARGET_043 MRR_FL_CAN_DET_MID_TARGET_043 MRR_FL_CAN_DET_MID_TARGET_044 MRR_FL_CAN_DET_MID_TARGET_045 MRR_FL_CAN_DET_MID_TARGET_046 MRR_FL_CAN_DET_MID_TARGET_047 MRR_FL_CAN_DET_MID_TARGET_048 MRR_FL_CAN_DET_MID_TARGET_049 MRR_FL_CAN_DET_ELEVATION_043 MRR_FL_CAN_DET_CONFID_AZIMU_0037 MRR_FL_CAN_DET_SUPER_RES_TA_0041 MRR_FL_CAN_DET_CONFID_ELEVA_0041 MRR_FL_CAN_DET_HOST_VEH_CLU_0041 MRR_FL_CAN_DET_VALID_LEVEL_043 MRR_FL_CAN_DET_AZIMUTH_043 MRR_FL_CAN_DET_RANGE_043 MRR_FL_CAN_DET_RANGE_RATE_043 MRR_FL_CAN_DET_AMPLITUDE_043 MRR_FL_CAN_DET_AMPLITUDE_044 MRR_FL_CAN_DET_RANGE_044 MRR_FL_CAN_SCAN_INDEX_2LSB_044 MRR_FL_CAN_DET_HOST_VEH_CLU_0047 MRR_FL_CAN_DET_CONFID_AZIMU_0043 MRR_FL_CAN_DET_RANGE_RATE_044 MRR_FL_CAN_DET_ELEVATION_049 MRR_FL_CAN_DET_SUPER_RES_TA_0047 MRR_FL_CAN_DET_RANGE_RATE_049 MRR_FL_CAN_DET_AZIMUTH_047 MRR_FL_CAN_DET_VALID_LEVEL_044 MRR_FL_CAN_DET_CONFID_AZIMU_0038 MRR_FL_CAN_DET_AMPLITUDE_045 MRR_FL_CAN_DET_AZIMUTH_044 MRR_FL_CAN_DET_VALID_LEVEL_045 MRR_FL_CAN_DET_RANGE_049 MRR_FL_CAN_DET_AZIMUTH_049 MRR_FL_DET_MC_007 MRR_FL_CAN_SCAN_INDEX_2LSB_043 MRR_FL_DET_CRC_007 MRR_FL_CAN_DET_SUPER_RES_TA_0046 MRR_FL_CAN_DET_RANGE_RATE_045 MRR_FL_CAN_DET_ELEVATION_047 MRR_FL_CAN_DET_VALID_LEVEL_048 MRR_FL_CAN_DET_RANGE_RATE_047 MRR_FL_CAN_DET_HOST_VEH_CLU_0044 MRR_FL_CAN_DET_RANGE_047 MRR_FL_CAN_DET_CONFID_ELEVA_0046 MRR_FL_CAN_DET_ELEVATION_045 MRR_FL_CAN_DET_CONFID_AZIMU_0040 MRR_FL_CAN_DET_RANGE_RATE_046 MRR_FL_CAN_DET_RANGE_046 MRR_FL_CAN_SCAN_INDEX_2LSB_046 MRR_FL_CAN_DET_VALID_LEVEL_047 MRR_FL_CAN_DET_ELEVATION_044 MRR_FL_CAN_DET_SUPER_RES_TA_0044 MRR_FL_CAN_DET_CONFID_ELEVA_0047 MRR_FL_CAN_DET_CONFID_ELEVA_0044 MRR_FL_CAN_SCAN_INDEX_2LSB_045 MRR_FL_CAN_DET_RANGE_048 MRR_FL_CAN_DET_RANGE_045 MRR_FL_CAN_DET_ELEVATION_046 MRR_FL_CAN_DET_CONFID_ELEVA_0045 MRR_FL_CAN_DET_RANGE_RATE_048 MRR_FL_CAN_DET_HOST_VEH_CLU_0046 MRR_FL_CAN_SCAN_INDEX_2LSB_048 MRR_FL_CAN_DET_VALID_LEVEL_046 MRR_FL_CAN_DET_CONFID_AZIMU_0041 MRR_FL_CAN_SCAN_INDEX_2LSB_049 MRR_FL_CAN_DET_HOST_VEH_CLU_0045 MRR_FL_CAN_DET_AMPLITUDE_049 MRR_FL_CAN_SCAN_INDEX_2LSB_047 MRR_FL_CAN_DET_SUPER_RES_TA_0045 MRR_FL_CAN_DET_CONFID_AZIMU_0039 MRR_FL_CAN_DET_AZIMUTH_046 MRR_FL_CAN_DET_VALID_LEVEL_049 MRR_FL_CAN_DET_AMPLITUDE_047 MRR_FL_CAN_DET_SUPER_RES_TA_0043 MRR_FL_CAN_DET_ELEVATION_048 MRR_FL_CAN_DET_AMPLITUDE_046 MRR_FL_CAN_DET_AZIMUTH_048 MRR_FL_CAN_DET_CONFID_AZIMU_0042 MRR_FL_CAN_DET_HOST_VEH_CLU_0043 MRR_FL_CAN_DET_AZIMUTH_045 MRR_FL_CAN_DET_CONFID_ELEVA_0043 MRR_FL_CAN_DET_AMPLITUDE_048 MRR_FL_CAN_DET_HOST_VEH_CLU_0042 MRR_FL_CAN_DET_CONFID_ELEVA_0042 MRR_FL_CAN_DET_SUPER_RES_TA_0042;
